[part 2 of 12: package /E40_Platform_System_SystemPackage/Components]
AUTOSAR XML (schema 4-2-1)
package /E40_Platform_System_SystemPackage/Components  (continued)
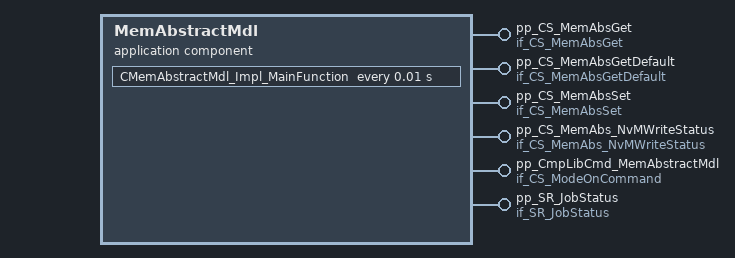
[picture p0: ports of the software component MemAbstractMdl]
  application sw component type MemAbstractMdl
    6 x provide port:
      pp_CS_MemAbsGet: provided-interface=if_CS_MemAbsGet
        provided-com-specs:
          operation=Get_BsConst_Audio_Element, queue-length=1
          operation=Get_BsConst_BsConst_Illumination_ReservedByte, queue-length=1
          operation=Get_BsConst_BsConst_Illumination_ReservedByte_SafeCopy1, queue-length=1
          operation=Get_BsConst_BsConst_Illumination_ReservedByte_SafeCopy2, queue-length=1
          operation=Get_BsConst_Communication_Element, queue-length=1
          operation=Get_BsConst_Compensation_Line_Shift_b, queue-length=1
          operation=Get_BsConst_Compensation_Line_Shift_b_SafeCopy1, queue-length=1
          operation=Get_BsConst_Compensation_Line_Shift_b_SafeCopy2, queue-length=1
          operation=Get_BsConst_Compensation_Line_Slope_m, queue-length=1
          operation=Get_BsConst_Compensation_Line_Slope_m_SafeCopy1, queue-length=1
          operation=Get_BsConst_Compensation_Line_Slope_m_SafeCopy2, queue-length=1
          operation=Get_BsConst_Derating_Backlight_Disable, queue-length=1
          operation=Get_BsConst_Derating_Backlight_Disable_SafeCopy1, queue-length=1
          operation=Get_BsConst_Derating_Backlight_Disable_SafeCopy2, queue-length=1
          operation=Get_BsConst_Display_Illum_Max_Level, queue-length=1
          operation=Get_BsConst_Display_Illum_Max_Level_SafeCopy1, queue-length=1
          operation=Get_BsConst_Display_Illum_Max_Level_SafeCopy2, queue-length=1
          operation=Get_BsConst_EngOffTimer_Element, queue-length=1
          operation=Get_BsConst_FuelGauge_Element, queue-length=1
          operation=Get_BsConst_Lookup_Curve_HotSpot_Coef_X, queue-length=1
          operation=Get_BsConst_Lookup_Curve_HotSpot_Coef_X_SafeCopy1, queue-length=1
          operation=Get_BsConst_Lookup_Curve_HotSpot_Coef_X_SafeCopy2, queue-length=1
          operation=Get_BsConst_Lookup_Curve_HotSpot_Coef_Y, queue-length=1
          operation=Get_BsConst_Lookup_Curve_HotSpot_Coef_Y_SafeCopy1, queue-length=1
          operation=Get_BsConst_Lookup_Curve_HotSpot_Coef_Y_SafeCopy2, queue-length=1
          operation=Get_BsConst_OilGauge_Element, queue-length=1
          operation=Get_BsConst_PCB_Temperature_Sensor_Conv, queue-length=1
          operation=Get_BsConst_PCB_Temperature_Sensor_Conv_SafeCopy1, queue-length=1
          operation=Get_BsConst_PCB_Temperature_Sensor_Conv_SafeCopy2, queue-length=1
          operation=Get_BsConst_PWM_boost_bypass_duty, queue-length=1
          operation=Get_BsConst_PWM_boost_bypass_duty_SafeCopy1, queue-length=1
          operation=Get_BsConst_PWM_boost_bypass_duty_SafeCopy2, queue-length=1
          operation=Get_BsConst_PowerGauge_Element, queue-length=1
          operation=Get_BsConst_Power_Element, queue-length=1
          operation=Get_BsConst_RealTimeClock_Element, queue-length=1
          operation=Get_BsConst_ServiceReminder_Element, queue-length=1
          operation=Get_BsConst_SpeedoGauge_Element, queue-length=1
          operation=Get_BsConst_TachoGauge_Element, queue-length=1
          operation=Get_BsConst_TempGauge_Element, queue-length=1
          operation=Get_BsConst_Temp_Threshold_Hysteresis_Derating, queue-length=1
          operation=Get_BsConst_Temp_Threshold_Hysteresis_Derating_SafeCopy1, queue-length=1
          operation=Get_BsConst_Temp_Threshold_Hysteresis_Derating_SafeCopy2, queue-length=1
          operation=Get_BsConst_Temperature_Sensor_Conv, queue-length=1
          operation=Get_BsConst_Temperature_Sensor_Conv_SafeCopy1, queue-length=1
          operation=Get_BsConst_Temperature_Sensor_Conv_SafeCopy2, queue-length=1
          operation=Get_BsConst_TripComputer_Element, queue-length=1
          operation=Get_BsConst_Warning_Element, queue-length=1
          operation=Get_BsCys_Certicificate_Element, queue-length=1
          operation=Get_BsDiag_Dtc_Element, queue-length=1
          operation=Get_BsDiag_ErrorRecord_Element, queue-length=1
          operation=Get_BsReten_Audio_Element, queue-length=1
          operation=Get_BsReten_Communication_Element, queue-length=1
          operation=Get_BsReten_Display_Element, queue-length=1
          operation=Get_BsReten_Gauges_Element, queue-length=1
          operation=Get_BsReten_Illumination_Element, queue-length=1
          operation=Get_BsReten_Odometer_Element, queue-length=1
          operation=Get_BsReten_Personalization_Element, queue-length=1
          operation=Get_BsReten_Power_Element, queue-length=1
          operation=Get_BsReten_RealTimeClock_Element, queue-length=1
          operation=Get_BsReten_Tripcomputer_Element, queue-length=1
          operation=Get_BsReten_Warning_Element, queue-length=1
          operation=Get_BsRt_CusDlt_Element, queue-length=1
          operation=Get_BsRt_FuelGauge_Element, queue-length=1
          operation=Get_BsRt_Illumination_Element, queue-length=1
          operation=Get_BsRt_Odometer_Element, queue-length=1
          operation=Get_BsRt_OilGauge_Element, queue-length=1
          operation=Get_BsRt_Personalization_Element, queue-length=1
          operation=Get_BsRt_PowerGauge_Element, queue-length=1
          operation=Get_BsRt_RealTimeClock_Element, queue-length=1
          operation=Get_BsRt_SpeedoGauge_Element, queue-length=1
          operation=Get_BsRt_TachoGauge_Element, queue-length=1
          operation=Get_BsRt_TempGauge_Element, queue-length=1
          operation=Get_BsRt_TripComputer_Element, queue-length=1
          operation=Get_BsRt_Warning_Element, queue-length=1
          operation=Get_BsShare_AssemblyManufacturingDate, queue-length=1
          operation=Get_BsShare_AssemblyPlantNumber, queue-length=1
          operation=Get_BsShare_EcuPartNumber_Element, queue-length=1
          operation=Get_BsShare_HWModification, queue-length=1
          operation=Get_BsShare_PCBSerialNumber, queue-length=1
          operation=Get_BsShare_ProductSerialNumber, queue-length=1
          operation=Get_BsShare_SMTManufacturingDate, queue-length=1
          operation=Get_BsShare_SMTPlantNumber, queue-length=1
          operation=Get_BsShare_SwUpdFotaFinPrint_Element, queue-length=1
          operation=Get_BsShare_SwUpdFotaMode_Element, queue-length=1
          operation=Get_BsShare_SwUpdFotaStatus_Element, queue-length=1
          operation=Get_BsShare_SwUpdFotadecrypt_Element, queue-length=1
          operation=Get_BsShare_SwUpdReflash_Element, queue-length=1
          operation=Get_BsShare_VehicleConfig_Element, queue-length=1
          operation=Get_BsShare_VisMeet_EOLEntry_Element, queue-length=1
          operation=Get_BsShare_VisMeet_Element, queue-length=1
          operation=Get_BsShare_VisteonPCBPartNumber, queue-length=1
          operation=Get_BsShare_VisteonPartNumber, queue-length=1
          operation=Get_RefCys_Certicificate1_Element, queue-length=1
          operation=Get_RefCys_Certicificate_Element, queue-length=1
      pp_CS_MemAbsGetDefault: provided-interface=if_CS_MemAbsGetDefault
        provided-com-specs:
          operation=Get_Default_BsConst_Audio_Element, queue-length=1
          operation=Get_Default_BsConst_BsConst_Illumination_ReservedByte, queue-length=1
          operation=Get_Default_BsConst_BsConst_Illumination_ReservedByte_SafeCopy1, queue-length=1
          operation=Get_Default_BsConst_BsConst_Illumination_ReservedByte_SafeCopy2, queue-length=1
          operation=Get_Default_BsConst_Communication_Element, queue-length=1
          operation=Get_Default_BsConst_Compensation_Line_Shift_b, queue-length=1
          operation=Get_Default_BsConst_Compensation_Line_Shift_b_SafeCopy1, queue-length=1
          operation=Get_Default_BsConst_Compensation_Line_Shift_b_SafeCopy2, queue-length=1
          operation=Get_Default_BsConst_Compensation_Line_Slope_m, queue-length=1
          operation=Get_Default_BsConst_Compensation_Line_Slope_m_SafeCopy1, queue-length=1
          operation=Get_Default_BsConst_Compensation_Line_Slope_m_SafeCopy2, queue-length=1
          operation=Get_Default_BsConst_Derating_Backlight_Disable, queue-length=1
          operation=Get_Default_BsConst_Derating_Backlight_Disable_SafeCopy1, queue-length=1
          operation=Get_Default_BsConst_Derating_Backlight_Disable_SafeCopy2, queue-length=1
          operation=Get_Default_BsConst_Display_Illum_Max_Level, queue-length=1
          operation=Get_Default_BsConst_Display_Illum_Max_Level_SafeCopy1, queue-length=1
          operation=Get_Default_BsConst_Display_Illum_Max_Level_SafeCopy2, queue-length=1
          operation=Get_Default_BsConst_EngOffTimer_Element, queue-length=1
          operation=Get_Default_BsConst_FuelGauge_Element, queue-length=1
          operation=Get_Default_BsConst_Lookup_Curve_HotSpot_Coef_X, queue-length=1
          operation=Get_Default_BsConst_Lookup_Curve_HotSpot_Coef_X_SafeCopy1, queue-length=1
          operation=Get_Default_BsConst_Lookup_Curve_HotSpot_Coef_X_SafeCopy2, queue-length=1
          operation=Get_Default_BsConst_Lookup_Curve_HotSpot_Coef_Y, queue-length=1
          operation=Get_Default_BsConst_Lookup_Curve_HotSpot_Coef_Y_SafeCopy1, queue-length=1
          operation=Get_Default_BsConst_Lookup_Curve_HotSpot_Coef_Y_SafeCopy2, queue-length=1
          operation=Get_Default_BsConst_OilGauge_Element, queue-length=1
          operation=Get_Default_BsConst_PCB_Temperature_Sensor_Conv, queue-length=1
          operation=Get_Default_BsConst_PCB_Temperature_Sensor_Conv_SafeCopy1, queue-length=1
          operation=Get_Default_BsConst_PCB_Temperature_Sensor_Conv_SafeCopy2, queue-length=1
          operation=Get_Default_BsConst_PWM_boost_bypass_duty, queue-length=1
          operation=Get_Default_BsConst_PWM_boost_bypass_duty_SafeCopy1, queue-length=1
          operation=Get_Default_BsConst_PWM_boost_bypass_duty_SafeCopy2, queue-length=1
          operation=Get_Default_BsConst_PowerGauge_Element, queue-length=1
          operation=Get_Default_BsConst_Power_Element, queue-length=1
          operation=Get_Default_BsConst_RealTimeClock_Element, queue-length=1
          operation=Get_Default_BsConst_ServiceReminder_Element, queue-length=1
          operation=Get_Default_BsConst_SpeedoGauge_Element, queue-length=1
          operation=Get_Default_BsConst_TachoGauge_Element, queue-length=1
          operation=Get_Default_BsConst_TempGauge_Element, queue-length=1
          operation=Get_Default_BsConst_Temp_Threshold_Hysteresis_Derating, queue-length=1
          operation=Get_Default_BsConst_Temp_Threshold_Hysteresis_Derating_SafeCopy1, queue-length=1
          operation=Get_Default_BsConst_Temp_Threshold_Hysteresis_Derating_SafeCopy2, queue-length=1
          operation=Get_Default_BsConst_Temperature_Sensor_Conv, queue-length=1
          operation=Get_Default_BsConst_Temperature_Sensor_Conv_SafeCopy1, queue-length=1
          operation=Get_Default_BsConst_Temperature_Sensor_Conv_SafeCopy2, queue-length=1
          operation=Get_Default_BsConst_TripComputer_Element, queue-length=1
          operation=Get_Default_BsConst_Warning_Element, queue-length=1
          operation=Get_Default_BsCys_Certicificate_Element, queue-length=1
          operation=Get_Default_BsDiag_Dtc_Element, queue-length=1
          operation=Get_Default_BsDiag_ErrorRecord_Element, queue-length=1
          operation=Get_Default_BsReten_Audio_Element, queue-length=1
          operation=Get_Default_BsReten_Communication_Element, queue-length=1
          operation=Get_Default_BsReten_Display_Element, queue-length=1
          operation=Get_Default_BsReten_Gauges_Element, queue-length=1
          operation=Get_Default_BsReten_Illumination_Element, queue-length=1
          operation=Get_Default_BsReten_Odometer_Element, queue-length=1
          operation=Get_Default_BsReten_Personalization_Element, queue-length=1
          operation=Get_Default_BsReten_Power_Element, queue-length=1
          operation=Get_Default_BsReten_RealTimeClock_Element, queue-length=1
          operation=Get_Default_BsReten_Tripcomputer_Element, queue-length=1
          operation=Get_Default_BsReten_Warning_Element, queue-length=1
          operation=Get_Default_BsRt_CusDlt_Element, queue-length=1
          operation=Get_Default_BsRt_FuelGauge_Element, queue-length=1
          operation=Get_Default_BsRt_Illumination_Element, queue-length=1
          operation=Get_Default_BsRt_Odometer_Element, queue-length=1
          operation=Get_Default_BsRt_OilGauge_Element, queue-length=1
          operation=Get_Default_BsRt_Personalization_Element, queue-length=1
          operation=Get_Default_BsRt_PowerGauge_Element, queue-length=1
          operation=Get_Default_BsRt_RealTimeClock_Element, queue-length=1
          operation=Get_Default_BsRt_SpeedoGauge_Element, queue-length=1
          operation=Get_Default_BsRt_TachoGauge_Element, queue-length=1
          operation=Get_Default_BsRt_TempGauge_Element, queue-length=1
          operation=Get_Default_BsRt_TripComputer_Element, queue-length=1
          operation=Get_Default_BsRt_Warning_Element, queue-length=1
          operation=Get_Default_BsShare_AssemblyManufacturingDate, queue-length=1
          operation=Get_Default_BsShare_AssemblyPlantNumber, queue-length=1
          operation=Get_Default_BsShare_EcuPartNumber_Element, queue-length=1
          operation=Get_Default_BsShare_HWModification, queue-length=1
          operation=Get_Default_BsShare_PCBSerialNumber, queue-length=1
          operation=Get_Default_BsShare_ProductSerialNumber, queue-length=1
          operation=Get_Default_BsShare_SMTManufacturingDate, queue-length=1
          operation=Get_Default_BsShare_SMTPlantNumber, queue-length=1
          operation=Get_Default_BsShare_SwUpdFotaFinPrint_Element, queue-length=1
          operation=Get_Default_BsShare_SwUpdFotaMode_Element, queue-length=1
          operation=Get_Default_BsShare_SwUpdFotaStatus_Element, queue-length=1
          operation=Get_Default_BsShare_SwUpdFotadecrypt_Element, queue-length=1
          operation=Get_Default_BsShare_SwUpdReflash_Element, queue-length=1
          operation=Get_Default_BsShare_VehicleConfig_Element, queue-length=1
          operation=Get_Default_BsShare_VisMeet_EOLEntry_Element, queue-length=1
          operation=Get_Default_BsShare_VisMeet_Element, queue-length=1
          operation=Get_Default_BsShare_VisteonPCBPartNumber, queue-length=1
          operation=Get_Default_BsShare_VisteonPartNumber, queue-length=1
          operation=Get_Default_RefCys_Certicificate1_Element, queue-length=1
          operation=Get_Default_RefCys_Certicificate_Element, queue-length=1
      pp_CS_MemAbsSet: provided-interface=if_CS_MemAbsSet
        provided-com-specs:
          operation=Set_BsConst_Audio_Element, queue-length=1
          operation=Set_BsConst_BsConst_Illumination_ReservedByte, queue-length=1
          operation=Set_BsConst_BsConst_Illumination_ReservedByte_SafeCopy1, queue-length=1
          operation=Set_BsConst_BsConst_Illumination_ReservedByte_SafeCopy2, queue-length=1
          operation=Set_BsConst_Communication_Element, queue-length=1
          operation=Set_BsConst_Compensation_Line_Shift_b, queue-length=1
          operation=Set_BsConst_Compensation_Line_Shift_b_SafeCopy1, queue-length=1
          operation=Set_BsConst_Compensation_Line_Shift_b_SafeCopy2, queue-length=1
          operation=Set_BsConst_Compensation_Line_Slope_m, queue-length=1
          operation=Set_BsConst_Compensation_Line_Slope_m_SafeCopy1, queue-length=1
          operation=Set_BsConst_Compensation_Line_Slope_m_SafeCopy2, queue-length=1
          operation=Set_BsConst_Derating_Backlight_Disable, queue-length=1
          operation=Set_BsConst_Derating_Backlight_Disable_SafeCopy1, queue-length=1
          operation=Set_BsConst_Derating_Backlight_Disable_SafeCopy2, queue-length=1
          operation=Set_BsConst_Display_Illum_Max_Level, queue-length=1
          operation=Set_BsConst_Display_Illum_Max_Level_SafeCopy1, queue-length=1
          operation=Set_BsConst_Display_Illum_Max_Level_SafeCopy2, queue-length=1
          operation=Set_BsConst_EngOffTimer_Element, queue-length=1
          operation=Set_BsConst_FuelGauge_Element, queue-length=1
          operation=Set_BsConst_Lookup_Curve_HotSpot_Coef_X, queue-length=1
          operation=Set_BsConst_Lookup_Curve_HotSpot_Coef_X_SafeCopy1, queue-length=1
          operation=Set_BsConst_Lookup_Curve_HotSpot_Coef_X_SafeCopy2, queue-length=1
          operation=Set_BsConst_Lookup_Curve_HotSpot_Coef_Y, queue-length=1
          operation=Set_BsConst_Lookup_Curve_HotSpot_Coef_Y_SafeCopy1, queue-length=1
          operation=Set_BsConst_Lookup_Curve_HotSpot_Coef_Y_SafeCopy2, queue-length=1
          operation=Set_BsConst_OilGauge_Element, queue-length=1
          operation=Set_BsConst_PCB_Temperature_Sensor_Conv, queue-length=1
          operation=Set_BsConst_PCB_Temperature_Sensor_Conv_SafeCopy1, queue-length=1
          operation=Set_BsConst_PCB_Temperature_Sensor_Conv_SafeCopy2, queue-length=1
          operation=Set_BsConst_PWM_boost_bypass_duty, queue-length=1
          operation=Set_BsConst_PWM_boost_bypass_duty_SafeCopy1, queue-length=1
          operation=Set_BsConst_PWM_boost_bypass_duty_SafeCopy2, queue-length=1
          operation=Set_BsConst_PowerGauge_Element, queue-length=1
          operation=Set_BsConst_Power_Element, queue-length=1
          operation=Set_BsConst_RealTimeClock_Element, queue-length=1
          operation=Set_BsConst_ServiceReminder_Element, queue-length=1
          operation=Set_BsConst_SpeedoGauge_Element, queue-length=1
          operation=Set_BsConst_TachoGauge_Element, queue-length=1
          operation=Set_BsConst_TempGauge_Element, queue-length=1
          operation=Set_BsConst_Temp_Threshold_Hysteresis_Derating, queue-length=1
          operation=Set_BsConst_Temp_Threshold_Hysteresis_Derating_SafeCopy1, queue-length=1
          operation=Set_BsConst_Temp_Threshold_Hysteresis_Derating_SafeCopy2, queue-length=1
          operation=Set_BsConst_Temperature_Sensor_Conv, queue-length=1
          operation=Set_BsConst_Temperature_Sensor_Conv_SafeCopy1, queue-length=1
          operation=Set_BsConst_Temperature_Sensor_Conv_SafeCopy2, queue-length=1
          operation=Set_BsConst_TripComputer_Element, queue-length=1
          operation=Set_BsConst_Warning_Element, queue-length=1
          operation=Set_BsCys_Certicificate_Element, queue-length=1
          operation=Set_BsDiag_Dtc_Element, queue-length=1
          operation=Set_BsDiag_ErrorRecord_Element, queue-length=1
          operation=Set_BsReten_Audio_Element, queue-length=1
          operation=Set_BsReten_Communication_Element, queue-length=1
          operation=Set_BsReten_Display_Element, queue-length=1
          operation=Set_BsReten_Gauges_Element, queue-length=1
          operation=Set_BsReten_Illumination_Element, queue-length=1
          operation=Set_BsReten_Odometer_Element, queue-length=1
          operation=Set_BsReten_Personalization_Element, queue-length=1
          operation=Set_BsReten_Power_Element, queue-length=1
          operation=Set_BsReten_RealTimeClock_Element, queue-length=1
          operation=Set_BsReten_Tripcomputer_Element, queue-length=1
          operation=Set_BsReten_Warning_Element, queue-length=1
          operation=Set_BsRt_CusDlt_Element, queue-length=1
          operation=Set_BsRt_FuelGauge_Element, queue-length=1
          operation=Set_BsRt_Illumination_Element, queue-length=1
          operation=Set_BsRt_Odometer_Element, queue-length=1
          operation=Set_BsRt_OilGauge_Element, queue-length=1
          operation=Set_BsRt_Personalization_Element, queue-length=1
          operation=Set_BsRt_PowerGauge_Element, queue-length=1
          operation=Set_BsRt_RealTimeClock_Element, queue-length=1
          operation=Set_BsRt_SpeedoGauge_Element, queue-length=1
          operation=Set_BsRt_TachoGauge_Element, queue-length=1
          operation=Set_BsRt_TempGauge_Element, queue-length=1
          operation=Set_BsRt_TripComputer_Element, queue-length=1
          operation=Set_BsRt_Warning_Element, queue-length=1
          operation=Set_BsShare_AssemblyManufacturingDate, queue-length=1
          operation=Set_BsShare_AssemblyPlantNumber, queue-length=1
          operation=Set_BsShare_EcuPartNumber_Element, queue-length=1
          operation=Set_BsShare_HWModification, queue-length=1
          operation=Set_BsShare_PCBSerialNumber, queue-length=1
          operation=Set_BsShare_ProductSerialNumber, queue-length=1
          operation=Set_BsShare_SMTManufacturingDate, queue-length=1
          operation=Set_BsShare_SMTPlantNumber, queue-length=1
          operation=Set_BsShare_SwUpdFotaFinPrint_Element, queue-length=1
          operation=Set_BsShare_SwUpdFotaMode_Element, queue-length=1
          operation=Set_BsShare_SwUpdFotaStatus_Element, queue-length=1
          operation=Set_BsShare_SwUpdFotadecrypt_Element, queue-length=1
          operation=Set_BsShare_SwUpdReflash_Element, queue-length=1
          operation=Set_BsShare_VehicleConfig_Element, queue-length=1
          operation=Set_BsShare_VisMeet_EOLEntry_Element, queue-length=1
          operation=Set_BsShare_VisMeet_Element, queue-length=1
          operation=Set_BsShare_VisteonPCBPartNumber, queue-length=1
          operation=Set_BsShare_VisteonPartNumber, queue-length=1
          operation=Set_RefCys_Certicificate1_Element, queue-length=1
          operation=Set_RefCys_Certicificate_Element, queue-length=1
      pp_CS_MemAbs_NvMWriteStatus: server-com-spec{operation=NvmWriteStatus, queue-length=1}, provided-interface=if_CS_MemAbs_NvMWriteStatus
      pp_CmpLibCmd_MemAbstractMdl: server-com-spec{operation=Impl_OnCommand, queue-length=1}, provided-interface=if_CS_ModeOnCommand
      pp_SR_JobStatus: provided-interface=if_SR_JobStatus
        provided-com-specs:
          data-element=JobStatus_BsConst_Audio_Element, init-value=constant-reference=MemAbstractMdlJobStatus_BsConst_Audio_ElementValue0
          data-element=JobStatus_BsConst_BsConst_Illumination_ReservedByte, init-value=constant-reference=MemAbstractMdlJobStatus_BsConst_BsConst_Illumination_ReservedByteValue0
          data-element=JobStatus_BsConst_BsConst_Illumination_ReservedByte_SafeCopy1, init-value=constant-reference=MemAbstractMdlJobStatus_BsConst_BsConst_Illumination_ReservedByte_SafeCopy1Value0
          data-element=JobStatus_BsConst_BsConst_Illumination_ReservedByte_SafeCopy2, init-value=constant-reference=MemAbstractMdlJobStatus_BsConst_BsConst_Illumination_ReservedByte_SafeCopy2Value0
          data-element=JobStatus_BsConst_Communication_Element, init-value=constant-reference=MemAbstractMdlJobStatus_BsConst_Communication_ElementValue0
          data-element=JobStatus_BsConst_Compensation_Line_Shift_b, init-value=constant-reference=MemAbstractMdlJobStatus_BsConst_Compensation_Line_Shift_bValue0
          data-element=JobStatus_BsConst_Compensation_Line_Shift_b_SafeCopy1, init-value=constant-reference=MemAbstractMdlJobStatus_BsConst_Compensation_Line_Shift_b_SafeCopy1Value0
          data-element=JobStatus_BsConst_Compensation_Line_Shift_b_SafeCopy2, init-value=constant-reference=MemAbstractMdlJobStatus_BsConst_Compensation_Line_Shift_b_SafeCopy2Value0
          data-element=JobStatus_BsConst_Compensation_Line_Slope_m, init-value=constant-reference=MemAbstractMdlJobStatus_BsConst_Compensation_Line_Slope_mValue0
          data-element=JobStatus_BsConst_Compensation_Line_Slope_m_SafeCopy1, init-value=constant-reference=MemAbstractMdlJobStatus_BsConst_Compensation_Line_Slope_m_SafeCopy1Value0
          data-element=JobStatus_BsConst_Compensation_Line_Slope_m_SafeCopy2, init-value=constant-reference=MemAbstractMdlJobStatus_BsConst_Compensation_Line_Slope_m_SafeCopy2Value0
          data-element=JobStatus_BsConst_Derating_Backlight_Disable, init-value=constant-reference=MemAbstractMdlJobStatus_BsConst_Derating_Backlight_DisableValue0
          data-element=JobStatus_BsConst_Derating_Backlight_Disable_SafeCopy1, init-value=constant-reference=MemAbstractMdlJobStatus_BsConst_Derating_Backlight_Disable_SafeCopy1Value0
          data-element=JobStatus_BsConst_Derating_Backlight_Disable_SafeCopy2, init-value=constant-reference=MemAbstractMdlJobStatus_BsConst_Derating_Backlight_Disable_SafeCopy2Value0
          data-element=JobStatus_BsConst_Display_Illum_Max_Level, init-value=constant-reference=MemAbstractMdlJobStatus_BsConst_Display_Illum_Max_LevelValue0
          data-element=JobStatus_BsConst_Display_Illum_Max_Level_SafeCopy1, init-value=constant-reference=MemAbstractMdlJobStatus_BsConst_Display_Illum_Max_Level_SafeCopy1Value0
          data-element=JobStatus_BsConst_Display_Illum_Max_Level_SafeCopy2, init-value=constant-reference=MemAbstractMdlJobStatus_BsConst_Display_Illum_Max_Level_SafeCopy2Value0
          data-element=JobStatus_BsConst_EngOffTimer_Element, init-value=constant-reference=MemAbstractMdlJobStatus_BsConst_EngOffTimer_ElementValue0
          data-element=JobStatus_BsConst_FuelGauge_Element, init-value=constant-reference=MemAbstractMdlJobStatus_BsConst_FuelGauge_ElementValue0
          data-element=JobStatus_BsConst_Lookup_Curve_HotSpot_Coef_X, init-value=constant-reference=MemAbstractMdlJobStatus_BsConst_Lookup_Curve_HotSpot_Coef_XValue0
          data-element=JobStatus_BsConst_Lookup_Curve_HotSpot_Coef_X_SafeCopy1, init-value=constant-reference=MemAbstractMdlJobStatus_BsConst_Lookup_Curve_HotSpot_Coef_X_SafeCopy1Value0
          data-element=JobStatus_BsConst_Lookup_Curve_HotSpot_Coef_X_SafeCopy2, init-value=constant-reference=MemAbstractMdlJobStatus_BsConst_Lookup_Curve_HotSpot_Coef_X_SafeCopy2Value0
          data-element=JobStatus_BsConst_Lookup_Curve_HotSpot_Coef_Y, init-value=constant-reference=MemAbstractMdlJobStatus_BsConst_Lookup_Curve_HotSpot_Coef_YValue0
          data-element=JobStatus_BsConst_Lookup_Curve_HotSpot_Coef_Y_SafeCopy1, init-value=constant-reference=MemAbstractMdlJobStatus_BsConst_Lookup_Curve_HotSpot_Coef_Y_SafeCopy1Value0
          data-element=JobStatus_BsConst_Lookup_Curve_HotSpot_Coef_Y_SafeCopy2, init-value=constant-reference=MemAbstractMdlJobStatus_BsConst_Lookup_Curve_HotSpot_Coef_Y_SafeCopy2Value0
          data-element=JobStatus_BsConst_OilGauge_Element, init-value=constant-reference=MemAbstractMdlJobStatus_BsConst_OilGauge_ElementValue0
          data-element=JobStatus_BsConst_PCB_Temperature_Sensor_Conv, init-value=constant-reference=MemAbstractMdlJobStatus_BsConst_PCB_Temperature_Sensor_ConvValue0
          data-element=JobStatus_BsConst_PCB_Temperature_Sensor_Conv_SafeCopy1, init-value=constant-reference=MemAbstractMdlJobStatus_BsConst_PCB_Temperature_Sensor_Conv_SafeCopy1Value0
          data-element=JobStatus_BsConst_PCB_Temperature_Sensor_Conv_SafeCopy2, init-value=constant-reference=MemAbstractMdlJobStatus_BsConst_PCB_Temperature_Sensor_Conv_SafeCopy2Value0
          data-element=JobStatus_BsConst_PWM_boost_bypass_duty, init-value=constant-reference=MemAbstractMdlJobStatus_BsConst_PWM_boost_bypass_dutyValue0
          data-element=JobStatus_BsConst_PWM_boost_bypass_duty_SafeCopy1, init-value=constant-reference=MemAbstractMdlJobStatus_BsConst_PWM_boost_bypass_duty_SafeCopy1Value0
          data-element=JobStatus_BsConst_PWM_boost_bypass_duty_SafeCopy2, init-value=constant-reference=MemAbstractMdlJobStatus_BsConst_PWM_boost_bypass_duty_SafeCopy2Value0
          data-element=JobStatus_BsConst_PowerGauge_Element, init-value=constant-reference=MemAbstractMdlJobStatus_BsConst_PowerGauge_ElementValue0
          data-element=JobStatus_BsConst_Power_Element, init-value=constant-reference=MemAbstractMdlJobStatus_BsConst_Power_ElementValue0
          data-element=JobStatus_BsConst_RealTimeClock_Element, init-value=constant-reference=MemAbstractMdlJobStatus_BsConst_RealTimeClock_ElementValue0
          data-element=JobStatus_BsConst_ServiceReminder_Element, init-value=constant-reference=MemAbstractMdlJobStatus_BsConst_ServiceReminder_ElementValue0
          data-element=JobStatus_BsConst_SpeedoGauge_Element, init-value=constant-reference=MemAbstractMdlJobStatus_BsConst_SpeedoGauge_ElementValue0
          data-element=JobStatus_BsConst_TachoGauge_Element, init-value=constant-reference=MemAbstractMdlJobStatus_BsConst_TachoGauge_ElementValue0
          data-element=JobStatus_BsConst_TempGauge_Element, init-value=constant-reference=MemAbstractMdlJobStatus_BsConst_TempGauge_ElementValue0
          data-element=JobStatus_BsConst_Temp_Threshold_Hysteresis_Derating, init-value=constant-reference=MemAbstractMdlJobStatus_BsConst_Temp_Threshold_Hysteresis_DeratingValue0
          data-element=JobStatus_BsConst_Temp_Threshold_Hysteresis_Derating_SafeCopy1, init-value=constant-reference=MemAbstractMdlJobStatus_BsConst_Temp_Threshold_Hysteresis_Derating_SafeCopy1Value0
          data-element=JobStatus_BsConst_Temp_Threshold_Hysteresis_Derating_SafeCopy2, init-value=constant-reference=MemAbstractMdlJobStatus_BsConst_Temp_Threshold_Hysteresis_Derating_SafeCopy2Value0
          data-element=JobStatus_BsConst_Temperature_Sensor_Conv, init-value=constant-reference=MemAbstractMdlJobStatus_BsConst_Temperature_Sensor_ConvValue0
          data-element=JobStatus_BsConst_Temperature_Sensor_Conv_SafeCopy1, init-value=constant-reference=MemAbstractMdlJobStatus_BsConst_Temperature_Sensor_Conv_SafeCopy1Value0
          data-element=JobStatus_BsConst_Temperature_Sensor_Conv_SafeCopy2, init-value=constant-reference=MemAbstractMdlJobStatus_BsConst_Temperature_Sensor_Conv_SafeCopy2Value0
          data-element=JobStatus_BsConst_TripComputer_Element, init-value=constant-reference=MemAbstractMdlJobStatus_BsConst_TripComputer_ElementValue0
          data-element=JobStatus_BsConst_Warning_Element, init-value=constant-reference=MemAbstractMdlJobStatus_BsConst_Warning_ElementValue0
          data-element=JobStatus_BsCys_Certicificate_Element, init-value=constant-reference=MemAbstractMdlJobStatus_BsCys_Certicificate_ElementValue0
          data-element=JobStatus_BsDiag_Dtc_Element, init-value=constant-reference=MemAbstractMdlJobStatus_BsDiag_Dtc_ElementValue0
          data-element=JobStatus_BsDiag_ErrorRecord_Element, init-value=constant-reference=MemAbstractMdlJobStatus_BsDiag_ErrorRecord_ElementValue0
          data-element=JobStatus_BsReten_Audio_Element, init-value=constant-reference=MemAbstractMdlJobStatus_BsReten_Audio_ElementValue0
          data-element=JobStatus_BsReten_Communication_Element, init-value=constant-reference=MemAbstractMdlJobStatus_BsReten_Communication_ElementValue0
          data-element=JobStatus_BsReten_Display_Element, init-value=constant-reference=MemAbstractMdlJobStatus_BsReten_Display_ElementValue0
          data-element=JobStatus_BsReten_Gauges_Element, init-value=constant-reference=MemAbstractMdlJobStatus_BsReten_Gauges_ElementValue0
          data-element=JobStatus_BsReten_Illumination_Element, init-value=constant-reference=MemAbstractMdlJobStatus_BsReten_Illumination_ElementValue0
          data-element=JobStatus_BsReten_Odometer_Element, init-value=constant-reference=MemAbstractMdlJobStatus_BsReten_Odometer_ElementValue0
          data-element=JobStatus_BsReten_Personalization_Element, init-value=constant-reference=MemAbstractMdlJobStatus_BsReten_Personalization_ElementValue0
          data-element=JobStatus_BsReten_Power_Element, init-value=constant-reference=MemAbstractMdlJobStatus_BsReten_Power_ElementValue0
          data-element=JobStatus_BsReten_RealTimeClock_Element, init-value=constant-reference=MemAbstractMdlJobStatus_BsReten_RealTimeClock_ElementValue0
          data-element=JobStatus_BsReten_Tripcomputer_Element, init-value=constant-reference=MemAbstractMdlJobStatus_BsReten_Tripcomputer_ElementValue0
          data-element=JobStatus_BsReten_Warning_Element, init-value=constant-reference=MemAbstractMdlJobStatus_BsReten_Warning_ElementValue0
          data-element=JobStatus_BsRt_CusDlt_Element, init-value=constant-reference=MemAbstractMdlJobStatus_BsRt_CusDlt_ElementValue0
          data-element=JobStatus_BsRt_FuelGauge_Element, init-value=constant-reference=MemAbstractMdlJobStatus_BsRt_FuelGauge_ElementValue0
          data-element=JobStatus_BsRt_Illumination_Element, init-value=constant-reference=MemAbstractMdlJobStatus_BsRt_Illumination_ElementValue0
          data-element=JobStatus_BsRt_Odometer_Element, init-value=constant-reference=MemAbstractMdlJobStatus_BsRt_Odometer_ElementValue0
          data-element=JobStatus_BsRt_OilGauge_Element, init-value=constant-reference=MemAbstractMdlJobStatus_BsRt_OilGauge_ElementValue0
          data-element=JobStatus_BsRt_Personalization_Element, init-value=constant-reference=MemAbstractMdlJobStatus_BsRt_Personalization_ElementValue0
          data-element=JobStatus_BsRt_PowerGauge_Element, init-value=constant-reference=MemAbstractMdlJobStatus_BsRt_PowerGauge_ElementValue0
          data-element=JobStatus_BsRt_RealTimeClock_Element, init-value=constant-reference=MemAbstractMdlJobStatus_BsRt_RealTimeClock_ElementValue0
          data-element=JobStatus_BsRt_SpeedoGauge_Element, init-value=constant-reference=MemAbstractMdlJobStatus_BsRt_SpeedoGauge_ElementValue0
          data-element=JobStatus_BsRt_TachoGauge_Element, init-value=constant-reference=MemAbstractMdlJobStatus_BsRt_TachoGauge_ElementValue0
          data-element=JobStatus_BsRt_TempGauge_Element, init-value=constant-reference=MemAbstractMdlJobStatus_BsRt_TempGauge_ElementValue0
          data-element=JobStatus_BsRt_TripComputer_Element, init-value=constant-reference=MemAbstractMdlJobStatus_BsRt_TripComputer_ElementValue0
          data-element=JobStatus_BsRt_Warning_Element, init-value=constant-reference=MemAbstractMdlJobStatus_BsRt_Warning_ElementValue0
          data-element=JobStatus_BsShare_AssemblyManufacturingDate, init-value=constant-reference=MemAbstractMdlJobStatus_BsShare_AssemblyManufacturingDateValue0
          data-element=JobStatus_BsShare_AssemblyPlantNumber, init-value=constant-reference=MemAbstractMdlJobStatus_BsShare_AssemblyPlantNumberValue0
          data-element=JobStatus_BsShare_EcuPartNumber_Element, init-value=constant-reference=MemAbstractMdlJobStatus_BsShare_EcuPartNumber_ElementValue0
          data-element=JobStatus_BsShare_HWModification, init-value=constant-reference=MemAbstractMdlJobStatus_BsShare_HWModificationValue0
          data-element=JobStatus_BsShare_PCBSerialNumber, init-value=constant-reference=MemAbstractMdlJobStatus_BsShare_PCBSerialNumberValue0
          data-element=JobStatus_BsShare_ProductSerialNumber, init-value=constant-reference=MemAbstractMdlJobStatus_BsShare_ProductSerialNumberValue0
          data-element=JobStatus_BsShare_SMTManufacturingDate, init-value=constant-reference=MemAbstractMdlJobStatus_BsShare_SMTManufacturingDateValue0
          data-element=JobStatus_BsShare_SMTPlantNumber, init-value=constant-reference=MemAbstractMdlJobStatus_BsShare_SMTPlantNumberValue0
          data-element=JobStatus_BsShare_SwUpdFotaFinPrint_Element, init-value=constant-reference=MemAbstractMdlJobStatus_BsShare_SwUpdFotaFinPrint_ElementValue0
          data-element=JobStatus_BsShare_SwUpdFotaMode_Element, init-value=constant-reference=MemAbstractMdlJobStatus_BsShare_SwUpdFotaMode_ElementValue0
          data-element=JobStatus_BsShare_SwUpdFotaStatus_Element, init-value=constant-reference=MemAbstractMdlJobStatus_BsShare_SwUpdFotaStatus_ElementValue0
          data-element=JobStatus_BsShare_SwUpdFotadecrypt_Element, init-value=constant-reference=MemAbstractMdlJobStatus_BsShare_SwUpdFotadecrypt_ElementValue0
          data-element=JobStatus_BsShare_SwUpdReflash_Element, init-value=constant-reference=MemAbstractMdlJobStatus_BsShare_SwUpdReflash_ElementValue0
          data-element=JobStatus_BsShare_VehicleConfig_Element, init-value=constant-reference=MemAbstractMdlJobStatus_BsShare_VehicleConfig_ElementValue0
          data-element=JobStatus_BsShare_VisMeet_EOLEntry_Element, init-value=constant-reference=MemAbstractMdlJobStatus_BsShare_VisMeet_EOLEntry_ElementValue0
          data-element=JobStatus_BsShare_VisMeet_Element, init-value=constant-reference=MemAbstractMdlJobStatus_BsShare_VisMeet_ElementValue0
          data-element=JobStatus_BsShare_VisteonPCBPartNumber, init-value=constant-reference=MemAbstractMdlJobStatus_BsShare_VisteonPCBPartNumberValue0
          data-element=JobStatus_BsShare_VisteonPartNumber, init-value=constant-reference=MemAbstractMdlJobStatus_BsShare_VisteonPartNumberValue0
          data-element=JobStatus_RefCys_Certicificate1_Element, init-value=constant-reference=MemAbstractMdlJobStatus_RefCys_Certicificate1_ElementValue0
          data-element=JobStatus_RefCys_Certicificate_Element, init-value=constant-reference=MemAbstractMdlJobStatus_RefCys_Certicificate_ElementValue0
    behavior IB_MemAbstractMdl
      timing event TECMemAbstractMdl_Impl_MainFunction: start-on-event=CMemAbstractMdl_Impl_MainFunction, period=0.01
      284 x operation invoked event:
        OIE_pp_CmpLibCmd_MemAbstractMdl_CMemAbstractMdl_Impl_OnCommandTrigByImpl_OnCommand: start-on-event=CMemAbstractMdl_Impl_OnCommand, operation=pp_CmpLibCmd_MemAbstractMdl.Impl_OnCommand
        OIE_pp_CS_MemAbsGet_MemAbstractMdl_Get_BsConst_Audio_ElementTrigByGet_BsConst_Audio_Element: start-on-event=MemAbstractMdl_Get_BsConst_Audio_Element, operation=pp_CS_MemAbsGet.Get_BsConst_Audio_Element
        OperationInvokeEvent_1: start-on-event=MemAbstractMdl_Get_BsConst_BsConst_Illumination_ReservedByte, operation=pp_CS_MemAbsGet.Get_BsConst_BsConst_Illumination_ReservedByte
        OperationInvokeEvent_2: start-on-event=MemAbstractMdl_Get_BsConst_BsConst_Illumination_ReservedByte_SafeCopy1, operation=pp_CS_MemAbsGet.Get_BsConst_BsConst_Illumination_ReservedByte_SafeCopy1
        OperationInvokeEvent_3: start-on-event=MemAbstractMdl_Get_BsConst_BsConst_Illumination_ReservedByte_SafeCopy2, operation=pp_CS_MemAbsGet.Get_BsConst_BsConst_Illumination_ReservedByte_SafeCopy2
        OIE_pp_CS_MemAbsGet_MemAbstractMdl_Get_BsConst_Communication_ElementTrigByGet_BsConst_Communication_Element: start-on-event=MemAbstractMdl_Get_BsConst_Communication_Element, operation=pp_CS_MemAbsGet.Get_BsConst_Communication_Element
        OIE_pp_CS_MemAbsGet_MemAbstractMdl_Get_BsConst_Compensation_Line_Shift_bTrigByGet_BsConst_Compensation_Line_Shift_b: start-on-event=MemAbstractMdl_Get_BsConst_Compensation_Line_Shift_b, operation=pp_CS_MemAbsGet.Get_BsConst_Compensation_Line_Shift_b
        OperationInvokeEvent_4: start-on-event=MemAbstractMdl_Get_BsConst_Compensation_Line_Shift_b_SafeCopy1, operation=pp_CS_MemAbsGet.Get_BsConst_Compensation_Line_Shift_b_SafeCopy1
        OperationInvokeEvent_5: start-on-event=MemAbstractMdl_Get_BsConst_Compensation_Line_Shift_b_SafeCopy2, operation=pp_CS_MemAbsGet.Get_BsConst_Compensation_Line_Shift_b_SafeCopy2
        OIE_pp_CS_MemAbsGet_MemAbstractMdl_Get_BsConst_Compensation_Line_Slope_mTrigByGet_BsConst_Compensation_Line_Slope_m: start-on-event=MemAbstractMdl_Get_BsConst_Compensation_Line_Slope_m, operation=pp_CS_MemAbsGet.Get_BsConst_Compensation_Line_Slope_m
        OperationInvokeEvent_6: start-on-event=MemAbstractMdl_Get_BsConst_Compensation_Line_Slope_m_SafeCopy1, operation=pp_CS_MemAbsGet.Get_BsConst_Compensation_Line_Slope_m_SafeCopy1
        OperationInvokeEvent_7: start-on-event=MemAbstractMdl_Get_BsConst_Compensation_Line_Slope_m_SafeCopy2, operation=pp_CS_MemAbsGet.Get_BsConst_Compensation_Line_Slope_m_SafeCopy2
        OIE_pp_CS_MemAbsGet_MemAbstractMdl_Get_BsConst_Derating_Backlight_DisableTrigByGet_BsConst_Derating_Backlight_Disable: start-on-event=MemAbstractMdl_Get_BsConst_Derating_Backlight_Disable, operation=pp_CS_MemAbsGet.Get_BsConst_Derating_Backlight_Disable
        OperationInvokeEvent_8: start-on-event=MemAbstractMdl_Get_BsConst_Derating_Backlight_Disable_SafeCopy1, operation=pp_CS_MemAbsGet.Get_BsConst_Derating_Backlight_Disable_SafeCopy1
        OperationInvokeEvent_9: start-on-event=MemAbstractMdl_Get_BsConst_Derating_Backlight_Disable_SafeCopy2, operation=pp_CS_MemAbsGet.Get_BsConst_Derating_Backlight_Disable_SafeCopy2
        OIE_pp_CS_MemAbsGet_MemAbstractMdl_Get_BsConst_Display_Illum_Max_LevelTrigByGet_BsConst_Display_Illum_Max_Level: start-on-event=MemAbstractMdl_Get_BsConst_Display_Illum_Max_Level, operation=pp_CS_MemAbsGet.Get_BsConst_Display_Illum_Max_Level
        OperationInvokeEvent_10: start-on-event=MemAbstractMdl_Get_BsConst_Display_Illum_Max_Level_SafeCopy1, operation=pp_CS_MemAbsGet.Get_BsConst_Display_Illum_Max_Level_SafeCopy1
        OperationInvokeEvent_11: start-on-event=MemAbstractMdl_Get_BsConst_Display_Illum_Max_Level_SafeCopy2, operation=pp_CS_MemAbsGet.Get_BsConst_Display_Illum_Max_Level_SafeCopy2
        OIE_pp_CS_MemAbsGet_MemAbstractMdl_Get_BsConst_EngOffTimer_ElementTrigByGet_BsConst_EngOffTimer_Element: start-on-event=MemAbstractMdl_Get_BsConst_EngOffTimer_Element, operation=pp_CS_MemAbsGet.Get_BsConst_EngOffTimer_Element
        OIE_pp_CS_MemAbsGet_MemAbstractMdl_Get_BsConst_FuelGauge_ElementTrigByGet_BsConst_FuelGauge_Element: start-on-event=MemAbstractMdl_Get_BsConst_FuelGauge_Element, operation=pp_CS_MemAbsGet.Get_BsConst_FuelGauge_Element
        OIE_pp_CS_MemAbsGet_MemAbstractMdl_Get_BsConst_Lookup_Curve_HotSpot_Coef_XTrigByGet_BsConst_Lookup_Curve_HotSpot_Coef_X: start-on-event=MemAbstractMdl_Get_BsConst_Lookup_Curve_HotSpot_Coef_X, operation=pp_CS_MemAbsGet.Get_BsConst_Lookup_Curve_HotSpot_Coef_X
        OperationInvokeEvent_12: start-on-event=MemAbstractMdl_Get_BsConst_Lookup_Curve_HotSpot_Coef_X_SafeCopy1, operation=pp_CS_MemAbsGet.Get_BsConst_Lookup_Curve_HotSpot_Coef_X_SafeCopy1
        OperationInvokeEvent_13: start-on-event=MemAbstractMdl_Get_BsConst_Lookup_Curve_HotSpot_Coef_X_SafeCopy2, operation=pp_CS_MemAbsGet.Get_BsConst_Lookup_Curve_HotSpot_Coef_X_SafeCopy2
        OIE_pp_CS_MemAbsGet_MemAbstractMdl_Get_BsConst_Lookup_Curve_HotSpot_Coef_YTrigByGet_BsConst_Lookup_Curve_HotSpot_Coef_Y: start-on-event=MemAbstractMdl_Get_BsConst_Lookup_Curve_HotSpot_Coef_Y, operation=pp_CS_MemAbsGet.Get_BsConst_Lookup_Curve_HotSpot_Coef_Y
        OperationInvokeEvent_14: start-on-event=MemAbstractMdl_Get_BsConst_Lookup_Curve_HotSpot_Coef_Y_SafeCopy1, operation=pp_CS_MemAbsGet.Get_BsConst_Lookup_Curve_HotSpot_Coef_Y_SafeCopy1
        OperationInvokeEvent_15: start-on-event=MemAbstractMdl_Get_BsConst_Lookup_Curve_HotSpot_Coef_Y_SafeCopy2, operation=pp_CS_MemAbsGet.Get_BsConst_Lookup_Curve_HotSpot_Coef_Y_SafeCopy2
        OIE_pp_CS_MemAbsGet_MemAbstractMdl_Get_BsConst_OilGauge_ElementTrigByGet_BsConst_OilGauge_Element: start-on-event=MemAbstractMdl_Get_BsConst_OilGauge_Element, operation=pp_CS_MemAbsGet.Get_BsConst_OilGauge_Element
        OIE_pp_CS_MemAbsGet_MemAbstractMdl_Get_BsConst_PCB_Temperature_Sensor_ConvTrigByGet_BsConst_PCB_Temperature_Sensor_Conv: start-on-event=MemAbstractMdl_Get_BsConst_PCB_Temperature_Sensor_Conv, operation=pp_CS_MemAbsGet.Get_BsConst_PCB_Temperature_Sensor_Conv
        OperationInvokeEvent_16: start-on-event=MemAbstractMdl_Get_BsConst_PCB_Temperature_Sensor_Conv_SafeCopy1, operation=pp_CS_MemAbsGet.Get_BsConst_PCB_Temperature_Sensor_Conv_SafeCopy1
        OperationInvokeEvent_17: start-on-event=MemAbstractMdl_Get_BsConst_PCB_Temperature_Sensor_Conv_SafeCopy2, operation=pp_CS_MemAbsGet.Get_BsConst_PCB_Temperature_Sensor_Conv_SafeCopy2
        OIE_pp_CS_MemAbsGet_MemAbstractMdl_Get_BsConst_PWM_boost_bypass_dutyTrigByGet_BsConst_PWM_boost_bypass_duty: start-on-event=MemAbstractMdl_Get_BsConst_PWM_boost_bypass_duty, operation=pp_CS_MemAbsGet.Get_BsConst_PWM_boost_bypass_duty
        OperationInvokeEvent_18: start-on-event=MemAbstractMdl_Get_BsConst_PWM_boost_bypass_duty_SafeCopy1, operation=pp_CS_MemAbsGet.Get_BsConst_PWM_boost_bypass_duty_SafeCopy1
        OperationInvokeEvent_19: start-on-event=MemAbstractMdl_Get_BsConst_PWM_boost_bypass_duty_SafeCopy2, operation=pp_CS_MemAbsGet.Get_BsConst_PWM_boost_bypass_duty_SafeCopy2
        OIE_pp_CS_MemAbsGet_MemAbstractMdl_Get_BsConst_PowerGauge_ElementTrigByGet_BsConst_PowerGauge_Element: start-on-event=MemAbstractMdl_Get_BsConst_PowerGauge_Element, operation=pp_CS_MemAbsGet.Get_BsConst_PowerGauge_Element
        OIE_pp_CS_MemAbsGet_MemAbstractMdl_Get_BsConst_Power_ElementTrigByGet_BsConst_Power_Element: start-on-event=MemAbstractMdl_Get_BsConst_Power_Element, operation=pp_CS_MemAbsGet.Get_BsConst_Power_Element
        OIE_pp_CS_MemAbsGet_MemAbstractMdl_Get_BsConst_RealTimeClock_ElementTrigByGet_BsConst_RealTimeClock_Element: start-on-event=MemAbstractMdl_Get_BsConst_RealTimeClock_Element, operation=pp_CS_MemAbsGet.Get_BsConst_RealTimeClock_Element
        OIE_pp_CS_MemAbsGet_MemAbstractMdl_Get_BsConst_ServiceReminder_ElementTrigByGet_BsConst_ServiceReminder_Element: start-on-event=MemAbstractMdl_Get_BsConst_ServiceReminder_Element, operation=pp_CS_MemAbsGet.Get_BsConst_ServiceReminder_Element
        OIE_pp_CS_MemAbsGet_MemAbstractMdl_Get_BsConst_SpeedoGauge_ElementTrigByGet_BsConst_SpeedoGauge_Element: start-on-event=MemAbstractMdl_Get_BsConst_SpeedoGauge_Element, operation=pp_CS_MemAbsGet.Get_BsConst_SpeedoGauge_Element
        OIE_pp_CS_MemAbsGet_MemAbstractMdl_Get_BsConst_TachoGauge_ElementTrigByGet_BsConst_TachoGauge_Element: start-on-event=MemAbstractMdl_Get_BsConst_TachoGauge_Element, operation=pp_CS_MemAbsGet.Get_BsConst_TachoGauge_Element
        OIE_pp_CS_MemAbsGet_MemAbstractMdl_Get_BsConst_TempGauge_ElementTrigByGet_BsConst_TempGauge_Element: start-on-event=MemAbstractMdl_Get_BsConst_TempGauge_Element, operation=pp_CS_MemAbsGet.Get_BsConst_TempGauge_Element
        OperationInvokeEvent_20: start-on-event=MemAbstractMdl_Get_BsConst_Temp_Threshold_Hysteresis_Derating, operation=pp_CS_MemAbsGet.Get_BsConst_Temp_Threshold_Hysteresis_Derating
        OperationInvokeEvent_21: start-on-event=MemAbstractMdl_Get_BsConst_Temp_Threshold_Hysteresis_Derating_SafeCopy1, operation=pp_CS_MemAbsGet.Get_BsConst_Temp_Threshold_Hysteresis_Derating_SafeCopy1
        OperationInvokeEvent_22: start-on-event=MemAbstractMdl_Get_BsConst_Temp_Threshold_Hysteresis_Derating_SafeCopy2, operation=pp_CS_MemAbsGet.Get_BsConst_Temp_Threshold_Hysteresis_Derating_SafeCopy2
        OIE_pp_CS_MemAbsGet_MemAbstractMdl_Get_BsConst_Temperature_Sensor_ConvTrigByGet_BsConst_Temperature_Sensor_Conv: start-on-event=MemAbstractMdl_Get_BsConst_Temperature_Sensor_Conv, operation=pp_CS_MemAbsGet.Get_BsConst_Temperature_Sensor_Conv
        OperationInvokeEvent_23: start-on-event=MemAbstractMdl_Get_BsConst_Temperature_Sensor_Conv_SafeCopy1, operation=pp_CS_MemAbsGet.Get_BsConst_Temperature_Sensor_Conv_SafeCopy1
        OperationInvokeEvent_24: start-on-event=MemAbstractMdl_Get_BsConst_Temperature_Sensor_Conv_SafeCopy2, operation=pp_CS_MemAbsGet.Get_BsConst_Temperature_Sensor_Conv_SafeCopy2
        OIE_pp_CS_MemAbsGet_MemAbstractMdl_Get_BsConst_TripComputer_ElementTrigByGet_BsConst_TripComputer_Element: start-on-event=MemAbstractMdl_Get_BsConst_TripComputer_Element, operation=pp_CS_MemAbsGet.Get_BsConst_TripComputer_Element
        OIE_pp_CS_MemAbsGet_MemAbstractMdl_Get_BsConst_Warning_ElementTrigByGet_BsConst_Warning_Element: start-on-event=MemAbstractMdl_Get_BsConst_Warning_Element, operation=pp_CS_MemAbsGet.Get_BsConst_Warning_Element
        OIE_pp_CS_MemAbsGet_MemAbstractMdl_Get_BsCys_Certicificate_ElementTrigByGet_BsCys_Certicificate_Element: start-on-event=MemAbstractMdl_Get_BsCys_Certicificate_Element, operation=pp_CS_MemAbsGet.Get_BsCys_Certicificate_Element
        OIE_pp_CS_MemAbsGet_MemAbstractMdl_Get_BsDiag_Dtc_ElementTrigByGet_BsDiag_Dtc_Element: start-on-event=MemAbstractMdl_Get_BsDiag_Dtc_Element, operation=pp_CS_MemAbsGet.Get_BsDiag_Dtc_Element
        OIE_pp_CS_MemAbsGet_MemAbstractMdl_Get_BsDiag_ErrorRecord_ElementTrigByGet_BsDiag_ErrorRecord_Element: start-on-event=MemAbstractMdl_Get_BsDiag_ErrorRecord_Element, operation=pp_CS_MemAbsGet.Get_BsDiag_ErrorRecord_Element
        OIE_pp_CS_MemAbsGet_MemAbstractMdl_Get_BsReten_Audio_ElementTrigByGet_BsReten_Audio_Element: start-on-event=MemAbstractMdl_Get_BsReten_Audio_Element, operation=pp_CS_MemAbsGet.Get_BsReten_Audio_Element
        OIE_pp_CS_MemAbsGet_MemAbstractMdl_Get_BsReten_Communication_ElementTrigByGet_BsReten_Communication_Element: start-on-event=MemAbstractMdl_Get_BsReten_Communication_Element, operation=pp_CS_MemAbsGet.Get_BsReten_Communication_Element
        OIE_pp_CS_MemAbsGet_MemAbstractMdl_Get_BsReten_Display_ElementTrigByGet_BsReten_Display_Element: start-on-event=MemAbstractMdl_Get_BsReten_Display_Element, operation=pp_CS_MemAbsGet.Get_BsReten_Display_Element
        OIE_pp_CS_MemAbsGet_MemAbstractMdl_Get_BsReten_Gauges_ElementTrigByGet_BsReten_Gauges_Element: start-on-event=MemAbstractMdl_Get_BsReten_Gauges_Element, operation=pp_CS_MemAbsGet.Get_BsReten_Gauges_Element
        OIE_pp_CS_MemAbsGet_MemAbstractMdl_Get_BsReten_Illumination_ElementTrigByGet_BsReten_Illumination_Element: start-on-event=MemAbstractMdl_Get_BsReten_Illumination_Element, operation=pp_CS_MemAbsGet.Get_BsReten_Illumination_Element
        OIE_pp_CS_MemAbsGet_MemAbstractMdl_Get_BsReten_Odometer_ElementTrigByGet_BsReten_Odometer_Element: start-on-event=MemAbstractMdl_Get_BsReten_Odometer_Element, operation=pp_CS_MemAbsGet.Get_BsReten_Odometer_Element
        OIE_pp_CS_MemAbsGet_MemAbstractMdl_Get_BsReten_Personalization_ElementTrigByGet_BsReten_Personalization_Element: start-on-event=MemAbstractMdl_Get_BsReten_Personalization_Element, operation=pp_CS_MemAbsGet.Get_BsReten_Personalization_Element
        OIE_pp_CS_MemAbsGet_MemAbstractMdl_Get_BsReten_Power_ElementTrigByGet_BsReten_Power_Element: start-on-event=MemAbstractMdl_Get_BsReten_Power_Element, operation=pp_CS_MemAbsGet.Get_BsReten_Power_Element
        OIE_pp_CS_MemAbsGet_MemAbstractMdl_Get_BsReten_RealTimeClock_ElementTrigByGet_BsReten_RealTimeClock_Element: start-on-event=MemAbstractMdl_Get_BsReten_RealTimeClock_Element, operation=pp_CS_MemAbsGet.Get_BsReten_RealTimeClock_Element
        OIE_pp_CS_MemAbsGet_MemAbstractMdl_Get_BsReten_Tripcomputer_ElementTrigByGet_BsReten_Tripcomputer_Element: start-on-event=MemAbstractMdl_Get_BsReten_Tripcomputer_Element, operation=pp_CS_MemAbsGet.Get_BsReten_Tripcomputer_Element
        OIE_pp_CS_MemAbsGet_MemAbstractMdl_Get_BsReten_Warning_ElementTrigByGet_BsReten_Warning_Element: start-on-event=MemAbstractMdl_Get_BsReten_Warning_Element, operation=pp_CS_MemAbsGet.Get_BsReten_Warning_Element
        OIE_pp_CS_MemAbsGet_MemAbstractMdl_Get_BsRt_CusDlt_ElementTrigByGet_BsRt_CusDlt_Element: start-on-event=MemAbstractMdl_Get_BsRt_CusDlt_Element, operation=pp_CS_MemAbsGet.Get_BsRt_CusDlt_Element
        OIE_pp_CS_MemAbsGet_MemAbstractMdl_Get_BsRt_FuelGauge_ElementTrigByGet_BsRt_FuelGauge_Element: start-on-event=MemAbstractMdl_Get_BsRt_FuelGauge_Element, operation=pp_CS_MemAbsGet.Get_BsRt_FuelGauge_Element
        OIE_pp_CS_MemAbsGet_MemAbstractMdl_Get_BsRt_Illumination_ElementTrigByGet_BsRt_Illumination_Element: start-on-event=MemAbstractMdl_Get_BsRt_Illumination_Element, operation=pp_CS_MemAbsGet.Get_BsRt_Illumination_Element
        OIE_pp_CS_MemAbsGet_MemAbstractMdl_Get_BsRt_Odometer_ElementTrigByGet_BsRt_Odometer_Element: start-on-event=MemAbstractMdl_Get_BsRt_Odometer_Element, operation=pp_CS_MemAbsGet.Get_BsRt_Odometer_Element
        OIE_pp_CS_MemAbsGet_MemAbstractMdl_Get_BsRt_OilGauge_ElementTrigByGet_BsRt_OilGauge_Element: start-on-event=MemAbstractMdl_Get_BsRt_OilGauge_Element, operation=pp_CS_MemAbsGet.Get_BsRt_OilGauge_Element
        OIE_pp_CS_MemAbsGet_MemAbstractMdl_Get_BsRt_Personalization_ElementTrigByGet_BsRt_Personalization_Element: start-on-event=MemAbstractMdl_Get_BsRt_Personalization_Element, operation=pp_CS_MemAbsGet.Get_BsRt_Personalization_Element
        OIE_pp_CS_MemAbsGet_MemAbstractMdl_Get_BsRt_PowerGauge_ElementTrigByGet_BsRt_PowerGauge_Element: start-on-event=MemAbstractMdl_Get_BsRt_PowerGauge_Element, operation=pp_CS_MemAbsGet.Get_BsRt_PowerGauge_Element
        OIE_pp_CS_MemAbsGet_MemAbstractMdl_Get_BsRt_RealTimeClock_ElementTrigByGet_BsRt_RealTimeClock_Element: start-on-event=MemAbstractMdl_Get_BsRt_RealTimeClock_Element, operation=pp_CS_MemAbsGet.Get_BsRt_RealTimeClock_Element
        OIE_pp_CS_MemAbsGet_MemAbstractMdl_Get_BsRt_SpeedoGauge_ElementTrigByGet_BsRt_SpeedoGauge_Element: start-on-event=MemAbstractMdl_Get_BsRt_SpeedoGauge_Element, operation=pp_CS_MemAbsGet.Get_BsRt_SpeedoGauge_Element
        OIE_pp_CS_MemAbsGet_MemAbstractMdl_Get_BsRt_TachoGauge_ElementTrigByGet_BsRt_TachoGauge_Element: start-on-event=MemAbstractMdl_Get_BsRt_TachoGauge_Element, operation=pp_CS_MemAbsGet.Get_BsRt_TachoGauge_Element
        OIE_pp_CS_MemAbsGet_MemAbstractMdl_Get_BsRt_TempGauge_ElementTrigByGet_BsRt_TempGauge_Element: start-on-event=MemAbstractMdl_Get_BsRt_TempGauge_Element, operation=pp_CS_MemAbsGet.Get_BsRt_TempGauge_Element
        OIE_pp_CS_MemAbsGet_MemAbstractMdl_Get_BsRt_TripComputer_ElementTrigByGet_BsRt_TripComputer_Element: start-on-event=MemAbstractMdl_Get_BsRt_TripComputer_Element, operation=pp_CS_MemAbsGet.Get_BsRt_TripComputer_Element
        OIE_pp_CS_MemAbsGet_MemAbstractMdl_Get_BsRt_Warning_ElementTrigByGet_BsRt_Warning_Element: start-on-event=MemAbstractMdl_Get_BsRt_Warning_Element, operation=pp_CS_MemAbsGet.Get_BsRt_Warning_Element
        OIE_pp_CS_MemAbsGet_MemAbstractMdl_Get_BsShare_AssemblyManufacturingDateTrigByGet_BsShare_AssemblyManufacturingDate: start-on-event=MemAbstractMdl_Get_BsShare_AssemblyManufacturingDate, operation=pp_CS_MemAbsGet.Get_BsShare_AssemblyManufacturingDate
        OIE_pp_CS_MemAbsGet_MemAbstractMdl_Get_BsShare_AssemblyPlantNumberTrigByGet_BsShare_AssemblyPlantNumber: start-on-event=MemAbstractMdl_Get_BsShare_AssemblyPlantNumber, operation=pp_CS_MemAbsGet.Get_BsShare_AssemblyPlantNumber
        OIE_pp_CS_MemAbsGet_MemAbstractMdl_Get_BsShare_EcuPartNumber_ElementTrigByGet_BsShare_EcuPartNumber_Element: start-on-event=MemAbstractMdl_Get_BsShare_EcuPartNumber_Element, operation=pp_CS_MemAbsGet.Get_BsShare_EcuPartNumber_Element
        OIE_pp_CS_MemAbsGet_MemAbstractMdl_Get_BsShare_HWModificationTrigByGet_BsShare_HWModification: start-on-event=MemAbstractMdl_Get_BsShare_HWModification, operation=pp_CS_MemAbsGet.Get_BsShare_HWModification
        OIE_pp_CS_MemAbsGet_MemAbstractMdl_Get_BsShare_PCBSerialNumberTrigByGet_BsShare_PCBSerialNumber: start-on-event=MemAbstractMdl_Get_BsShare_PCBSerialNumber, operation=pp_CS_MemAbsGet.Get_BsShare_PCBSerialNumber
        OIE_pp_CS_MemAbsGet_MemAbstractMdl_Get_BsShare_ProductSerialNumberTrigByGet_BsShare_ProductSerialNumber: start-on-event=MemAbstractMdl_Get_BsShare_ProductSerialNumber, operation=pp_CS_MemAbsGet.Get_BsShare_ProductSerialNumber
        OIE_pp_CS_MemAbsGet_MemAbstractMdl_Get_BsShare_SMTManufacturingDateTrigByGet_BsShare_SMTManufacturingDate: start-on-event=MemAbstractMdl_Get_BsShare_SMTManufacturingDate, operation=pp_CS_MemAbsGet.Get_BsShare_SMTManufacturingDate
        OIE_pp_CS_MemAbsGet_MemAbstractMdl_Get_BsShare_SMTPlantNumberTrigByGet_BsShare_SMTPlantNumber: start-on-event=MemAbstractMdl_Get_BsShare_SMTPlantNumber, operation=pp_CS_MemAbsGet.Get_BsShare_SMTPlantNumber
        OIE_pp_CS_MemAbsGet_MemAbstractMdl_Get_BsShare_SwUpdFotaFinPrint_ElementTrigByGet_BsShare_SwUpdFotaFinPrint_Element: start-on-event=MemAbstractMdl_Get_BsShare_SwUpdFotaFinPrint_Element, operation=pp_CS_MemAbsGet.Get_BsShare_SwUpdFotaFinPrint_Element
        OIE_pp_CS_MemAbsGet_MemAbstractMdl_Get_BsShare_SwUpdFotaMode_ElementTrigByGet_BsShare_SwUpdFotaMode_Element: start-on-event=MemAbstractMdl_Get_BsShare_SwUpdFotaMode_Element, operation=pp_CS_MemAbsGet.Get_BsShare_SwUpdFotaMode_Element
        OIE_pp_CS_MemAbsGet_MemAbstractMdl_Get_BsShare_SwUpdFotaStatus_ElementTrigByGet_BsShare_SwUpdFotaStatus_Element: start-on-event=MemAbstractMdl_Get_BsShare_SwUpdFotaStatus_Element, operation=pp_CS_MemAbsGet.Get_BsShare_SwUpdFotaStatus_Element
        OIE_pp_CS_MemAbsGet_MemAbstractMdl_Get_BsShare_SwUpdFotadecrypt_ElementTrigByGet_BsShare_SwUpdFotadecrypt_Element: start-on-event=MemAbstractMdl_Get_BsShare_SwUpdFotadecrypt_Element, operation=pp_CS_MemAbsGet.Get_BsShare_SwUpdFotadecrypt_Element
        OIE_pp_CS_MemAbsGet_MemAbstractMdl_Get_BsShare_SwUpdReflash_ElementTrigByGet_BsShare_SwUpdReflash_Element: start-on-event=MemAbstractMdl_Get_BsShare_SwUpdReflash_Element, operation=pp_CS_MemAbsGet.Get_BsShare_SwUpdReflash_Element
        OIE_pp_CS_MemAbsGet_MemAbstractMdl_Get_BsShare_VehicleConfig_ElementTrigByGet_BsShare_VehicleConfig_Element: start-on-event=MemAbstractMdl_Get_BsShare_VehicleConfig_Element, operation=pp_CS_MemAbsGet.Get_BsShare_VehicleConfig_Element
        OIE_pp_CS_MemAbsGet_MemAbstractMdl_Get_BsShare_VisMeet_EOLEntry_ElementTrigByGet_BsShare_VisMeet_EOLEntry_Element: start-on-event=MemAbstractMdl_Get_BsShare_VisMeet_EOLEntry_Element, operation=pp_CS_MemAbsGet.Get_BsShare_VisMeet_EOLEntry_Element
        OIE_pp_CS_MemAbsGet_MemAbstractMdl_Get_BsShare_VisMeet_ElementTrigByGet_BsShare_VisMeet_Element: start-on-event=MemAbstractMdl_Get_BsShare_VisMeet_Element, operation=pp_CS_MemAbsGet.Get_BsShare_VisMeet_Element
        OIE_pp_CS_MemAbsGet_MemAbstractMdl_Get_BsShare_VisteonPCBPartNumberTrigByGet_BsShare_VisteonPCBPartNumber: start-on-event=MemAbstractMdl_Get_BsShare_VisteonPCBPartNumber, operation=pp_CS_MemAbsGet.Get_BsShare_VisteonPCBPartNumber
        OIE_pp_CS_MemAbsGet_MemAbstractMdl_Get_BsShare_VisteonPartNumberTrigByGet_BsShare_VisteonPartNumber: start-on-event=MemAbstractMdl_Get_BsShare_VisteonPartNumber, operation=pp_CS_MemAbsGet.Get_BsShare_VisteonPartNumber
        OIE_pp_CS_MemAbsGetDefault_MemAbstractMdl_Get_Default_BsConst_Audio_ElementTrigByGet_Default_BsConst_Audio_Element: start-on-event=MemAbstractMdl_Get_Default_BsConst_Audio_Element, operation=pp_CS_MemAbsGetDefault.Get_Default_BsConst_Audio_Element
        OperationInvokeEvent_25: start-on-event=MemAbstractMdl_Get_Default_BsConst_BsConst_Illumination_ReservedByte, operation=pp_CS_MemAbsGetDefault.Get_Default_BsConst_BsConst_Illumination_ReservedByte
        OperationInvokeEvent_26: start-on-event=MemAbstractMdl_Get_Default_BsConst_BsConst_Illumination_ReservedByte_SafeCopy1, operation=pp_CS_MemAbsGetDefault.Get_Default_BsConst_BsConst_Illumination_ReservedByte_SafeCopy1
        OperationInvokeEvent_27: start-on-event=MemAbstractMdl_Get_Default_BsConst_BsConst_Illumination_ReservedByte_SafeCopy2, operation=pp_CS_MemAbsGetDefault.Get_Default_BsConst_BsConst_Illumination_ReservedByte_SafeCopy2
        OperationInvokeEvent_28: start-on-event=MemAbstractMdl_Get_Default_BsConst_Communication_Element, operation=pp_CS_MemAbsGetDefault.Get_Default_BsConst_Communication_Element
        OperationInvokeEvent_29: start-on-event=MemAbstractMdl_Get_Default_BsConst_Compensation_Line_Shift_b, operation=pp_CS_MemAbsGetDefault.Get_Default_BsConst_Compensation_Line_Shift_b
        OperationInvokeEvent_30: start-on-event=MemAbstractMdl_Get_Default_BsConst_Compensation_Line_Shift_b_SafeCopy1, operation=pp_CS_MemAbsGetDefault.Get_Default_BsConst_Compensation_Line_Shift_b_SafeCopy1
        OperationInvokeEvent_31: start-on-event=MemAbstractMdl_Get_Default_BsConst_Compensation_Line_Shift_b_SafeCopy2, operation=pp_CS_MemAbsGetDefault.Get_Default_BsConst_Compensation_Line_Shift_b_SafeCopy2
        OperationInvokeEvent_32: start-on-event=MemAbstractMdl_Get_Default_BsConst_Compensation_Line_Slope_m, operation=pp_CS_MemAbsGetDefault.Get_Default_BsConst_Compensation_Line_Slope_m
        OperationInvokeEvent_33: start-on-event=MemAbstractMdl_Get_Default_BsConst_Compensation_Line_Slope_m_SafeCopy1, operation=pp_CS_MemAbsGetDefault.Get_Default_BsConst_Compensation_Line_Slope_m_SafeCopy1
        OperationInvokeEvent_34: start-on-event=MemAbstractMdl_Get_Default_BsConst_Compensation_Line_Slope_m_SafeCopy2, operation=pp_CS_MemAbsGetDefault.Get_Default_BsConst_Compensation_Line_Slope_m_SafeCopy2
        OperationInvokeEvent_35: start-on-event=MemAbstractMdl_Get_Default_BsConst_Derating_Backlight_Disable, operation=pp_CS_MemAbsGetDefault.Get_Default_BsConst_Derating_Backlight_Disable
        OperationInvokeEvent_36: start-on-event=MemAbstractMdl_Get_Default_BsConst_Derating_Backlight_Disable_SafeCopy1, operation=pp_CS_MemAbsGetDefault.Get_Default_BsConst_Derating_Backlight_Disable_SafeCopy1
        OperationInvokeEvent_37: start-on-event=MemAbstractMdl_Get_Default_BsConst_Derating_Backlight_Disable_SafeCopy2, operation=pp_CS_MemAbsGetDefault.Get_Default_BsConst_Derating_Backlight_Disable_SafeCopy2
        OperationInvokeEvent_38: start-on-event=MemAbstractMdl_Get_Default_BsConst_Display_Illum_Max_Level, operation=pp_CS_MemAbsGetDefault.Get_Default_BsConst_Display_Illum_Max_Level
        OperationInvokeEvent_39: start-on-event=MemAbstractMdl_Get_Default_BsConst_Display_Illum_Max_Level_SafeCopy1, operation=pp_CS_MemAbsGetDefault.Get_Default_BsConst_Display_Illum_Max_Level_SafeCopy1
        OperationInvokeEvent_40: start-on-event=MemAbstractMdl_Get_Default_BsConst_Display_Illum_Max_Level_SafeCopy2, operation=pp_CS_MemAbsGetDefault.Get_Default_BsConst_Display_Illum_Max_Level_SafeCopy2
        OIE_pp_CS_MemAbsGetDefault_MemAbstractMdl_Get_Default_BsConst_EngOffTimer_ElementTrigByGet_Default_BsConst_EngOffTimer_Element: start-on-event=MemAbstractMdl_Get_Default_BsConst_EngOffTimer_Element, operation=pp_CS_MemAbsGetDefault.Get_Default_BsConst_EngOffTimer_Element
        OIE_pp_CS_MemAbsGetDefault_MemAbstractMdl_Get_Default_BsConst_FuelGauge_ElementTrigByGet_Default_BsConst_FuelGauge_Element: start-on-event=MemAbstractMdl_Get_Default_BsConst_FuelGauge_Element, operation=pp_CS_MemAbsGetDefault.Get_Default_BsConst_FuelGauge_Element
        OperationInvokeEvent_41: start-on-event=MemAbstractMdl_Get_Default_BsConst_Lookup_Curve_HotSpot_Coef_X, operation=pp_CS_MemAbsGetDefault.Get_Default_BsConst_Lookup_Curve_HotSpot_Coef_X
        OperationInvokeEvent_42: start-on-event=MemAbstractMdl_Get_Default_BsConst_Lookup_Curve_HotSpot_Coef_X_SafeCopy1, operation=pp_CS_MemAbsGetDefault.Get_Default_BsConst_Lookup_Curve_HotSpot_Coef_X_SafeCopy1
        OperationInvokeEvent_43: start-on-event=MemAbstractMdl_Get_Default_BsConst_Lookup_Curve_HotSpot_Coef_X_SafeCopy2, operation=pp_CS_MemAbsGetDefault.Get_Default_BsConst_Lookup_Curve_HotSpot_Coef_X_SafeCopy2
        OperationInvokeEvent_44: start-on-event=MemAbstractMdl_Get_Default_BsConst_Lookup_Curve_HotSpot_Coef_Y, operation=pp_CS_MemAbsGetDefault.Get_Default_BsConst_Lookup_Curve_HotSpot_Coef_Y
        OperationInvokeEvent_45: start-on-event=MemAbstractMdl_Get_Default_BsConst_Lookup_Curve_HotSpot_Coef_Y_SafeCopy1, operation=pp_CS_MemAbsGetDefault.Get_Default_BsConst_Lookup_Curve_HotSpot_Coef_Y_SafeCopy1
        OperationInvokeEvent_46: start-on-event=MemAbstractMdl_Get_Default_BsConst_Lookup_Curve_HotSpot_Coef_Y_SafeCopy2, operation=pp_CS_MemAbsGetDefault.Get_Default_BsConst_Lookup_Curve_HotSpot_Coef_Y_SafeCopy2
        OIE_pp_CS_MemAbsGetDefault_MemAbstractMdl_Get_Default_BsConst_OilGauge_ElementTrigByGet_Default_BsConst_OilGauge_Element: start-on-event=MemAbstractMdl_Get_Default_BsConst_OilGauge_Element, operation=pp_CS_MemAbsGetDefault.Get_Default_BsConst_OilGauge_Element
        OperationInvokeEvent_47: start-on-event=MemAbstractMdl_Get_Default_BsConst_PCB_Temperature_Sensor_Conv, operation=pp_CS_MemAbsGetDefault.Get_Default_BsConst_PCB_Temperature_Sensor_Conv
        OperationInvokeEvent_48: start-on-event=MemAbstractMdl_Get_Default_BsConst_PCB_Temperature_Sensor_Conv_SafeCopy1, operation=pp_CS_MemAbsGetDefault.Get_Default_BsConst_PCB_Temperature_Sensor_Conv_SafeCopy1
        OperationInvokeEvent_49: start-on-event=MemAbstractMdl_Get_Default_BsConst_PCB_Temperature_Sensor_Conv_SafeCopy2, operation=pp_CS_MemAbsGetDefault.Get_Default_BsConst_PCB_Temperature_Sensor_Conv_SafeCopy2
        OperationInvokeEvent_50: start-on-event=MemAbstractMdl_Get_Default_BsConst_PWM_boost_bypass_duty, operation=pp_CS_MemAbsGetDefault.Get_Default_BsConst_PWM_boost_bypass_duty
        OperationInvokeEvent_51: start-on-event=MemAbstractMdl_Get_Default_BsConst_PWM_boost_bypass_duty_SafeCopy1, operation=pp_CS_MemAbsGetDefault.Get_Default_BsConst_PWM_boost_bypass_duty_SafeCopy1
        OperationInvokeEvent_52: start-on-event=MemAbstractMdl_Get_Default_BsConst_PWM_boost_bypass_duty_SafeCopy2, operation=pp_CS_MemAbsGetDefault.Get_Default_BsConst_PWM_boost_bypass_duty_SafeCopy2
        OIE_pp_CS_MemAbsGetDefault_MemAbstractMdl_Get_Default_BsConst_PowerGauge_ElementTrigByGet_Default_BsConst_PowerGauge_Element: start-on-event=MemAbstractMdl_Get_Default_BsConst_PowerGauge_Element, operation=pp_CS_MemAbsGetDefault.Get_Default_BsConst_PowerGauge_Element
        OIE_pp_CS_MemAbsGetDefault_MemAbstractMdl_Get_Default_BsConst_Power_ElementTrigByGet_Default_BsConst_Power_Element: start-on-event=MemAbstractMdl_Get_Default_BsConst_Power_Element, operation=pp_CS_MemAbsGetDefault.Get_Default_BsConst_Power_Element
        OperationInvokeEvent_53: start-on-event=MemAbstractMdl_Get_Default_BsConst_RealTimeClock_Element, operation=pp_CS_MemAbsGetDefault.Get_Default_BsConst_RealTimeClock_Element
        OperationInvokeEvent_54: start-on-event=MemAbstractMdl_Get_Default_BsConst_ServiceReminder_Element, operation=pp_CS_MemAbsGetDefault.Get_Default_BsConst_ServiceReminder_Element
        OIE_pp_CS_MemAbsGetDefault_MemAbstractMdl_Get_Default_BsConst_SpeedoGauge_ElementTrigByGet_Default_BsConst_SpeedoGauge_Element: start-on-event=MemAbstractMdl_Get_Default_BsConst_SpeedoGauge_Element, operation=pp_CS_MemAbsGetDefault.Get_Default_BsConst_SpeedoGauge_Element
        OIE_pp_CS_MemAbsGetDefault_MemAbstractMdl_Get_Default_BsConst_TachoGauge_ElementTrigByGet_Default_BsConst_TachoGauge_Element: start-on-event=MemAbstractMdl_Get_Default_BsConst_TachoGauge_Element, operation=pp_CS_MemAbsGetDefault.Get_Default_BsConst_TachoGauge_Element
        OIE_pp_CS_MemAbsGetDefault_MemAbstractMdl_Get_Default_BsConst_TempGauge_ElementTrigByGet_Default_BsConst_TempGauge_Element: start-on-event=MemAbstractMdl_Get_Default_BsConst_TempGauge_Element, operation=pp_CS_MemAbsGetDefault.Get_Default_BsConst_TempGauge_Element
        OperationInvokeEvent_55: start-on-event=MemAbstractMdl_Get_Default_BsConst_Temp_Threshold_Hysteresis_Derating, operation=pp_CS_MemAbsGetDefault.Get_Default_BsConst_Temp_Threshold_Hysteresis_Derating
        OperationInvokeEvent_56: start-on-event=MemAbstractMdl_Get_Default_BsConst_Temp_Threshold_Hysteresis_Derating_SafeCopy1, operation=pp_CS_MemAbsGetDefault.Get_Default_BsConst_Temp_Threshold_Hysteresis_Derating_SafeCopy1
        OperationInvokeEvent_57: start-on-event=MemAbstractMdl_Get_Default_BsConst_Temp_Threshold_Hysteresis_Derating_SafeCopy2, operation=pp_CS_MemAbsGetDefault.Get_Default_BsConst_Temp_Threshold_Hysteresis_Derating_SafeCopy2
        OperationInvokeEvent_58: start-on-event=MemAbstractMdl_Get_Default_BsConst_Temperature_Sensor_Conv, operation=pp_CS_MemAbsGetDefault.Get_Default_BsConst_Temperature_Sensor_Conv
        OperationInvokeEvent_59: start-on-event=MemAbstractMdl_Get_Default_BsConst_Temperature_Sensor_Conv_SafeCopy1, operation=pp_CS_MemAbsGetDefault.Get_Default_BsConst_Temperature_Sensor_Conv_SafeCopy1
        OperationInvokeEvent_60: start-on-event=MemAbstractMdl_Get_Default_BsConst_Temperature_Sensor_Conv_SafeCopy2, operation=pp_CS_MemAbsGetDefault.Get_Default_BsConst_Temperature_Sensor_Conv_SafeCopy2
        OperationInvokeEvent_61: start-on-event=MemAbstractMdl_Get_Default_BsConst_TripComputer_Element, operation=pp_CS_MemAbsGetDefault.Get_Default_BsConst_TripComputer_Element
        OIE_pp_CS_MemAbsGetDefault_MemAbstractMdl_Get_Default_BsConst_Warning_ElementTrigByGet_Default_BsConst_Warning_Element: start-on-event=MemAbstractMdl_Get_Default_BsConst_Warning_Element, operation=pp_CS_MemAbsGetDefault.Get_Default_BsConst_Warning_Element
        OIE_pp_CS_MemAbsGetDefault_MemAbstractMdl_Get_Default_BsCys_Certicificate_ElementTrigByGet_Default_BsCys_Certicificate_Element: start-on-event=MemAbstractMdl_Get_Default_BsCys_Certicificate_Element, operation=pp_CS_MemAbsGetDefault.Get_Default_BsCys_Certicificate_Element
        OIE_pp_CS_MemAbsGetDefault_MemAbstractMdl_Get_Default_BsDiag_Dtc_ElementTrigByGet_Default_BsDiag_Dtc_Element: start-on-event=MemAbstractMdl_Get_Default_BsDiag_Dtc_Element, operation=pp_CS_MemAbsGetDefault.Get_Default_BsDiag_Dtc_Element
        OIE_pp_CS_MemAbsGetDefault_MemAbstractMdl_Get_Default_BsDiag_ErrorRecord_ElementTrigByGet_Default_BsDiag_ErrorRecord_Element: start-on-event=MemAbstractMdl_Get_Default_BsDiag_ErrorRecord_Element, operation=pp_CS_MemAbsGetDefault.Get_Default_BsDiag_ErrorRecord_Element
        OIE_pp_CS_MemAbsGetDefault_MemAbstractMdl_Get_Default_BsReten_Audio_ElementTrigByGet_Default_BsReten_Audio_Element: start-on-event=MemAbstractMdl_Get_Default_BsReten_Audio_Element, operation=pp_CS_MemAbsGetDefault.Get_Default_BsReten_Audio_Element
        OperationInvokeEvent_62: start-on-event=MemAbstractMdl_Get_Default_BsReten_Communication_Element, operation=pp_CS_MemAbsGetDefault.Get_Default_BsReten_Communication_Element
        OIE_pp_CS_MemAbsGetDefault_MemAbstractMdl_Get_Default_BsReten_Display_ElementTrigByGet_Default_BsReten_Display_Element: start-on-event=MemAbstractMdl_Get_Default_BsReten_Display_Element, operation=pp_CS_MemAbsGetDefault.Get_Default_BsReten_Display_Element
        OIE_pp_CS_MemAbsGetDefault_MemAbstractMdl_Get_Default_BsReten_Gauges_ElementTrigByGet_Default_BsReten_Gauges_Element: start-on-event=MemAbstractMdl_Get_Default_BsReten_Gauges_Element, operation=pp_CS_MemAbsGetDefault.Get_Default_BsReten_Gauges_Element
        OperationInvokeEvent_63: start-on-event=MemAbstractMdl_Get_Default_BsReten_Illumination_Element, operation=pp_CS_MemAbsGetDefault.Get_Default_BsReten_Illumination_Element
        OIE_pp_CS_MemAbsGetDefault_MemAbstractMdl_Get_Default_BsReten_Odometer_ElementTrigByGet_Default_BsReten_Odometer_Element: start-on-event=MemAbstractMdl_Get_Default_BsReten_Odometer_Element, operation=pp_CS_MemAbsGetDefault.Get_Default_BsReten_Odometer_Element
        OperationInvokeEvent_64: start-on-event=MemAbstractMdl_Get_Default_BsReten_Personalization_Element, operation=pp_CS_MemAbsGetDefault.Get_Default_BsReten_Personalization_Element
        OIE_pp_CS_MemAbsGetDefault_MemAbstractMdl_Get_Default_BsReten_Power_ElementTrigByGet_Default_BsReten_Power_Element: start-on-event=MemAbstractMdl_Get_Default_BsReten_Power_Element, operation=pp_CS_MemAbsGetDefault.Get_Default_BsReten_Power_Element
        OperationInvokeEvent_65: start-on-event=MemAbstractMdl_Get_Default_BsReten_RealTimeClock_Element, operation=pp_CS_MemAbsGetDefault.Get_Default_BsReten_RealTimeClock_Element
        OperationInvokeEvent_66: start-on-event=MemAbstractMdl_Get_Default_BsReten_Tripcomputer_Element, operation=pp_CS_MemAbsGetDefault.Get_Default_BsReten_Tripcomputer_Element
        OIE_pp_CS_MemAbsGetDefault_MemAbstractMdl_Get_Default_BsReten_Warning_ElementTrigByGet_Default_BsReten_Warning_Element: start-on-event=MemAbstractMdl_Get_Default_BsReten_Warning_Element, operation=pp_CS_MemAbsGetDefault.Get_Default_BsReten_Warning_Element
        OIE_pp_CS_MemAbsGetDefault_MemAbstractMdl_Get_Default_BsRt_CusDlt_ElementTrigByGet_Default_BsRt_CusDlt_Element: start-on-event=MemAbstractMdl_Get_Default_BsRt_CusDlt_Element, operation=pp_CS_MemAbsGetDefault.Get_Default_BsRt_CusDlt_Element
        OIE_pp_CS_MemAbsGetDefault_MemAbstractMdl_Get_Default_BsRt_FuelGauge_ElementTrigByGet_Default_BsRt_FuelGauge_Element: start-on-event=MemAbstractMdl_Get_Default_BsRt_FuelGauge_Element, operation=pp_CS_MemAbsGetDefault.Get_Default_BsRt_FuelGauge_Element
        OIE_pp_CS_MemAbsGetDefault_MemAbstractMdl_Get_Default_BsRt_Illumination_ElementTrigByGet_Default_BsRt_Illumination_Element: start-on-event=MemAbstractMdl_Get_Default_BsRt_Illumination_Element, operation=pp_CS_MemAbsGetDefault.Get_Default_BsRt_Illumination_Element
        OIE_pp_CS_MemAbsGetDefault_MemAbstractMdl_Get_Default_BsRt_Odometer_ElementTrigByGet_Default_BsRt_Odometer_Element: start-on-event=MemAbstractMdl_Get_Default_BsRt_Odometer_Element, operation=pp_CS_MemAbsGetDefault.Get_Default_BsRt_Odometer_Element
        OIE_pp_CS_MemAbsGetDefault_MemAbstractMdl_Get_Default_BsRt_OilGauge_ElementTrigByGet_Default_BsRt_OilGauge_Element: start-on-event=MemAbstractMdl_Get_Default_BsRt_OilGauge_Element, operation=pp_CS_MemAbsGetDefault.Get_Default_BsRt_OilGauge_Element
        OperationInvokeEvent_67: start-on-event=MemAbstractMdl_Get_Default_BsRt_Personalization_Element, operation=pp_CS_MemAbsGetDefault.Get_Default_BsRt_Personalization_Element
        OIE_pp_CS_MemAbsGetDefault_MemAbstractMdl_Get_Default_BsRt_PowerGauge_ElementTrigByGet_Default_BsRt_PowerGauge_Element: start-on-event=MemAbstractMdl_Get_Default_BsRt_PowerGauge_Element, operation=pp_CS_MemAbsGetDefault.Get_Default_BsRt_PowerGauge_Element
        OIE_pp_CS_MemAbsGetDefault_MemAbstractMdl_Get_Default_BsRt_RealTimeClock_ElementTrigByGet_Default_BsRt_RealTimeClock_Element: start-on-event=MemAbstractMdl_Get_Default_BsRt_RealTimeClock_Element, operation=pp_CS_MemAbsGetDefault.Get_Default_BsRt_RealTimeClock_Element
        OIE_pp_CS_MemAbsGetDefault_MemAbstractMdl_Get_Default_BsRt_SpeedoGauge_ElementTrigByGet_Default_BsRt_SpeedoGauge_Element: start-on-event=MemAbstractMdl_Get_Default_BsRt_SpeedoGauge_Element, operation=pp_CS_MemAbsGetDefault.Get_Default_BsRt_SpeedoGauge_Element
        OIE_pp_CS_MemAbsGetDefault_MemAbstractMdl_Get_Default_BsRt_TachoGauge_ElementTrigByGet_Default_BsRt_TachoGauge_Element: start-on-event=MemAbstractMdl_Get_Default_BsRt_TachoGauge_Element, operation=pp_CS_MemAbsGetDefault.Get_Default_BsRt_TachoGauge_Element
        OIE_pp_CS_MemAbsGetDefault_MemAbstractMdl_Get_Default_BsRt_TempGauge_ElementTrigByGet_Default_BsRt_TempGauge_Element: start-on-event=MemAbstractMdl_Get_Default_BsRt_TempGauge_Element, operation=pp_CS_MemAbsGetDefault.Get_Default_BsRt_TempGauge_Element
        OIE_pp_CS_MemAbsGetDefault_MemAbstractMdl_Get_Default_BsRt_TripComputer_ElementTrigByGet_Default_BsRt_TripComputer_Element: start-on-event=MemAbstractMdl_Get_Default_BsRt_TripComputer_Element, operation=pp_CS_MemAbsGetDefault.Get_Default_BsRt_TripComputer_Element
        OIE_pp_CS_MemAbsGetDefault_MemAbstractMdl_Get_Default_BsRt_Warning_ElementTrigByGet_Default_BsRt_Warning_Element: start-on-event=MemAbstractMdl_Get_Default_BsRt_Warning_Element, operation=pp_CS_MemAbsGetDefault.Get_Default_BsRt_Warning_Element
        OperationInvokeEvent_68: start-on-event=MemAbstractMdl_Get_Default_BsShare_AssemblyManufacturingDate, operation=pp_CS_MemAbsGetDefault.Get_Default_BsShare_AssemblyManufacturingDate
        OIE_pp_CS_MemAbsGetDefault_MemAbstractMdl_Get_Default_BsShare_AssemblyPlantNumberTrigByGet_Default_BsShare_AssemblyPlantNumber: start-on-event=MemAbstractMdl_Get_Default_BsShare_AssemblyPlantNumber, operation=pp_CS_MemAbsGetDefault.Get_Default_BsShare_AssemblyPlantNumber
        OperationInvokeEvent_69: start-on-event=MemAbstractMdl_Get_Default_BsShare_EcuPartNumber_Element, operation=pp_CS_MemAbsGetDefault.Get_Default_BsShare_EcuPartNumber_Element
        OIE_pp_CS_MemAbsGetDefault_MemAbstractMdl_Get_Default_BsShare_HWModificationTrigByGet_Default_BsShare_HWModification: start-on-event=MemAbstractMdl_Get_Default_BsShare_HWModification, operation=pp_CS_MemAbsGetDefault.Get_Default_BsShare_HWModification
        OIE_pp_CS_MemAbsGetDefault_MemAbstractMdl_Get_Default_BsShare_PCBSerialNumberTrigByGet_Default_BsShare_PCBSerialNumber: start-on-event=MemAbstractMdl_Get_Default_BsShare_PCBSerialNumber, operation=pp_CS_MemAbsGetDefault.Get_Default_BsShare_PCBSerialNumber
        OIE_pp_CS_MemAbsGetDefault_MemAbstractMdl_Get_Default_BsShare_ProductSerialNumberTrigByGet_Default_BsShare_ProductSerialNumber: start-on-event=MemAbstractMdl_Get_Default_BsShare_ProductSerialNumber, operation=pp_CS_MemAbsGetDefault.Get_Default_BsShare_ProductSerialNumber
        OperationInvokeEvent_70: start-on-event=MemAbstractMdl_Get_Default_BsShare_SMTManufacturingDate, operation=pp_CS_MemAbsGetDefault.Get_Default_BsShare_SMTManufacturingDate
        OIE_pp_CS_MemAbsGetDefault_MemAbstractMdl_Get_Default_BsShare_SMTPlantNumberTrigByGet_Default_BsShare_SMTPlantNumber: start-on-event=MemAbstractMdl_Get_Default_BsShare_SMTPlantNumber, operation=pp_CS_MemAbsGetDefault.Get_Default_BsShare_SMTPlantNumber
        OperationInvokeEvent_71: start-on-event=MemAbstractMdl_Get_Default_BsShare_SwUpdFotaFinPrint_Element, operation=pp_CS_MemAbsGetDefault.Get_Default_BsShare_SwUpdFotaFinPrint_Element
        OperationInvokeEvent_72: start-on-event=MemAbstractMdl_Get_Default_BsShare_SwUpdFotaMode_Element, operation=pp_CS_MemAbsGetDefault.Get_Default_BsShare_SwUpdFotaMode_Element
        OperationInvokeEvent_73: start-on-event=MemAbstractMdl_Get_Default_BsShare_SwUpdFotaStatus_Element, operation=pp_CS_MemAbsGetDefault.Get_Default_BsShare_SwUpdFotaStatus_Element
        OperationInvokeEvent_74: start-on-event=MemAbstractMdl_Get_Default_BsShare_SwUpdFotadecrypt_Element, operation=pp_CS_MemAbsGetDefault.Get_Default_BsShare_SwUpdFotadecrypt_Element
        OperationInvokeEvent_75: start-on-event=MemAbstractMdl_Get_Default_BsShare_SwUpdReflash_Element, operation=pp_CS_MemAbsGetDefault.Get_Default_BsShare_SwUpdReflash_Element
        OperationInvokeEvent_76: start-on-event=MemAbstractMdl_Get_Default_BsShare_VehicleConfig_Element, operation=pp_CS_MemAbsGetDefault.Get_Default_BsShare_VehicleConfig_Element
        OperationInvokeEvent_77: start-on-event=MemAbstractMdl_Get_Default_BsShare_VisMeet_EOLEntry_Element, operation=pp_CS_MemAbsGetDefault.Get_Default_BsShare_VisMeet_EOLEntry_Element
        OIE_pp_CS_MemAbsGetDefault_MemAbstractMdl_Get_Default_BsShare_VisMeet_ElementTrigByGet_Default_BsShare_VisMeet_Element: start-on-event=MemAbstractMdl_Get_Default_BsShare_VisMeet_Element, operation=pp_CS_MemAbsGetDefault.Get_Default_BsShare_VisMeet_Element
        OperationInvokeEvent_78: start-on-event=MemAbstractMdl_Get_Default_BsShare_VisteonPCBPartNumber, operation=pp_CS_MemAbsGetDefault.Get_Default_BsShare_VisteonPCBPartNumber
        OIE_pp_CS_MemAbsGetDefault_MemAbstractMdl_Get_Default_BsShare_VisteonPartNumberTrigByGet_Default_BsShare_VisteonPartNumber: start-on-event=MemAbstractMdl_Get_Default_BsShare_VisteonPartNumber, operation=pp_CS_MemAbsGetDefault.Get_Default_BsShare_VisteonPartNumber
        OperationInvokeEvent_79: start-on-event=MemAbstractMdl_Get_Default_RefCys_Certicificate1_Element, operation=pp_CS_MemAbsGetDefault.Get_Default_RefCys_Certicificate1_Element
        OperationInvokeEvent_80: start-on-event=MemAbstractMdl_Get_Default_RefCys_Certicificate_Element, operation=pp_CS_MemAbsGetDefault.Get_Default_RefCys_Certicificate_Element
        OIE_pp_CS_MemAbsGet_MemAbstractMdl_Get_RefCys_Certicificate1_ElementTrigByGet_RefCys_Certicificate1_Element: start-on-event=MemAbstractMdl_Get_RefCys_Certicificate1_Element, operation=pp_CS_MemAbsGet.Get_RefCys_Certicificate1_Element
        OIE_pp_CS_MemAbsGet_MemAbstractMdl_Get_RefCys_Certicificate_ElementTrigByGet_RefCys_Certicificate_Element: start-on-event=MemAbstractMdl_Get_RefCys_Certicificate_Element, operation=pp_CS_MemAbsGet.Get_RefCys_Certicificate_Element
        OIE_pp_CS_MemAbs_NvMWriteStatus_MemAbstractMdl_NvmWriteStatusTrigByNvmWriteStatus: start-on-event=MemAbstractMdl_NvmWriteStatus, operation=pp_CS_MemAbs_NvMWriteStatus.NvmWriteStatus
        OIE_pp_CS_MemAbsSet_MemAbstractMdl_Set_BsConst_Audio_ElementTrigBySet_BsConst_Audio_Element: start-on-event=MemAbstractMdl_Set_BsConst_Audio_Element, operation=pp_CS_MemAbsSet.Set_BsConst_Audio_Element
        OperationInvokeEvent_81: start-on-event=MemAbstractMdl_Set_BsConst_BsConst_Illumination_ReservedByte, operation=pp_CS_MemAbsSet.Set_BsConst_BsConst_Illumination_ReservedByte
        OperationInvokeEvent_82: start-on-event=MemAbstractMdl_Set_BsConst_BsConst_Illumination_ReservedByte_SafeCopy1, operation=pp_CS_MemAbsSet.Set_BsConst_BsConst_Illumination_ReservedByte_SafeCopy1
        OperationInvokeEvent_83: start-on-event=MemAbstractMdl_Set_BsConst_BsConst_Illumination_ReservedByte_SafeCopy2, operation=pp_CS_MemAbsSet.Set_BsConst_BsConst_Illumination_ReservedByte_SafeCopy2
        OIE_pp_CS_MemAbsSet_MemAbstractMdl_Set_BsConst_Communication_ElementTrigBySet_BsConst_Communication_Element: start-on-event=MemAbstractMdl_Set_BsConst_Communication_Element, operation=pp_CS_MemAbsSet.Set_BsConst_Communication_Element
        OIE_pp_CS_MemAbsSet_MemAbstractMdl_Set_BsConst_Compensation_Line_Shift_bTrigBySet_BsConst_Compensation_Line_Shift_b: start-on-event=MemAbstractMdl_Set_BsConst_Compensation_Line_Shift_b, operation=pp_CS_MemAbsSet.Set_BsConst_Compensation_Line_Shift_b
        OperationInvokeEvent_84: start-on-event=MemAbstractMdl_Set_BsConst_Compensation_Line_Shift_b_SafeCopy1, operation=pp_CS_MemAbsSet.Set_BsConst_Compensation_Line_Shift_b_SafeCopy1
        OperationInvokeEvent_85: start-on-event=MemAbstractMdl_Set_BsConst_Compensation_Line_Shift_b_SafeCopy2, operation=pp_CS_MemAbsSet.Set_BsConst_Compensation_Line_Shift_b_SafeCopy2
        OIE_pp_CS_MemAbsSet_MemAbstractMdl_Set_BsConst_Compensation_Line_Slope_mTrigBySet_BsConst_Compensation_Line_Slope_m: start-on-event=MemAbstractMdl_Set_BsConst_Compensation_Line_Slope_m, operation=pp_CS_MemAbsSet.Set_BsConst_Compensation_Line_Slope_m
        OperationInvokeEvent_86: start-on-event=MemAbstractMdl_Set_BsConst_Compensation_Line_Slope_m_SafeCopy1, operation=pp_CS_MemAbsSet.Set_BsConst_Compensation_Line_Slope_m_SafeCopy1
        OperationInvokeEvent_87: start-on-event=MemAbstractMdl_Set_BsConst_Compensation_Line_Slope_m_SafeCopy2, operation=pp_CS_MemAbsSet.Set_BsConst_Compensation_Line_Slope_m_SafeCopy2
        OIE_pp_CS_MemAbsSet_MemAbstractMdl_Set_BsConst_Derating_Backlight_DisableTrigBySet_BsConst_Derating_Backlight_Disable: start-on-event=MemAbstractMdl_Set_BsConst_Derating_Backlight_Disable, operation=pp_CS_MemAbsSet.Set_BsConst_Derating_Backlight_Disable
        OperationInvokeEvent_88: start-on-event=MemAbstractMdl_Set_BsConst_Derating_Backlight_Disable_SafeCopy1, operation=pp_CS_MemAbsSet.Set_BsConst_Derating_Backlight_Disable_SafeCopy1
        OperationInvokeEvent_89: start-on-event=MemAbstractMdl_Set_BsConst_Derating_Backlight_Disable_SafeCopy2, operation=pp_CS_MemAbsSet.Set_BsConst_Derating_Backlight_Disable_SafeCopy2
        OIE_pp_CS_MemAbsSet_MemAbstractMdl_Set_BsConst_Display_Illum_Max_LevelTrigBySet_BsConst_Display_Illum_Max_Level: start-on-event=MemAbstractMdl_Set_BsConst_Display_Illum_Max_Level, operation=pp_CS_MemAbsSet.Set_BsConst_Display_Illum_Max_Level
        OperationInvokeEvent_90: start-on-event=MemAbstractMdl_Set_BsConst_Display_Illum_Max_Level_SafeCopy1, operation=pp_CS_MemAbsSet.Set_BsConst_Display_Illum_Max_Level_SafeCopy1
        OperationInvokeEvent_91: start-on-event=MemAbstractMdl_Set_BsConst_Display_Illum_Max_Level_SafeCopy2, operation=pp_CS_MemAbsSet.Set_BsConst_Display_Illum_Max_Level_SafeCopy2
        OIE_pp_CS_MemAbsSet_MemAbstractMdl_Set_BsConst_EngOffTimer_ElementTrigBySet_BsConst_EngOffTimer_Element: start-on-event=MemAbstractMdl_Set_BsConst_EngOffTimer_Element, operation=pp_CS_MemAbsSet.Set_BsConst_EngOffTimer_Element
        OIE_pp_CS_MemAbsSet_MemAbstractMdl_Set_BsConst_FuelGauge_ElementTrigBySet_BsConst_FuelGauge_Element: start-on-event=MemAbstractMdl_Set_BsConst_FuelGauge_Element, operation=pp_CS_MemAbsSet.Set_BsConst_FuelGauge_Element
        OIE_pp_CS_MemAbsSet_MemAbstractMdl_Set_BsConst_Lookup_Curve_HotSpot_Coef_XTrigBySet_BsConst_Lookup_Curve_HotSpot_Coef_X: start-on-event=MemAbstractMdl_Set_BsConst_Lookup_Curve_HotSpot_Coef_X, operation=pp_CS_MemAbsSet.Set_BsConst_Lookup_Curve_HotSpot_Coef_X
        OperationInvokeEvent_92: start-on-event=MemAbstractMdl_Set_BsConst_Lookup_Curve_HotSpot_Coef_X_SafeCopy1, operation=pp_CS_MemAbsSet.Set_BsConst_Lookup_Curve_HotSpot_Coef_X_SafeCopy1
        OperationInvokeEvent_93: start-on-event=MemAbstractMdl_Set_BsConst_Lookup_Curve_HotSpot_Coef_X_SafeCopy2, operation=pp_CS_MemAbsSet.Set_BsConst_Lookup_Curve_HotSpot_Coef_X_SafeCopy2
        OIE_pp_CS_MemAbsSet_MemAbstractMdl_Set_BsConst_Lookup_Curve_HotSpot_Coef_YTrigBySet_BsConst_Lookup_Curve_HotSpot_Coef_Y: start-on-event=MemAbstractMdl_Set_BsConst_Lookup_Curve_HotSpot_Coef_Y, operation=pp_CS_MemAbsSet.Set_BsConst_Lookup_Curve_HotSpot_Coef_Y
        OperationInvokeEvent_94: start-on-event=MemAbstractMdl_Set_BsConst_Lookup_Curve_HotSpot_Coef_Y_SafeCopy1, operation=pp_CS_MemAbsSet.Set_BsConst_Lookup_Curve_HotSpot_Coef_Y_SafeCopy1
        OperationInvokeEvent_95: start-on-event=MemAbstractMdl_Set_BsConst_Lookup_Curve_HotSpot_Coef_Y_SafeCopy2, operation=pp_CS_MemAbsSet.Set_BsConst_Lookup_Curve_HotSpot_Coef_Y_SafeCopy2
        OIE_pp_CS_MemAbsSet_MemAbstractMdl_Set_BsConst_OilGauge_ElementTrigBySet_BsConst_OilGauge_Element: start-on-event=MemAbstractMdl_Set_BsConst_OilGauge_Element, operation=pp_CS_MemAbsSet.Set_BsConst_OilGauge_Element
        OIE_pp_CS_MemAbsSet_MemAbstractMdl_Set_BsConst_PCB_Temperature_Sensor_ConvTrigBySet_BsConst_PCB_Temperature_Sensor_Conv: start-on-event=MemAbstractMdl_Set_BsConst_PCB_Temperature_Sensor_Conv, operation=pp_CS_MemAbsSet.Set_BsConst_PCB_Temperature_Sensor_Conv
        OperationInvokeEvent_96: start-on-event=MemAbstractMdl_Set_BsConst_PCB_Temperature_Sensor_Conv_SafeCopy1, operation=pp_CS_MemAbsSet.Set_BsConst_PCB_Temperature_Sensor_Conv_SafeCopy1
        OperationInvokeEvent_97: start-on-event=MemAbstractMdl_Set_BsConst_PCB_Temperature_Sensor_Conv_SafeCopy2, operation=pp_CS_MemAbsSet.Set_BsConst_PCB_Temperature_Sensor_Conv_SafeCopy2
        OIE_pp_CS_MemAbsSet_MemAbstractMdl_Set_BsConst_PWM_boost_bypass_dutyTrigBySet_BsConst_PWM_boost_bypass_duty: start-on-event=MemAbstractMdl_Set_BsConst_PWM_boost_bypass_duty, operation=pp_CS_MemAbsSet.Set_BsConst_PWM_boost_bypass_duty
        OperationInvokeEvent_98: start-on-event=MemAbstractMdl_Set_BsConst_PWM_boost_bypass_duty_SafeCopy1, operation=pp_CS_MemAbsSet.Set_BsConst_PWM_boost_bypass_duty_SafeCopy1
        OperationInvokeEvent_99: start-on-event=MemAbstractMdl_Set_BsConst_PWM_boost_bypass_duty_SafeCopy2, operation=pp_CS_MemAbsSet.Set_BsConst_PWM_boost_bypass_duty_SafeCopy2
        OIE_pp_CS_MemAbsSet_MemAbstractMdl_Set_BsConst_PowerGauge_ElementTrigBySet_BsConst_PowerGauge_Element: start-on-event=MemAbstractMdl_Set_BsConst_PowerGauge_Element, operation=pp_CS_MemAbsSet.Set_BsConst_PowerGauge_Element
        OIE_pp_CS_MemAbsSet_MemAbstractMdl_Set_BsConst_Power_ElementTrigBySet_BsConst_Power_Element: start-on-event=MemAbstractMdl_Set_BsConst_Power_Element, operation=pp_CS_MemAbsSet.Set_BsConst_Power_Element
        OIE_pp_CS_MemAbsSet_MemAbstractMdl_Set_BsConst_RealTimeClock_ElementTrigBySet_BsConst_RealTimeClock_Element: start-on-event=MemAbstractMdl_Set_BsConst_RealTimeClock_Element, operation=pp_CS_MemAbsSet.Set_BsConst_RealTimeClock_Element
        OIE_pp_CS_MemAbsSet_MemAbstractMdl_Set_BsConst_ServiceReminder_ElementTrigBySet_BsConst_ServiceReminder_Element: start-on-event=MemAbstractMdl_Set_BsConst_ServiceReminder_Element, operation=pp_CS_MemAbsSet.Set_BsConst_ServiceReminder_Element
        OIE_pp_CS_MemAbsSet_MemAbstractMdl_Set_BsConst_SpeedoGauge_ElementTrigBySet_BsConst_SpeedoGauge_Element: start-on-event=MemAbstractMdl_Set_BsConst_SpeedoGauge_Element, operation=pp_CS_MemAbsSet.Set_BsConst_SpeedoGauge_Element
        OIE_pp_CS_MemAbsSet_MemAbstractMdl_Set_BsConst_TachoGauge_ElementTrigBySet_BsConst_TachoGauge_Element: start-on-event=MemAbstractMdl_Set_BsConst_TachoGauge_Element, operation=pp_CS_MemAbsSet.Set_BsConst_TachoGauge_Element
        OIE_pp_CS_MemAbsSet_MemAbstractMdl_Set_BsConst_TempGauge_ElementTrigBySet_BsConst_TempGauge_Element: start-on-event=MemAbstractMdl_Set_BsConst_TempGauge_Element, operation=pp_CS_MemAbsSet.Set_BsConst_TempGauge_Element
        OperationInvokeEvent_100: start-on-event=MemAbstractMdl_Set_BsConst_Temp_Threshold_Hysteresis_Derating, operation=pp_CS_MemAbsSet.Set_BsConst_Temp_Threshold_Hysteresis_Derating
        OperationInvokeEvent_101: start-on-event=MemAbstractMdl_Set_BsConst_Temp_Threshold_Hysteresis_Derating_SafeCopy1, operation=pp_CS_MemAbsSet.Set_BsConst_Temp_Threshold_Hysteresis_Derating_SafeCopy1
        OperationInvokeEvent_102: start-on-event=MemAbstractMdl_Set_BsConst_Temp_Threshold_Hysteresis_Derating_SafeCopy2, operation=pp_CS_MemAbsSet.Set_BsConst_Temp_Threshold_Hysteresis_Derating_SafeCopy2
        OIE_pp_CS_MemAbsSet_MemAbstractMdl_Set_BsConst_Temperature_Sensor_ConvTrigBySet_BsConst_Temperature_Sensor_Conv: start-on-event=MemAbstractMdl_Set_BsConst_Temperature_Sensor_Conv, operation=pp_CS_MemAbsSet.Set_BsConst_Temperature_Sensor_Conv
        OperationInvokeEvent_103: start-on-event=MemAbstractMdl_Set_BsConst_Temperature_Sensor_Conv_SafeCopy1, operation=pp_CS_MemAbsSet.Set_BsConst_Temperature_Sensor_Conv_SafeCopy1
        OperationInvokeEvent_104: start-on-event=MemAbstractMdl_Set_BsConst_Temperature_Sensor_Conv_SafeCopy2, operation=pp_CS_MemAbsSet.Set_BsConst_Temperature_Sensor_Conv_SafeCopy2
        OIE_pp_CS_MemAbsSet_MemAbstractMdl_Set_BsConst_TripComputer_ElementTrigBySet_BsConst_TripComputer_Element: start-on-event=MemAbstractMdl_Set_BsConst_TripComputer_Element, operation=pp_CS_MemAbsSet.Set_BsConst_TripComputer_Element
        OIE_pp_CS_MemAbsSet_MemAbstractMdl_Set_BsConst_Warning_ElementTrigBySet_BsConst_Warning_Element: start-on-event=MemAbstractMdl_Set_BsConst_Warning_Element, operation=pp_CS_MemAbsSet.Set_BsConst_Warning_Element
        OIE_pp_CS_MemAbsSet_MemAbstractMdl_Set_BsCys_Certicificate_ElementTrigBySet_BsCys_Certicificate_Element: start-on-event=MemAbstractMdl_Set_BsCys_Certicificate_Element, operation=pp_CS_MemAbsSet.Set_BsCys_Certicificate_Element
        OIE_pp_CS_MemAbsSet_MemAbstractMdl_Set_BsDiag_Dtc_ElementTrigBySet_BsDiag_Dtc_Element: start-on-event=MemAbstractMdl_Set_BsDiag_Dtc_Element, operation=pp_CS_MemAbsSet.Set_BsDiag_Dtc_Element
        OIE_pp_CS_MemAbsSet_MemAbstractMdl_Set_BsDiag_ErrorRecord_ElementTrigBySet_BsDiag_ErrorRecord_Element: start-on-event=MemAbstractMdl_Set_BsDiag_ErrorRecord_Element, operation=pp_CS_MemAbsSet.Set_BsDiag_ErrorRecord_Element
        OIE_pp_CS_MemAbsSet_MemAbstractMdl_Set_BsReten_Audio_ElementTrigBySet_BsReten_Audio_Element: start-on-event=MemAbstractMdl_Set_BsReten_Audio_Element, operation=pp_CS_MemAbsSet.Set_BsReten_Audio_Element
        OIE_pp_CS_MemAbsSet_MemAbstractMdl_Set_BsReten_Communication_ElementTrigBySet_BsReten_Communication_Element: start-on-event=MemAbstractMdl_Set_BsReten_Communication_Element, operation=pp_CS_MemAbsSet.Set_BsReten_Communication_Element
        OIE_pp_CS_MemAbsSet_MemAbstractMdl_Set_BsReten_Display_ElementTrigBySet_BsReten_Display_Element: start-on-event=MemAbstractMdl_Set_BsReten_Display_Element, operation=pp_CS_MemAbsSet.Set_BsReten_Display_Element
        OIE_pp_CS_MemAbsSet_MemAbstractMdl_Set_BsReten_Gauges_ElementTrigBySet_BsReten_Gauges_Element: start-on-event=MemAbstractMdl_Set_BsReten_Gauges_Element, operation=pp_CS_MemAbsSet.Set_BsReten_Gauges_Element
        OIE_pp_CS_MemAbsSet_MemAbstractMdl_Set_BsReten_Illumination_ElementTrigBySet_BsReten_Illumination_Element: start-on-event=MemAbstractMdl_Set_BsReten_Illumination_Element, operation=pp_CS_MemAbsSet.Set_BsReten_Illumination_Element
        OIE_pp_CS_MemAbsSet_MemAbstractMdl_Set_BsReten_Odometer_ElementTrigBySet_BsReten_Odometer_Element: start-on-event=MemAbstractMdl_Set_BsReten_Odometer_Element, operation=pp_CS_MemAbsSet.Set_BsReten_Odometer_Element
        OIE_pp_CS_MemAbsSet_MemAbstractMdl_Set_BsReten_Personalization_ElementTrigBySet_BsReten_Personalization_Element: start-on-event=MemAbstractMdl_Set_BsReten_Personalization_Element, operation=pp_CS_MemAbsSet.Set_BsReten_Personalization_Element
        OIE_pp_CS_MemAbsSet_MemAbstractMdl_Set_BsReten_Power_ElementTrigBySet_BsReten_Power_Element: start-on-event=MemAbstractMdl_Set_BsReten_Power_Element, operation=pp_CS_MemAbsSet.Set_BsReten_Power_Element
        OIE_pp_CS_MemAbsSet_MemAbstractMdl_Set_BsReten_RealTimeClock_ElementTrigBySet_BsReten_RealTimeClock_Element: start-on-event=MemAbstractMdl_Set_BsReten_RealTimeClock_Element, operation=pp_CS_MemAbsSet.Set_BsReten_RealTimeClock_Element
        OIE_pp_CS_MemAbsSet_MemAbstractMdl_Set_BsReten_Tripcomputer_ElementTrigBySet_BsReten_Tripcomputer_Element: start-on-event=MemAbstractMdl_Set_BsReten_Tripcomputer_Element, operation=pp_CS_MemAbsSet.Set_BsReten_Tripcomputer_Element
        OIE_pp_CS_MemAbsSet_MemAbstractMdl_Set_BsReten_Warning_ElementTrigBySet_BsReten_Warning_Element: start-on-event=MemAbstractMdl_Set_BsReten_Warning_Element, operation=pp_CS_MemAbsSet.Set_BsReten_Warning_Element
        OIE_pp_CS_MemAbsSet_MemAbstractMdl_Set_BsRt_CusDlt_ElementTrigBySet_BsRt_CusDlt_Element: start-on-event=MemAbstractMdl_Set_BsRt_CusDlt_Element, operation=pp_CS_MemAbsSet.Set_BsRt_CusDlt_Element
        OIE_pp_CS_MemAbsSet_MemAbstractMdl_Set_BsRt_FuelGauge_ElementTrigBySet_BsRt_FuelGauge_Element: start-on-event=MemAbstractMdl_Set_BsRt_FuelGauge_Element, operation=pp_CS_MemAbsSet.Set_BsRt_FuelGauge_Element
        OIE_pp_CS_MemAbsSet_MemAbstractMdl_Set_BsRt_Illumination_ElementTrigBySet_BsRt_Illumination_Element: start-on-event=MemAbstractMdl_Set_BsRt_Illumination_Element, operation=pp_CS_MemAbsSet.Set_BsRt_Illumination_Element
        OIE_pp_CS_MemAbsSet_MemAbstractMdl_Set_BsRt_Odometer_ElementTrigBySet_BsRt_Odometer_Element: start-on-event=MemAbstractMdl_Set_BsRt_Odometer_Element, operation=pp_CS_MemAbsSet.Set_BsRt_Odometer_Element
        OIE_pp_CS_MemAbsSet_MemAbstractMdl_Set_BsRt_OilGauge_ElementTrigBySet_BsRt_OilGauge_Element: start-on-event=MemAbstractMdl_Set_BsRt_OilGauge_Element, operation=pp_CS_MemAbsSet.Set_BsRt_OilGauge_Element
        OIE_pp_CS_MemAbsSet_MemAbstractMdl_Set_BsRt_Personalization_ElementTrigBySet_BsRt_Personalization_Element: start-on-event=MemAbstractMdl_Set_BsRt_Personalization_Element, operation=pp_CS_MemAbsSet.Set_BsRt_Personalization_Element
        OIE_pp_CS_MemAbsSet_MemAbstractMdl_Set_BsRt_PowerGauge_ElementTrigBySet_BsRt_PowerGauge_Element: start-on-event=MemAbstractMdl_Set_BsRt_PowerGauge_Element, operation=pp_CS_MemAbsSet.Set_BsRt_PowerGauge_Element
        OIE_pp_CS_MemAbsSet_MemAbstractMdl_Set_BsRt_RealTimeClock_ElementTrigBySet_BsRt_RealTimeClock_Element: start-on-event=MemAbstractMdl_Set_BsRt_RealTimeClock_Element, operation=pp_CS_MemAbsSet.Set_BsRt_RealTimeClock_Element
        OIE_pp_CS_MemAbsSet_MemAbstractMdl_Set_BsRt_SpeedoGauge_ElementTrigBySet_BsRt_SpeedoGauge_Element: start-on-event=MemAbstractMdl_Set_BsRt_SpeedoGauge_Element, operation=pp_CS_MemAbsSet.Set_BsRt_SpeedoGauge_Element
        OIE_pp_CS_MemAbsSet_MemAbstractMdl_Set_BsRt_TachoGauge_ElementTrigBySet_BsRt_TachoGauge_Element: start-on-event=MemAbstractMdl_Set_BsRt_TachoGauge_Element, operation=pp_CS_MemAbsSet.Set_BsRt_TachoGauge_Element
        OIE_pp_CS_MemAbsSet_MemAbstractMdl_Set_BsRt_TempGauge_ElementTrigBySet_BsRt_TempGauge_Element: start-on-event=MemAbstractMdl_Set_BsRt_TempGauge_Element, operation=pp_CS_MemAbsSet.Set_BsRt_TempGauge_Element
        OIE_pp_CS_MemAbsSet_MemAbstractMdl_Set_BsRt_TripComputer_ElementTrigBySet_BsRt_TripComputer_Element: start-on-event=MemAbstractMdl_Set_BsRt_TripComputer_Element, operation=pp_CS_MemAbsSet.Set_BsRt_TripComputer_Element
        OIE_pp_CS_MemAbsSet_MemAbstractMdl_Set_BsRt_Warning_ElementTrigBySet_BsRt_Warning_Element: start-on-event=MemAbstractMdl_Set_BsRt_Warning_Element, operation=pp_CS_MemAbsSet.Set_BsRt_Warning_Element
        OIE_pp_CS_MemAbsSet_MemAbstractMdl_Set_BsShare_AssemblyManufacturingDateTrigBySet_BsShare_AssemblyManufacturingDate: start-on-event=MemAbstractMdl_Set_BsShare_AssemblyManufacturingDate, operation=pp_CS_MemAbsSet.Set_BsShare_AssemblyManufacturingDate
        OIE_pp_CS_MemAbsSet_MemAbstractMdl_Set_BsShare_AssemblyPlantNumberTrigBySet_BsShare_AssemblyPlantNumber: start-on-event=MemAbstractMdl_Set_BsShare_AssemblyPlantNumber, operation=pp_CS_MemAbsSet.Set_BsShare_AssemblyPlantNumber
        OIE_pp_CS_MemAbsSet_MemAbstractMdl_Set_BsShare_EcuPartNumber_ElementTrigBySet_BsShare_EcuPartNumber_Element: start-on-event=MemAbstractMdl_Set_BsShare_EcuPartNumber_Element, operation=pp_CS_MemAbsSet.Set_BsShare_EcuPartNumber_Element
        OIE_pp_CS_MemAbsSet_MemAbstractMdl_Set_BsShare_HWModificationTrigBySet_BsShare_HWModification: start-on-event=MemAbstractMdl_Set_BsShare_HWModification, operation=pp_CS_MemAbsSet.Set_BsShare_HWModification
        OIE_pp_CS_MemAbsSet_MemAbstractMdl_Set_BsShare_PCBSerialNumberTrigBySet_BsShare_PCBSerialNumber: start-on-event=MemAbstractMdl_Set_BsShare_PCBSerialNumber, operation=pp_CS_MemAbsSet.Set_BsShare_PCBSerialNumber
        OIE_pp_CS_MemAbsSet_MemAbstractMdl_Set_BsShare_ProductSerialNumberTrigBySet_BsShare_ProductSerialNumber: start-on-event=MemAbstractMdl_Set_BsShare_ProductSerialNumber, operation=pp_CS_MemAbsSet.Set_BsShare_ProductSerialNumber
        OIE_pp_CS_MemAbsSet_MemAbstractMdl_Set_BsShare_SMTManufacturingDateTrigBySet_BsShare_SMTManufacturingDate: start-on-event=MemAbstractMdl_Set_BsShare_SMTManufacturingDate, operation=pp_CS_MemAbsSet.Set_BsShare_SMTManufacturingDate
        OIE_pp_CS_MemAbsSet_MemAbstractMdl_Set_BsShare_SMTPlantNumberTrigBySet_BsShare_SMTPlantNumber: start-on-event=MemAbstractMdl_Set_BsShare_SMTPlantNumber, operation=pp_CS_MemAbsSet.Set_BsShare_SMTPlantNumber
        OIE_pp_CS_MemAbsSet_MemAbstractMdl_Set_BsShare_SwUpdFotaFinPrint_ElementTrigBySet_BsShare_SwUpdFotaFinPrint_Element: start-on-event=MemAbstractMdl_Set_BsShare_SwUpdFotaFinPrint_Element, operation=pp_CS_MemAbsSet.Set_BsShare_SwUpdFotaFinPrint_Element
        OIE_pp_CS_MemAbsSet_MemAbstractMdl_Set_BsShare_SwUpdFotaMode_ElementTrigBySet_BsShare_SwUpdFotaMode_Element: start-on-event=MemAbstractMdl_Set_BsShare_SwUpdFotaMode_Element, operation=pp_CS_MemAbsSet.Set_BsShare_SwUpdFotaMode_Element
        OIE_pp_CS_MemAbsSet_MemAbstractMdl_Set_BsShare_SwUpdFotaStatus_ElementTrigBySet_BsShare_SwUpdFotaStatus_Element: start-on-event=MemAbstractMdl_Set_BsShare_SwUpdFotaStatus_Element, operation=pp_CS_MemAbsSet.Set_BsShare_SwUpdFotaStatus_Element
        OIE_pp_CS_MemAbsSet_MemAbstractMdl_Set_BsShare_SwUpdFotadecrypt_ElementTrigBySet_BsShare_SwUpdFotadecrypt_Element: start-on-event=MemAbstractMdl_Set_BsShare_SwUpdFotadecrypt_Element, operation=pp_CS_MemAbsSet.Set_BsShare_SwUpdFotadecrypt_Element
        OIE_pp_CS_MemAbsSet_MemAbstractMdl_Set_BsShare_SwUpdReflash_ElementTrigBySet_BsShare_SwUpdReflash_Element: start-on-event=MemAbstractMdl_Set_BsShare_SwUpdReflash_Element, operation=pp_CS_MemAbsSet.Set_BsShare_SwUpdReflash_Element
        OIE_pp_CS_MemAbsSet_MemAbstractMdl_Set_BsShare_VehicleConfig_ElementTrigBySet_BsShare_VehicleConfig_Element: start-on-event=MemAbstractMdl_Set_BsShare_VehicleConfig_Element, operation=pp_CS_MemAbsSet.Set_BsShare_VehicleConfig_Element
        OIE_pp_CS_MemAbsSet_MemAbstractMdl_Set_BsShare_VisMeet_EOLEntry_ElementTrigBySet_BsShare_VisMeet_EOLEntry_Element: start-on-event=MemAbstractMdl_Set_BsShare_VisMeet_EOLEntry_Element, operation=pp_CS_MemAbsSet.Set_BsShare_VisMeet_EOLEntry_Element
        OIE_pp_CS_MemAbsSet_MemAbstractMdl_Set_BsShare_VisMeet_ElementTrigBySet_BsShare_VisMeet_Element: start-on-event=MemAbstractMdl_Set_BsShare_VisMeet_Element, operation=pp_CS_MemAbsSet.Set_BsShare_VisMeet_Element
        OIE_pp_CS_MemAbsSet_MemAbstractMdl_Set_BsShare_VisteonPCBPartNumberTrigBySet_BsShare_VisteonPCBPartNumber: start-on-event=MemAbstractMdl_Set_BsShare_VisteonPCBPartNumber, operation=pp_CS_MemAbsSet.Set_BsShare_VisteonPCBPartNumber
        OIE_pp_CS_MemAbsSet_MemAbstractMdl_Set_BsShare_VisteonPartNumberTrigBySet_BsShare_VisteonPartNumber: start-on-event=MemAbstractMdl_Set_BsShare_VisteonPartNumber, operation=pp_CS_MemAbsSet.Set_BsShare_VisteonPartNumber
        OIE_pp_CS_MemAbsSet_MemAbstractMdl_Set_RefCys_Certicificate1_ElementTrigBySet_RefCys_Certicificate1_Element: start-on-event=MemAbstractMdl_Set_RefCys_Certicificate1_Element, operation=pp_CS_MemAbsSet.Set_RefCys_Certicificate1_Element
        OIE_pp_CS_MemAbsSet_MemAbstractMdl_Set_RefCys_Certicificate_ElementTrigBySet_RefCys_Certicificate_Element: start-on-event=MemAbstractMdl_Set_RefCys_Certicificate_Element, operation=pp_CS_MemAbsSet.Set_RefCys_Certicificate_Element
      port-api-options:
        enable-take-address=false, indirect-api=false, port=pp_CS_MemAbsGet
        enable-take-address=false, indirect-api=false, port=pp_CS_MemAbsGetDefault
        enable-take-address=false, indirect-api=false, port=pp_CS_MemAbsSet
        enable-take-address=false, indirect-api=false, port=pp_CS_MemAbs_NvMWriteStatus
        enable-take-address=false, indirect-api=false, port=pp_CmpLibCmd_MemAbstractMdl
        enable-take-address=false, indirect-api=false, port=pp_SR_JobStatus
      285 x runnable, all with can-be-invoked-concurrently=true:
        CMemAbstractMdl_Impl_MainFunction
          data-send-points:
            94 x access:
              DWA_pp_SR_JobStatus_JobStatus_BsConst_Audio_Element: accessed-variable=pp_SR_JobStatus.JobStatus_BsConst_Audio_Element
              DWA_pp_SR_JobStatus_JobStatus_BsConst_BsConst_Illumination_ReservedByte: accessed-variable=pp_SR_JobStatus.JobStatus_BsConst_BsConst_Illumination_ReservedByte
              DWA_pp_SR_JobStatus_JobStatus_BsConst_BsConst_Illumination_ReservedByte_SafeCopy1: accessed-variable=pp_SR_JobStatus.JobStatus_BsConst_BsConst_Illumination_ReservedByte_SafeCopy1
              DWA_pp_SR_JobStatus_JobStatus_BsConst_BsConst_Illumination_ReservedByte_SafeCopy2: accessed-variable=pp_SR_JobStatus.JobStatus_BsConst_BsConst_Illumination_ReservedByte_SafeCopy2
              DWA_pp_SR_JobStatus_JobStatus_BsConst_Communication_Element: accessed-variable=pp_SR_JobStatus.JobStatus_BsConst_Communication_Element
              DWA_pp_SR_JobStatus_JobStatus_BsConst_Compensation_Line_Shift_b: accessed-variable=pp_SR_JobStatus.JobStatus_BsConst_Compensation_Line_Shift_b
              DWA_pp_SR_JobStatus_JobStatus_BsConst_Compensation_Line_Shift_b_SafeCopy1: accessed-variable=pp_SR_JobStatus.JobStatus_BsConst_Compensation_Line_Shift_b_SafeCopy1
              DWA_pp_SR_JobStatus_JobStatus_BsConst_Compensation_Line_Shift_b_SafeCopy2: accessed-variable=pp_SR_JobStatus.JobStatus_BsConst_Compensation_Line_Shift_b_SafeCopy2
              DWA_pp_SR_JobStatus_JobStatus_BsConst_Compensation_Line_Slope_m: accessed-variable=pp_SR_JobStatus.JobStatus_BsConst_Compensation_Line_Slope_m
              DWA_pp_SR_JobStatus_JobStatus_BsConst_Compensation_Line_Slope_m_SafeCopy1: accessed-variable=pp_SR_JobStatus.JobStatus_BsConst_Compensation_Line_Slope_m_SafeCopy1
              DWA_pp_SR_JobStatus_JobStatus_BsConst_Compensation_Line_Slope_m_SafeCopy2: accessed-variable=pp_SR_JobStatus.JobStatus_BsConst_Compensation_Line_Slope_m_SafeCopy2
              DWA_pp_SR_JobStatus_JobStatus_BsConst_Derating_Backlight_Disable: accessed-variable=pp_SR_JobStatus.JobStatus_BsConst_Derating_Backlight_Disable
              DWA_pp_SR_JobStatus_JobStatus_BsConst_Derating_Backlight_Disable_SafeCopy1: accessed-variable=pp_SR_JobStatus.JobStatus_BsConst_Derating_Backlight_Disable_SafeCopy1
              DWA_pp_SR_JobStatus_JobStatus_BsConst_Derating_Backlight_Disable_SafeCopy2: accessed-variable=pp_SR_JobStatus.JobStatus_BsConst_Derating_Backlight_Disable_SafeCopy2
              DWA_pp_SR_JobStatus_JobStatus_BsConst_Display_Illum_Max_Level: accessed-variable=pp_SR_JobStatus.JobStatus_BsConst_Display_Illum_Max_Level
              DWA_pp_SR_JobStatus_JobStatus_BsConst_Display_Illum_Max_Level_SafeCopy1: accessed-variable=pp_SR_JobStatus.JobStatus_BsConst_Display_Illum_Max_Level_SafeCopy1
              DWA_pp_SR_JobStatus_JobStatus_BsConst_Display_Illum_Max_Level_SafeCopy2: accessed-variable=pp_SR_JobStatus.JobStatus_BsConst_Display_Illum_Max_Level_SafeCopy2
              DWA_pp_SR_JobStatus_JobStatus_BsConst_EngOffTimer_Element: accessed-variable=pp_SR_JobStatus.JobStatus_BsConst_EngOffTimer_Element
              DWA_pp_SR_JobStatus_JobStatus_BsConst_FuelGauge_Element: accessed-variable=pp_SR_JobStatus.JobStatus_BsConst_FuelGauge_Element
              DWA_pp_SR_JobStatus_JobStatus_BsConst_Lookup_Curve_HotSpot_Coef_X: accessed-variable=pp_SR_JobStatus.JobStatus_BsConst_Lookup_Curve_HotSpot_Coef_X
              DWA_pp_SR_JobStatus_JobStatus_BsConst_Lookup_Curve_HotSpot_Coef_X_SafeCopy1: accessed-variable=pp_SR_JobStatus.JobStatus_BsConst_Lookup_Curve_HotSpot_Coef_X_SafeCopy1
              DWA_pp_SR_JobStatus_JobStatus_BsConst_Lookup_Curve_HotSpot_Coef_X_SafeCopy2: accessed-variable=pp_SR_JobStatus.JobStatus_BsConst_Lookup_Curve_HotSpot_Coef_X_SafeCopy2
              DWA_pp_SR_JobStatus_JobStatus_BsConst_Lookup_Curve_HotSpot_Coef_Y: accessed-variable=pp_SR_JobStatus.JobStatus_BsConst_Lookup_Curve_HotSpot_Coef_Y
              DWA_pp_SR_JobStatus_JobStatus_BsConst_Lookup_Curve_HotSpot_Coef_Y_SafeCopy1: accessed-variable=pp_SR_JobStatus.JobStatus_BsConst_Lookup_Curve_HotSpot_Coef_Y_SafeCopy1
              DWA_pp_SR_JobStatus_JobStatus_BsConst_Lookup_Curve_HotSpot_Coef_Y_SafeCopy2: accessed-variable=pp_SR_JobStatus.JobStatus_BsConst_Lookup_Curve_HotSpot_Coef_Y_SafeCopy2
              DWA_pp_SR_JobStatus_JobStatus_BsConst_OilGauge_Element: accessed-variable=pp_SR_JobStatus.JobStatus_BsConst_OilGauge_Element
              DWA_pp_SR_JobStatus_JobStatus_BsConst_PCB_Temperature_Sensor_Conv: accessed-variable=pp_SR_JobStatus.JobStatus_BsConst_PCB_Temperature_Sensor_Conv
              DWA_pp_SR_JobStatus_JobStatus_BsConst_PCB_Temperature_Sensor_Conv_SafeCopy1: accessed-variable=pp_SR_JobStatus.JobStatus_BsConst_PCB_Temperature_Sensor_Conv_SafeCopy1
              DWA_pp_SR_JobStatus_JobStatus_BsConst_PCB_Temperature_Sensor_Conv_SafeCopy2: accessed-variable=pp_SR_JobStatus.JobStatus_BsConst_PCB_Temperature_Sensor_Conv_SafeCopy2
              DWA_pp_SR_JobStatus_JobStatus_BsConst_PWM_boost_bypass_duty: accessed-variable=pp_SR_JobStatus.JobStatus_BsConst_PWM_boost_bypass_duty
              DWA_pp_SR_JobStatus_JobStatus_BsConst_PWM_boost_bypass_duty_SafeCopy1: accessed-variable=pp_SR_JobStatus.JobStatus_BsConst_PWM_boost_bypass_duty_SafeCopy1
              DWA_pp_SR_JobStatus_JobStatus_BsConst_PWM_boost_bypass_duty_SafeCopy2: accessed-variable=pp_SR_JobStatus.JobStatus_BsConst_PWM_boost_bypass_duty_SafeCopy2
              DWA_pp_SR_JobStatus_JobStatus_BsConst_PowerGauge_Element: accessed-variable=pp_SR_JobStatus.JobStatus_BsConst_PowerGauge_Element
              DWA_pp_SR_JobStatus_JobStatus_BsConst_Power_Element: accessed-variable=pp_SR_JobStatus.JobStatus_BsConst_Power_Element
              DWA_pp_SR_JobStatus_JobStatus_BsConst_RealTimeClock_Element: accessed-variable=pp_SR_JobStatus.JobStatus_BsConst_RealTimeClock_Element
              DWA_pp_SR_JobStatus_JobStatus_BsConst_ServiceReminder_Element: accessed-variable=pp_SR_JobStatus.JobStatus_BsConst_ServiceReminder_Element
              DWA_pp_SR_JobStatus_JobStatus_BsConst_SpeedoGauge_Element: accessed-variable=pp_SR_JobStatus.JobStatus_BsConst_SpeedoGauge_Element
              DWA_pp_SR_JobStatus_JobStatus_BsConst_TachoGauge_Element: accessed-variable=pp_SR_JobStatus.JobStatus_BsConst_TachoGauge_Element
              DWA_pp_SR_JobStatus_JobStatus_BsConst_TempGauge_Element: accessed-variable=pp_SR_JobStatus.JobStatus_BsConst_TempGauge_Element
              DWA_pp_SR_JobStatus_JobStatus_BsConst_Temp_Threshold_Hysteresis_Derating: accessed-variable=pp_SR_JobStatus.JobStatus_BsConst_Temp_Threshold_Hysteresis_Derating
              DWA_pp_SR_JobStatus_JobStatus_BsConst_Temp_Threshold_Hysteresis_Derating_SafeCopy1: accessed-variable=pp_SR_JobStatus.JobStatus_BsConst_Temp_Threshold_Hysteresis_Derating_SafeCopy1
              DWA_pp_SR_JobStatus_JobStatus_BsConst_Temp_Threshold_Hysteresis_Derating_SafeCopy2: accessed-variable=pp_SR_JobStatus.JobStatus_BsConst_Temp_Threshold_Hysteresis_Derating_SafeCopy2
              DWA_pp_SR_JobStatus_JobStatus_BsConst_Temperature_Sensor_Conv: accessed-variable=pp_SR_JobStatus.JobStatus_BsConst_Temperature_Sensor_Conv
              DWA_pp_SR_JobStatus_JobStatus_BsConst_Temperature_Sensor_Conv_SafeCopy1: accessed-variable=pp_SR_JobStatus.JobStatus_BsConst_Temperature_Sensor_Conv_SafeCopy1
              DWA_pp_SR_JobStatus_JobStatus_BsConst_Temperature_Sensor_Conv_SafeCopy2: accessed-variable=pp_SR_JobStatus.JobStatus_BsConst_Temperature_Sensor_Conv_SafeCopy2
              DWA_pp_SR_JobStatus_JobStatus_BsConst_TripComputer_Element: accessed-variable=pp_SR_JobStatus.JobStatus_BsConst_TripComputer_Element
              DWA_pp_SR_JobStatus_JobStatus_BsConst_Warning_Element: accessed-variable=pp_SR_JobStatus.JobStatus_BsConst_Warning_Element
              DWA_pp_SR_JobStatus_JobStatus_BsCys_Certicificate_Element: accessed-variable=pp_SR_JobStatus.JobStatus_BsCys_Certicificate_Element
              DWA_pp_SR_JobStatus_JobStatus_BsDiag_Dtc_Element: accessed-variable=pp_SR_JobStatus.JobStatus_BsDiag_Dtc_Element
              DWA_pp_SR_JobStatus_JobStatus_BsDiag_ErrorRecord_Element: accessed-variable=pp_SR_JobStatus.JobStatus_BsDiag_ErrorRecord_Element
              DWA_pp_SR_JobStatus_JobStatus_BsReten_Audio_Element: accessed-variable=pp_SR_JobStatus.JobStatus_BsReten_Audio_Element
              DWA_pp_SR_JobStatus_JobStatus_BsReten_Communication_Element: accessed-variable=pp_SR_JobStatus.JobStatus_BsReten_Communication_Element
              DWA_pp_SR_JobStatus_JobStatus_BsReten_Display_Element: accessed-variable=pp_SR_JobStatus.JobStatus_BsReten_Display_Element
              DWA_pp_SR_JobStatus_JobStatus_BsReten_Gauges_Element: accessed-variable=pp_SR_JobStatus.JobStatus_BsReten_Gauges_Element
              DWA_pp_SR_JobStatus_JobStatus_BsReten_Illumination_Element: accessed-variable=pp_SR_JobStatus.JobStatus_BsReten_Illumination_Element
              DWA_pp_SR_JobStatus_JobStatus_BsReten_Odometer_Element: accessed-variable=pp_SR_JobStatus.JobStatus_BsReten_Odometer_Element
              DWA_pp_SR_JobStatus_JobStatus_BsReten_Personalization_Element: accessed-variable=pp_SR_JobStatus.JobStatus_BsReten_Personalization_Element
              DWA_pp_SR_JobStatus_JobStatus_BsReten_Power_Element: accessed-variable=pp_SR_JobStatus.JobStatus_BsReten_Power_Element
              DWA_pp_SR_JobStatus_JobStatus_BsReten_RealTimeClock_Element: accessed-variable=pp_SR_JobStatus.JobStatus_BsReten_RealTimeClock_Element
              DWA_pp_SR_JobStatus_JobStatus_BsReten_Tripcomputer_Element: accessed-variable=pp_SR_JobStatus.JobStatus_BsReten_Tripcomputer_Element
              DWA_pp_SR_JobStatus_JobStatus_BsReten_Warning_Element: accessed-variable=pp_SR_JobStatus.JobStatus_BsReten_Warning_Element
              DWA_pp_SR_JobStatus_JobStatus_BsRt_CusDlt_Element: accessed-variable=pp_SR_JobStatus.JobStatus_BsRt_CusDlt_Element
              DWA_pp_SR_JobStatus_JobStatus_BsRt_FuelGauge_Element: accessed-variable=pp_SR_JobStatus.JobStatus_BsRt_FuelGauge_Element
              DWA_pp_SR_JobStatus_JobStatus_BsRt_Illumination_Element: accessed-variable=pp_SR_JobStatus.JobStatus_BsRt_Illumination_Element
              DWA_pp_SR_JobStatus_JobStatus_BsRt_Odometer_Element: accessed-variable=pp_SR_JobStatus.JobStatus_BsRt_Odometer_Element
              DWA_pp_SR_JobStatus_JobStatus_BsRt_OilGauge_Element: accessed-variable=pp_SR_JobStatus.JobStatus_BsRt_OilGauge_Element
              DWA_pp_SR_JobStatus_JobStatus_BsRt_Personalization_Element: accessed-variable=pp_SR_JobStatus.JobStatus_BsRt_Personalization_Element
              DWA_pp_SR_JobStatus_JobStatus_BsRt_PowerGauge_Element: accessed-variable=pp_SR_JobStatus.JobStatus_BsRt_PowerGauge_Element
              DWA_pp_SR_JobStatus_JobStatus_BsRt_RealTimeClock_Element: accessed-variable=pp_SR_JobStatus.JobStatus_BsRt_RealTimeClock_Element
              DWA_pp_SR_JobStatus_JobStatus_BsRt_SpeedoGauge_Element: accessed-variable=pp_SR_JobStatus.JobStatus_BsRt_SpeedoGauge_Element
              DWA_pp_SR_JobStatus_JobStatus_BsRt_TachoGauge_Element: accessed-variable=pp_SR_JobStatus.JobStatus_BsRt_TachoGauge_Element
              DWA_pp_SR_JobStatus_JobStatus_BsRt_TempGauge_Element: accessed-variable=pp_SR_JobStatus.JobStatus_BsRt_TempGauge_Element
              DWA_pp_SR_JobStatus_JobStatus_BsRt_TripComputer_Element: accessed-variable=pp_SR_JobStatus.JobStatus_BsRt_TripComputer_Element
              DWA_pp_SR_JobStatus_JobStatus_BsRt_Warning_Element: accessed-variable=pp_SR_JobStatus.JobStatus_BsRt_Warning_Element
              DWA_pp_SR_JobStatus_JobStatus_BsShare_AssemblyManufacturingDate: accessed-variable=pp_SR_JobStatus.JobStatus_BsShare_AssemblyManufacturingDate
              DWA_pp_SR_JobStatus_JobStatus_BsShare_AssemblyPlantNumber: accessed-variable=pp_SR_JobStatus.JobStatus_BsShare_AssemblyPlantNumber
              DWA_pp_SR_JobStatus_JobStatus_BsShare_EcuPartNumber_Element: accessed-variable=pp_SR_JobStatus.JobStatus_BsShare_EcuPartNumber_Element
              DWA_pp_SR_JobStatus_JobStatus_BsShare_HWModification: accessed-variable=pp_SR_JobStatus.JobStatus_BsShare_HWModification
              DWA_pp_SR_JobStatus_JobStatus_BsShare_PCBSerialNumber: accessed-variable=pp_SR_JobStatus.JobStatus_BsShare_PCBSerialNumber
              DWA_pp_SR_JobStatus_JobStatus_BsShare_ProductSerialNumber: accessed-variable=pp_SR_JobStatus.JobStatus_BsShare_ProductSerialNumber
              DWA_pp_SR_JobStatus_JobStatus_BsShare_SMTManufacturingDate: accessed-variable=pp_SR_JobStatus.JobStatus_BsShare_SMTManufacturingDate
              DWA_pp_SR_JobStatus_JobStatus_BsShare_SMTPlantNumber: accessed-variable=pp_SR_JobStatus.JobStatus_BsShare_SMTPlantNumber
              DWA_pp_SR_JobStatus_JobStatus_BsShare_SwUpdFotaFinPrint_Element: accessed-variable=pp_SR_JobStatus.JobStatus_BsShare_SwUpdFotaFinPrint_Element
              DWA_pp_SR_JobStatus_JobStatus_BsShare_SwUpdFotaMode_Element: accessed-variable=pp_SR_JobStatus.JobStatus_BsShare_SwUpdFotaMode_Element
              DWA_pp_SR_JobStatus_JobStatus_BsShare_SwUpdFotaStatus_Element: accessed-variable=pp_SR_JobStatus.JobStatus_BsShare_SwUpdFotaStatus_Element
              DWA_pp_SR_JobStatus_JobStatus_BsShare_SwUpdFotadecrypt_Element: accessed-variable=pp_SR_JobStatus.JobStatus_BsShare_SwUpdFotadecrypt_Element
              DWA_pp_SR_JobStatus_JobStatus_BsShare_SwUpdReflash_Element: accessed-variable=pp_SR_JobStatus.JobStatus_BsShare_SwUpdReflash_Element
              DWA_pp_SR_JobStatus_JobStatus_BsShare_VehicleConfig_Element: accessed-variable=pp_SR_JobStatus.JobStatus_BsShare_VehicleConfig_Element
              DWA_pp_SR_JobStatus_JobStatus_BsShare_VisMeet_EOLEntry_Element: accessed-variable=pp_SR_JobStatus.JobStatus_BsShare_VisMeet_EOLEntry_Element
              DWA_pp_SR_JobStatus_JobStatus_BsShare_VisMeet_Element: accessed-variable=pp_SR_JobStatus.JobStatus_BsShare_VisMeet_Element
              DWA_pp_SR_JobStatus_JobStatus_BsShare_VisteonPCBPartNumber: accessed-variable=pp_SR_JobStatus.JobStatus_BsShare_VisteonPCBPartNumber
              DWA_pp_SR_JobStatus_JobStatus_BsShare_VisteonPartNumber: accessed-variable=pp_SR_JobStatus.JobStatus_BsShare_VisteonPartNumber
              DWA_pp_SR_JobStatus_JobStatus_RefCys_Certicificate1_Element: accessed-variable=pp_SR_JobStatus.JobStatus_RefCys_Certicificate1_Element
              DWA_pp_SR_JobStatus_JobStatus_RefCys_Certicificate_Element: accessed-variable=pp_SR_JobStatus.JobStatus_RefCys_Certicificate_Element
        CMemAbstractMdl_Impl_OnCommand
        MemAbstractMdl_Get_BsConst_Audio_Element
        MemAbstractMdl_Get_BsConst_BsConst_Illumination_ReservedByte
        MemAbstractMdl_Get_BsConst_BsConst_Illumination_ReservedByte_SafeCopy1
        MemAbstractMdl_Get_BsConst_BsConst_Illumination_ReservedByte_SafeCopy2
        MemAbstractMdl_Get_BsConst_Communication_Element
        MemAbstractMdl_Get_BsConst_Compensation_Line_Shift_b
        MemAbstractMdl_Get_BsConst_Compensation_Line_Shift_b_SafeCopy1
        MemAbstractMdl_Get_BsConst_Compensation_Line_Shift_b_SafeCopy2
        MemAbstractMdl_Get_BsConst_Compensation_Line_Slope_m
        MemAbstractMdl_Get_BsConst_Compensation_Line_Slope_m_SafeCopy1
        MemAbstractMdl_Get_BsConst_Compensation_Line_Slope_m_SafeCopy2
        MemAbstractMdl_Get_BsConst_Derating_Backlight_Disable
        MemAbstractMdl_Get_BsConst_Derating_Backlight_Disable_SafeCopy1
        MemAbstractMdl_Get_BsConst_Derating_Backlight_Disable_SafeCopy2
        MemAbstractMdl_Get_BsConst_Display_Illum_Max_Level
        MemAbstractMdl_Get_BsConst_Display_Illum_Max_Level_SafeCopy1
        MemAbstractMdl_Get_BsConst_Display_Illum_Max_Level_SafeCopy2
        MemAbstractMdl_Get_BsConst_EngOffTimer_Element
        MemAbstractMdl_Get_BsConst_FuelGauge_Element
        MemAbstractMdl_Get_BsConst_Lookup_Curve_HotSpot_Coef_X
        MemAbstractMdl_Get_BsConst_Lookup_Curve_HotSpot_Coef_X_SafeCopy1
        MemAbstractMdl_Get_BsConst_Lookup_Curve_HotSpot_Coef_X_SafeCopy2
        MemAbstractMdl_Get_BsConst_Lookup_Curve_HotSpot_Coef_Y
        MemAbstractMdl_Get_BsConst_Lookup_Curve_HotSpot_Coef_Y_SafeCopy1
        MemAbstractMdl_Get_BsConst_Lookup_Curve_HotSpot_Coef_Y_SafeCopy2
        MemAbstractMdl_Get_BsConst_OilGauge_Element
        MemAbstractMdl_Get_BsConst_PCB_Temperature_Sensor_Conv
        MemAbstractMdl_Get_BsConst_PCB_Temperature_Sensor_Conv_SafeCopy1
        MemAbstractMdl_Get_BsConst_PCB_Temperature_Sensor_Conv_SafeCopy2
        MemAbstractMdl_Get_BsConst_PWM_boost_bypass_duty
        MemAbstractMdl_Get_BsConst_PWM_boost_bypass_duty_SafeCopy1
        MemAbstractMdl_Get_BsConst_PWM_boost_bypass_duty_SafeCopy2
        MemAbstractMdl_Get_BsConst_PowerGauge_Element
        MemAbstractMdl_Get_BsConst_Power_Element
        MemAbstractMdl_Get_BsConst_RealTimeClock_Element
        MemAbstractMdl_Get_BsConst_ServiceReminder_Element
        MemAbstractMdl_Get_BsConst_SpeedoGauge_Element
        MemAbstractMdl_Get_BsConst_TachoGauge_Element
        MemAbstractMdl_Get_BsConst_TempGauge_Element
        MemAbstractMdl_Get_BsConst_Temp_Threshold_Hysteresis_Derating
        MemAbstractMdl_Get_BsConst_Temp_Threshold_Hysteresis_Derating_SafeCopy1
        MemAbstractMdl_Get_BsConst_Temp_Threshold_Hysteresis_Derating_SafeCopy2
        MemAbstractMdl_Get_BsConst_Temperature_Sensor_Conv
        MemAbstractMdl_Get_BsConst_Temperature_Sensor_Conv_SafeCopy1
        MemAbstractMdl_Get_BsConst_Temperature_Sensor_Conv_SafeCopy2
        MemAbstractMdl_Get_BsConst_TripComputer_Element
        MemAbstractMdl_Get_BsConst_Warning_Element
        MemAbstractMdl_Get_BsCys_Certicificate_Element
        MemAbstractMdl_Get_BsDiag_Dtc_Element
        MemAbstractMdl_Get_BsDiag_ErrorRecord_Element
        MemAbstractMdl_Get_BsReten_Audio_Element
        MemAbstractMdl_Get_BsReten_Communication_Element
        MemAbstractMdl_Get_BsReten_Display_Element
        MemAbstractMdl_Get_BsReten_Gauges_Element
        MemAbstractMdl_Get_BsReten_Illumination_Element
        MemAbstractMdl_Get_BsReten_Odometer_Element
        MemAbstractMdl_Get_BsReten_Personalization_Element
        MemAbstractMdl_Get_BsReten_Power_Element
        MemAbstractMdl_Get_BsReten_RealTimeClock_Element
        MemAbstractMdl_Get_BsReten_Tripcomputer_Element
        MemAbstractMdl_Get_BsReten_Warning_Element
        MemAbstractMdl_Get_BsRt_CusDlt_Element
        MemAbstractMdl_Get_BsRt_FuelGauge_Element
        MemAbstractMdl_Get_BsRt_Illumination_Element
        MemAbstractMdl_Get_BsRt_Odometer_Element
        MemAbstractMdl_Get_BsRt_OilGauge_Element
        MemAbstractMdl_Get_BsRt_Personalization_Element
        MemAbstractMdl_Get_BsRt_PowerGauge_Element
        MemAbstractMdl_Get_BsRt_RealTimeClock_Element
        MemAbstractMdl_Get_BsRt_SpeedoGauge_Element
        MemAbstractMdl_Get_BsRt_TachoGauge_Element
        MemAbstractMdl_Get_BsRt_TempGauge_Element
        MemAbstractMdl_Get_BsRt_TripComputer_Element
        MemAbstractMdl_Get_BsRt_Warning_Element
        MemAbstractMdl_Get_BsShare_AssemblyManufacturingDate
        MemAbstractMdl_Get_BsShare_AssemblyPlantNumber
        MemAbstractMdl_Get_BsShare_EcuPartNumber_Element
        MemAbstractMdl_Get_BsShare_HWModification
        MemAbstractMdl_Get_BsShare_PCBSerialNumber
        MemAbstractMdl_Get_BsShare_ProductSerialNumber
        MemAbstractMdl_Get_BsShare_SMTManufacturingDate
        MemAbstractMdl_Get_BsShare_SMTPlantNumber
        MemAbstractMdl_Get_BsShare_SwUpdFotaFinPrint_Element
        MemAbstractMdl_Get_BsShare_SwUpdFotaMode_Element
        MemAbstractMdl_Get_BsShare_SwUpdFotaStatus_Element
        MemAbstractMdl_Get_BsShare_SwUpdFotadecrypt_Element
        MemAbstractMdl_Get_BsShare_SwUpdReflash_Element
        MemAbstractMdl_Get_BsShare_VehicleConfig_Element
        MemAbstractMdl_Get_BsShare_VisMeet_EOLEntry_Element
        MemAbstractMdl_Get_BsShare_VisMeet_Element
        MemAbstractMdl_Get_BsShare_VisteonPCBPartNumber
        MemAbstractMdl_Get_BsShare_VisteonPartNumber
        MemAbstractMdl_Get_Default_BsConst_Audio_Element
        MemAbstractMdl_Get_Default_BsConst_BsConst_Illumination_ReservedByte
        MemAbstractMdl_Get_Default_BsConst_BsConst_Illumination_ReservedByte_SafeCopy1
        MemAbstractMdl_Get_Default_BsConst_BsConst_Illumination_ReservedByte_SafeCopy2
        MemAbstractMdl_Get_Default_BsConst_Communication_Element
        MemAbstractMdl_Get_Default_BsConst_Compensation_Line_Shift_b
        MemAbstractMdl_Get_Default_BsConst_Compensation_Line_Shift_b_SafeCopy1
        MemAbstractMdl_Get_Default_BsConst_Compensation_Line_Shift_b_SafeCopy2
        MemAbstractMdl_Get_Default_BsConst_Compensation_Line_Slope_m
        MemAbstractMdl_Get_Default_BsConst_Compensation_Line_Slope_m_SafeCopy1
        MemAbstractMdl_Get_Default_BsConst_Compensation_Line_Slope_m_SafeCopy2
        MemAbstractMdl_Get_Default_BsConst_Derating_Backlight_Disable
        MemAbstractMdl_Get_Default_BsConst_Derating_Backlight_Disable_SafeCopy1
        MemAbstractMdl_Get_Default_BsConst_Derating_Backlight_Disable_SafeCopy2
        MemAbstractMdl_Get_Default_BsConst_Display_Illum_Max_Level
        MemAbstractMdl_Get_Default_BsConst_Display_Illum_Max_Level_SafeCopy1
        MemAbstractMdl_Get_Default_BsConst_Display_Illum_Max_Level_SafeCopy2
        MemAbstractMdl_Get_Default_BsConst_EngOffTimer_Element
        MemAbstractMdl_Get_Default_BsConst_FuelGauge_Element
        MemAbstractMdl_Get_Default_BsConst_Lookup_Curve_HotSpot_Coef_X
        MemAbstractMdl_Get_Default_BsConst_Lookup_Curve_HotSpot_Coef_X_SafeCopy1
        MemAbstractMdl_Get_Default_BsConst_Lookup_Curve_HotSpot_Coef_X_SafeCopy2
        MemAbstractMdl_Get_Default_BsConst_Lookup_Curve_HotSpot_Coef_Y
        MemAbstractMdl_Get_Default_BsConst_Lookup_Curve_HotSpot_Coef_Y_SafeCopy1
        MemAbstractMdl_Get_Default_BsConst_Lookup_Curve_HotSpot_Coef_Y_SafeCopy2
        MemAbstractMdl_Get_Default_BsConst_OilGauge_Element
        MemAbstractMdl_Get_Default_BsConst_PCB_Temperature_Sensor_Conv
        MemAbstractMdl_Get_Default_BsConst_PCB_Temperature_Sensor_Conv_SafeCopy1
        MemAbstractMdl_Get_Default_BsConst_PCB_Temperature_Sensor_Conv_SafeCopy2
        MemAbstractMdl_Get_Default_BsConst_PWM_boost_bypass_duty
        MemAbstractMdl_Get_Default_BsConst_PWM_boost_bypass_duty_SafeCopy1
        MemAbstractMdl_Get_Default_BsConst_PWM_boost_bypass_duty_SafeCopy2
        MemAbstractMdl_Get_Default_BsConst_PowerGauge_Element
        MemAbstractMdl_Get_Default_BsConst_Power_Element
        MemAbstractMdl_Get_Default_BsConst_RealTimeClock_Element
        MemAbstractMdl_Get_Default_BsConst_ServiceReminder_Element
        MemAbstractMdl_Get_Default_BsConst_SpeedoGauge_Element
        MemAbstractMdl_Get_Default_BsConst_TachoGauge_Element
        MemAbstractMdl_Get_Default_BsConst_TempGauge_Element
        MemAbstractMdl_Get_Default_BsConst_Temp_Threshold_Hysteresis_Derating
        MemAbstractMdl_Get_Default_BsConst_Temp_Threshold_Hysteresis_Derating_SafeCopy1
        MemAbstractMdl_Get_Default_BsConst_Temp_Threshold_Hysteresis_Derating_SafeCopy2
        MemAbstractMdl_Get_Default_BsConst_Temperature_Sensor_Conv
        MemAbstractMdl_Get_Default_BsConst_Temperature_Sensor_Conv_SafeCopy1
        MemAbstractMdl_Get_Default_BsConst_Temperature_Sensor_Conv_SafeCopy2
        MemAbstractMdl_Get_Default_BsConst_TripComputer_Element
        MemAbstractMdl_Get_Default_BsConst_Warning_Element
        MemAbstractMdl_Get_Default_BsCys_Certicificate_Element
        MemAbstractMdl_Get_Default_BsDiag_Dtc_Element
        MemAbstractMdl_Get_Default_BsDiag_ErrorRecord_Element
        MemAbstractMdl_Get_Default_BsReten_Audio_Element
        MemAbstractMdl_Get_Default_BsReten_Communication_Element
        MemAbstractMdl_Get_Default_BsReten_Display_Element
        MemAbstractMdl_Get_Default_BsReten_Gauges_Element
        MemAbstractMdl_Get_Default_BsReten_Illumination_Element
        MemAbstractMdl_Get_Default_BsReten_Odometer_Element
        MemAbstractMdl_Get_Default_BsReten_Personalization_Element
        MemAbstractMdl_Get_Default_BsReten_Power_Element
        MemAbstractMdl_Get_Default_BsReten_RealTimeClock_Element
        MemAbstractMdl_Get_Default_BsReten_Tripcomputer_Element
        MemAbstractMdl_Get_Default_BsReten_Warning_Element
        MemAbstractMdl_Get_Default_BsRt_CusDlt_Element
        MemAbstractMdl_Get_Default_BsRt_FuelGauge_Element
        MemAbstractMdl_Get_Default_BsRt_Illumination_Element
        MemAbstractMdl_Get_Default_BsRt_Odometer_Element
        MemAbstractMdl_Get_Default_BsRt_OilGauge_Element
        MemAbstractMdl_Get_Default_BsRt_Personalization_Element
        MemAbstractMdl_Get_Default_BsRt_PowerGauge_Element
        MemAbstractMdl_Get_Default_BsRt_RealTimeClock_Element
        MemAbstractMdl_Get_Default_BsRt_SpeedoGauge_Element
        MemAbstractMdl_Get_Default_BsRt_TachoGauge_Element
        MemAbstractMdl_Get_Default_BsRt_TempGauge_Element
        MemAbstractMdl_Get_Default_BsRt_TripComputer_Element
        MemAbstractMdl_Get_Default_BsRt_Warning_Element
        MemAbstractMdl_Get_Default_BsShare_AssemblyManufacturingDate
        MemAbstractMdl_Get_Default_BsShare_AssemblyPlantNumber
        MemAbstractMdl_Get_Default_BsShare_EcuPartNumber_Element
        MemAbstractMdl_Get_Default_BsShare_HWModification
        MemAbstractMdl_Get_Default_BsShare_PCBSerialNumber
        MemAbstractMdl_Get_Default_BsShare_ProductSerialNumber
        MemAbstractMdl_Get_Default_BsShare_SMTManufacturingDate
        MemAbstractMdl_Get_Default_BsShare_SMTPlantNumber
        MemAbstractMdl_Get_Default_BsShare_SwUpdFotaFinPrint_Element
        MemAbstractMdl_Get_Default_BsShare_SwUpdFotaMode_Element
        MemAbstractMdl_Get_Default_BsShare_SwUpdFotaStatus_Element
        MemAbstractMdl_Get_Default_BsShare_SwUpdFotadecrypt_Element
        MemAbstractMdl_Get_Default_BsShare_SwUpdReflash_Element
        MemAbstractMdl_Get_Default_BsShare_VehicleConfig_Element
        MemAbstractMdl_Get_Default_BsShare_VisMeet_EOLEntry_Element
        MemAbstractMdl_Get_Default_BsShare_VisMeet_Element
        MemAbstractMdl_Get_Default_BsShare_VisteonPCBPartNumber
        MemAbstractMdl_Get_Default_BsShare_VisteonPartNumber
        MemAbstractMdl_Get_Default_RefCys_Certicificate1_Element
        MemAbstractMdl_Get_Default_RefCys_Certicificate_Element
        MemAbstractMdl_Get_RefCys_Certicificate1_Element
        MemAbstractMdl_Get_RefCys_Certicificate_Element
        MemAbstractMdl_NvmWriteStatus
        MemAbstractMdl_Set_BsConst_Audio_Element
        MemAbstractMdl_Set_BsConst_BsConst_Illumination_ReservedByte
        MemAbstractMdl_Set_BsConst_BsConst_Illumination_ReservedByte_SafeCopy1
        MemAbstractMdl_Set_BsConst_BsConst_Illumination_ReservedByte_SafeCopy2
        MemAbstractMdl_Set_BsConst_Communication_Element
        MemAbstractMdl_Set_BsConst_Compensation_Line_Shift_b
        MemAbstractMdl_Set_BsConst_Compensation_Line_Shift_b_SafeCopy1
        MemAbstractMdl_Set_BsConst_Compensation_Line_Shift_b_SafeCopy2
        MemAbstractMdl_Set_BsConst_Compensation_Line_Slope_m
        MemAbstractMdl_Set_BsConst_Compensation_Line_Slope_m_SafeCopy1
        MemAbstractMdl_Set_BsConst_Compensation_Line_Slope_m_SafeCopy2
        MemAbstractMdl_Set_BsConst_Derating_Backlight_Disable
        MemAbstractMdl_Set_BsConst_Derating_Backlight_Disable_SafeCopy1
        MemAbstractMdl_Set_BsConst_Derating_Backlight_Disable_SafeCopy2
        MemAbstractMdl_Set_BsConst_Display_Illum_Max_Level
        MemAbstractMdl_Set_BsConst_Display_Illum_Max_Level_SafeCopy1
        MemAbstractMdl_Set_BsConst_Display_Illum_Max_Level_SafeCopy2
        MemAbstractMdl_Set_BsConst_EngOffTimer_Element
        MemAbstractMdl_Set_BsConst_FuelGauge_Element
        MemAbstractMdl_Set_BsConst_Lookup_Curve_HotSpot_Coef_X
        MemAbstractMdl_Set_BsConst_Lookup_Curve_HotSpot_Coef_X_SafeCopy1
        MemAbstractMdl_Set_BsConst_Lookup_Curve_HotSpot_Coef_X_SafeCopy2
        MemAbstractMdl_Set_BsConst_Lookup_Curve_HotSpot_Coef_Y
        MemAbstractMdl_Set_BsConst_Lookup_Curve_HotSpot_Coef_Y_SafeCopy1
        MemAbstractMdl_Set_BsConst_Lookup_Curve_HotSpot_Coef_Y_SafeCopy2
        MemAbstractMdl_Set_BsConst_OilGauge_Element
        MemAbstractMdl_Set_BsConst_PCB_Temperature_Sensor_Conv
        MemAbstractMdl_Set_BsConst_PCB_Temperature_Sensor_Conv_SafeCopy1
        MemAbstractMdl_Set_BsConst_PCB_Temperature_Sensor_Conv_SafeCopy2
        MemAbstractMdl_Set_BsConst_PWM_boost_bypass_duty
        MemAbstractMdl_Set_BsConst_PWM_boost_bypass_duty_SafeCopy1
        MemAbstractMdl_Set_BsConst_PWM_boost_bypass_duty_SafeCopy2
        MemAbstractMdl_Set_BsConst_PowerGauge_Element
        MemAbstractMdl_Set_BsConst_Power_Element
        MemAbstractMdl_Set_BsConst_RealTimeClock_Element
        MemAbstractMdl_Set_BsConst_ServiceReminder_Element
        MemAbstractMdl_Set_BsConst_SpeedoGauge_Element
        MemAbstractMdl_Set_BsConst_TachoGauge_Element
        MemAbstractMdl_Set_BsConst_TempGauge_Element
        MemAbstractMdl_Set_BsConst_Temp_Threshold_Hysteresis_Derating
        MemAbstractMdl_Set_BsConst_Temp_Threshold_Hysteresis_Derating_SafeCopy1
        MemAbstractMdl_Set_BsConst_Temp_Threshold_Hysteresis_Derating_SafeCopy2
        MemAbstractMdl_Set_BsConst_Temperature_Sensor_Conv
        MemAbstractMdl_Set_BsConst_Temperature_Sensor_Conv_SafeCopy1
        MemAbstractMdl_Set_BsConst_Temperature_Sensor_Conv_SafeCopy2
        MemAbstractMdl_Set_BsConst_TripComputer_Element
        MemAbstractMdl_Set_BsConst_Warning_Element
        MemAbstractMdl_Set_BsCys_Certicificate_Element
        MemAbstractMdl_Set_BsDiag_Dtc_Element
        MemAbstractMdl_Set_BsDiag_ErrorRecord_Element
        MemAbstractMdl_Set_BsReten_Audio_Element
        MemAbstractMdl_Set_BsReten_Communication_Element
        MemAbstractMdl_Set_BsReten_Display_Element
        MemAbstractMdl_Set_BsReten_Gauges_Element
        MemAbstractMdl_Set_BsReten_Illumination_Element
        MemAbstractMdl_Set_BsReten_Odometer_Element
        MemAbstractMdl_Set_BsReten_Personalization_Element
        MemAbstractMdl_Set_BsReten_Power_Element
        MemAbstractMdl_Set_BsReten_RealTimeClock_Element
        MemAbstractMdl_Set_BsReten_Tripcomputer_Element
        MemAbstractMdl_Set_BsReten_Warning_Element
        MemAbstractMdl_Set_BsRt_CusDlt_Element
        MemAbstractMdl_Set_BsRt_FuelGauge_Element
        MemAbstractMdl_Set_BsRt_Illumination_Element
        MemAbstractMdl_Set_BsRt_Odometer_Element
        MemAbstractMdl_Set_BsRt_OilGauge_Element
        MemAbstractMdl_Set_BsRt_Personalization_Element
        MemAbstractMdl_Set_BsRt_PowerGauge_Element
        MemAbstractMdl_Set_BsRt_RealTimeClock_Element
        MemAbstractMdl_Set_BsRt_SpeedoGauge_Element
        MemAbstractMdl_Set_BsRt_TachoGauge_Element
        MemAbstractMdl_Set_BsRt_TempGauge_Element
        MemAbstractMdl_Set_BsRt_TripComputer_Element
        MemAbstractMdl_Set_BsRt_Warning_Element
        MemAbstractMdl_Set_BsShare_AssemblyManufacturingDate
        MemAbstractMdl_Set_BsShare_AssemblyPlantNumber
        MemAbstractMdl_Set_BsShare_EcuPartNumber_Element
        MemAbstractMdl_Set_BsShare_HWModification
        MemAbstractMdl_Set_BsShare_PCBSerialNumber
        MemAbstractMdl_Set_BsShare_ProductSerialNumber
        MemAbstractMdl_Set_BsShare_SMTManufacturingDate
        MemAbstractMdl_Set_BsShare_SMTPlantNumber
        MemAbstractMdl_Set_BsShare_SwUpdFotaFinPrint_Element
        MemAbstractMdl_Set_BsShare_SwUpdFotaMode_Element
        MemAbstractMdl_Set_BsShare_SwUpdFotaStatus_Element
        MemAbstractMdl_Set_BsShare_SwUpdFotadecrypt_Element
        MemAbstractMdl_Set_BsShare_SwUpdReflash_Element
        MemAbstractMdl_Set_BsShare_VehicleConfig_Element
        MemAbstractMdl_Set_BsShare_VisMeet_EOLEntry_Element
        MemAbstractMdl_Set_BsShare_VisMeet_Element
        MemAbstractMdl_Set_BsShare_VisteonPCBPartNumber
        MemAbstractMdl_Set_BsShare_VisteonPartNumber
        MemAbstractMdl_Set_RefCys_Certicificate1_Element
        MemAbstractMdl_Set_RefCys_Certicificate_Element
  94 x constant specification:
    MemAbstractMdlJobStatus_BsConst_Audio_ElementValue0: value-spec=MemAbstractMdlJobStatus_BsConst_Audio_ElementValue0:0
    MemAbstractMdlJobStatus_BsConst_BsConst_Illumination_ReservedByteValue0: value-spec=MemAbstractMdlJobStatus_BsConst_BsConst_Illumination_ReservedByteValue0:0
    MemAbstractMdlJobStatus_BsConst_BsConst_Illumination_ReservedByte_SafeCopy1Value0: value-spec=MemAbstractMdlJobStatus_BsConst_BsConst_Illumination_ReservedByte_SafeCopy1Value0:0
    MemAbstractMdlJobStatus_BsConst_BsConst_Illumination_ReservedByte_SafeCopy2Value0: value-spec=MemAbstractMdlJobStatus_BsConst_BsConst_Illumination_ReservedByte_SafeCopy2Value0:0
    MemAbstractMdlJobStatus_BsConst_Communication_ElementValue0: value-spec=MemAbstractMdlJobStatus_BsConst_Communication_ElementValue0:0
    MemAbstractMdlJobStatus_BsConst_Compensation_Line_Shift_bValue0: value-spec=MemAbstractMdlJobStatus_BsConst_Compensation_Line_Shift_bValue0:0
    MemAbstractMdlJobStatus_BsConst_Compensation_Line_Shift_b_SafeCopy1Value0: value-spec=MemAbstractMdlJobStatus_BsConst_Compensation_Line_Shift_b_SafeCopy1Value0:0
    MemAbstractMdlJobStatus_BsConst_Compensation_Line_Shift_b_SafeCopy2Value0: value-spec=MemAbstractMdlJobStatus_BsConst_Compensation_Line_Shift_b_SafeCopy2Value0:0
    MemAbstractMdlJobStatus_BsConst_Compensation_Line_Slope_mValue0: value-spec=MemAbstractMdlJobStatus_BsConst_Compensation_Line_Slope_mValue0:0
    MemAbstractMdlJobStatus_BsConst_Compensation_Line_Slope_m_SafeCopy1Value0: value-spec=MemAbstractMdlJobStatus_BsConst_Compensation_Line_Slope_m_SafeCopy1Value0:0
    MemAbstractMdlJobStatus_BsConst_Compensation_Line_Slope_m_SafeCopy2Value0: value-spec=MemAbstractMdlJobStatus_BsConst_Compensation_Line_Slope_m_SafeCopy2Value0:0
    MemAbstractMdlJobStatus_BsConst_Derating_Backlight_DisableValue0: value-spec=MemAbstractMdlJobStatus_BsConst_Derating_Backlight_DisableValue0:0
    MemAbstractMdlJobStatus_BsConst_Derating_Backlight_Disable_SafeCopy1Value0: value-spec=MemAbstractMdlJobStatus_BsConst_Derating_Backlight_Disable_SafeCopy1Value0:0
    MemAbstractMdlJobStatus_BsConst_Derating_Backlight_Disable_SafeCopy2Value0: value-spec=MemAbstractMdlJobStatus_BsConst_Derating_Backlight_Disable_SafeCopy2Value0:0
    MemAbstractMdlJobStatus_BsConst_Display_Illum_Max_LevelValue0: value-spec=MemAbstractMdlJobStatus_BsConst_Display_Illum_Max_LevelValue0:0
    MemAbstractMdlJobStatus_BsConst_Display_Illum_Max_Level_SafeCopy1Value0: value-spec=MemAbstractMdlJobStatus_BsConst_Display_Illum_Max_Level_SafeCopy1Value0:0
    MemAbstractMdlJobStatus_BsConst_Display_Illum_Max_Level_SafeCopy2Value0: value-spec=MemAbstractMdlJobStatus_BsConst_Display_Illum_Max_Level_SafeCopy2Value0:0
    MemAbstractMdlJobStatus_BsConst_EngOffTimer_ElementValue0: value-spec=MemAbstractMdlJobStatus_BsConst_EngOffTimer_ElementValue0:0
    MemAbstractMdlJobStatus_BsConst_FuelGauge_ElementValue0: value-spec=MemAbstractMdlJobStatus_BsConst_FuelGauge_ElementValue0:0
    MemAbstractMdlJobStatus_BsConst_Lookup_Curve_HotSpot_Coef_XValue0: value-spec=MemAbstractMdlJobStatus_BsConst_Lookup_Curve_HotSpot_Coef_XValue0:0
    MemAbstractMdlJobStatus_BsConst_Lookup_Curve_HotSpot_Coef_X_SafeCopy1Value0: value-spec=MemAbstractMdlJobStatus_BsConst_Lookup_Curve_HotSpot_Coef_X_SafeCopy1Value0:0
    MemAbstractMdlJobStatus_BsConst_Lookup_Curve_HotSpot_Coef_X_SafeCopy2Value0: value-spec=MemAbstractMdlJobStatus_BsConst_Lookup_Curve_HotSpot_Coef_X_SafeCopy2Value0:0
    MemAbstractMdlJobStatus_BsConst_Lookup_Curve_HotSpot_Coef_YValue0: value-spec=MemAbstractMdlJobStatus_BsConst_Lookup_Curve_HotSpot_Coef_YValue0:0
    MemAbstractMdlJobStatus_BsConst_Lookup_Curve_HotSpot_Coef_Y_SafeCopy1Value0: value-spec=MemAbstractMdlJobStatus_BsConst_Lookup_Curve_HotSpot_Coef_Y_SafeCopy1Value0:0
    MemAbstractMdlJobStatus_BsConst_Lookup_Curve_HotSpot_Coef_Y_SafeCopy2Value0: value-spec=MemAbstractMdlJobStatus_BsConst_Lookup_Curve_HotSpot_Coef_Y_SafeCopy2Value0:0
    MemAbstractMdlJobStatus_BsConst_OilGauge_ElementValue0: value-spec=MemAbstractMdlJobStatus_BsConst_OilGauge_ElementValue0:0
    MemAbstractMdlJobStatus_BsConst_PCB_Temperature_Sensor_ConvValue0: value-spec=MemAbstractMdlJobStatus_BsConst_PCB_Temperature_Sensor_ConvValue0:0
    MemAbstractMdlJobStatus_BsConst_PCB_Temperature_Sensor_Conv_SafeCopy1Value0: value-spec=MemAbstractMdlJobStatus_BsConst_PCB_Temperature_Sensor_Conv_SafeCopy1Value0:0
    MemAbstractMdlJobStatus_BsConst_PCB_Temperature_Sensor_Conv_SafeCopy2Value0: value-spec=MemAbstractMdlJobStatus_BsConst_PCB_Temperature_Sensor_Conv_SafeCopy2Value0:0
    MemAbstractMdlJobStatus_BsConst_PWM_boost_bypass_dutyValue0: value-spec=MemAbstractMdlJobStatus_BsConst_PWM_boost_bypass_dutyValue0:0
    MemAbstractMdlJobStatus_BsConst_PWM_boost_bypass_duty_SafeCopy1Value0: value-spec=MemAbstractMdlJobStatus_BsConst_PWM_boost_bypass_duty_SafeCopy1Value0:0
    MemAbstractMdlJobStatus_BsConst_PWM_boost_bypass_duty_SafeCopy2Value0: value-spec=MemAbstractMdlJobStatus_BsConst_PWM_boost_bypass_duty_SafeCopy2Value0:0
    MemAbstractMdlJobStatus_BsConst_PowerGauge_ElementValue0: value-spec=MemAbstractMdlJobStatus_BsConst_PowerGauge_ElementValue0:0
    MemAbstractMdlJobStatus_BsConst_Power_ElementValue0: value-spec=MemAbstractMdlJobStatus_BsConst_Power_ElementValue0:0
    MemAbstractMdlJobStatus_BsConst_RealTimeClock_ElementValue0: value-spec=MemAbstractMdlJobStatus_BsConst_RealTimeClock_ElementValue0:0
    MemAbstractMdlJobStatus_BsConst_ServiceReminder_ElementValue0: value-spec=MemAbstractMdlJobStatus_BsConst_ServiceReminder_ElementValue0:0
    MemAbstractMdlJobStatus_BsConst_SpeedoGauge_ElementValue0: value-spec=MemAbstractMdlJobStatus_BsConst_SpeedoGauge_ElementValue0:0
    MemAbstractMdlJobStatus_BsConst_TachoGauge_ElementValue0: value-spec=MemAbstractMdlJobStatus_BsConst_TachoGauge_ElementValue0:0
    MemAbstractMdlJobStatus_BsConst_TempGauge_ElementValue0: value-spec=MemAbstractMdlJobStatus_BsConst_TempGauge_ElementValue0:0
    MemAbstractMdlJobStatus_BsConst_Temp_Threshold_Hysteresis_DeratingValue0: value-spec=MemAbstractMdlJobStatus_BsConst_Temp_Threshold_Hysteresis_DeratingValue0:0
    MemAbstractMdlJobStatus_BsConst_Temp_Threshold_Hysteresis_Derating_SafeCopy1Value0: value-spec=MemAbstractMdlJobStatus_BsConst_Temp_Threshold_Hysteresis_Derating_SafeCopy1Value0:0
    MemAbstractMdlJobStatus_BsConst_Temp_Threshold_Hysteresis_Derating_SafeCopy2Value0: value-spec=MemAbstractMdlJobStatus_BsConst_Temp_Threshold_Hysteresis_Derating_SafeCopy2Value0:0
    MemAbstractMdlJobStatus_BsConst_Temperature_Sensor_ConvValue0: value-spec=MemAbstractMdlJobStatus_BsConst_Temperature_Sensor_ConvValue0:0
    MemAbstractMdlJobStatus_BsConst_Temperature_Sensor_Conv_SafeCopy1Value0: value-spec=MemAbstractMdlJobStatus_BsConst_Temperature_Sensor_Conv_SafeCopy1Value0:0
    MemAbstractMdlJobStatus_BsConst_Temperature_Sensor_Conv_SafeCopy2Value0: value-spec=MemAbstractMdlJobStatus_BsConst_Temperature_Sensor_Conv_SafeCopy2Value0:0
    MemAbstractMdlJobStatus_BsConst_TripComputer_ElementValue0: value-spec=MemAbstractMdlJobStatus_BsConst_TripComputer_ElementValue0:0
    MemAbstractMdlJobStatus_BsConst_Warning_ElementValue0: value-spec=MemAbstractMdlJobStatus_BsConst_Warning_ElementValue0:0
    MemAbstractMdlJobStatus_BsCys_Certicificate_ElementValue0: value-spec=MemAbstractMdlJobStatus_BsCys_Certicificate_ElementValue0:0
    MemAbstractMdlJobStatus_BsDiag_Dtc_ElementValue0: value-spec=MemAbstractMdlJobStatus_BsDiag_Dtc_ElementValue0:0
    MemAbstractMdlJobStatus_BsDiag_ErrorRecord_ElementValue0: value-spec=MemAbstractMdlJobStatus_BsDiag_ErrorRecord_ElementValue0:0
    MemAbstractMdlJobStatus_BsReten_Audio_ElementValue0: value-spec=MemAbstractMdlJobStatus_BsReten_Audio_ElementValue0:0
    MemAbstractMdlJobStatus_BsReten_Communication_ElementValue0: value-spec=MemAbstractMdlJobStatus_BsReten_Communication_ElementValue0:0
    MemAbstractMdlJobStatus_BsReten_Display_ElementValue0: value-spec=MemAbstractMdlJobStatus_BsReten_Display_ElementValue0:0
    MemAbstractMdlJobStatus_BsReten_Gauges_ElementValue0: value-spec=MemAbstractMdlJobStatus_BsReten_Gauges_ElementValue0:0
    MemAbstractMdlJobStatus_BsReten_Illumination_ElementValue0: value-spec=MemAbstractMdlJobStatus_BsReten_Illumination_ElementValue0:0
    MemAbstractMdlJobStatus_BsReten_Odometer_ElementValue0: value-spec=MemAbstractMdlJobStatus_BsReten_Odometer_ElementValue0:0
    MemAbstractMdlJobStatus_BsReten_Personalization_ElementValue0: value-spec=MemAbstractMdlJobStatus_BsReten_Personalization_ElementValue0:0
    MemAbstractMdlJobStatus_BsReten_Power_ElementValue0: value-spec=MemAbstractMdlJobStatus_BsReten_Power_ElementValue0:0
    MemAbstractMdlJobStatus_BsReten_RealTimeClock_ElementValue0: value-spec=MemAbstractMdlJobStatus_BsReten_RealTimeClock_ElementValue0:0
    MemAbstractMdlJobStatus_BsReten_Tripcomputer_ElementValue0: value-spec=MemAbstractMdlJobStatus_BsReten_Tripcomputer_ElementValue0:0
    MemAbstractMdlJobStatus_BsReten_Warning_ElementValue0: value-spec=MemAbstractMdlJobStatus_BsReten_Warning_ElementValue0:0
    MemAbstractMdlJobStatus_BsRt_CusDlt_ElementValue0: value-spec=MemAbstractMdlJobStatus_BsRt_CusDlt_ElementValue0:0
    MemAbstractMdlJobStatus_BsRt_FuelGauge_ElementValue0: value-spec=MemAbstractMdlJobStatus_BsRt_FuelGauge_ElementValue0:0
    MemAbstractMdlJobStatus_BsRt_Illumination_ElementValue0: value-spec=MemAbstractMdlJobStatus_BsRt_Illumination_ElementValue0:0
    MemAbstractMdlJobStatus_BsRt_Odometer_ElementValue0: value-spec=MemAbstractMdlJobStatus_BsRt_Odometer_ElementValue0:0
    MemAbstractMdlJobStatus_BsRt_OilGauge_ElementValue0: value-spec=MemAbstractMdlJobStatus_BsRt_OilGauge_ElementValue0:0
    MemAbstractMdlJobStatus_BsRt_Personalization_ElementValue0: value-spec=MemAbstractMdlJobStatus_BsRt_Personalization_ElementValue0:0
    MemAbstractMdlJobStatus_BsRt_PowerGauge_ElementValue0: value-spec=MemAbstractMdlJobStatus_BsRt_PowerGauge_ElementValue0:0
    MemAbstractMdlJobStatus_BsRt_RealTimeClock_ElementValue0: value-spec=MemAbstractMdlJobStatus_BsRt_RealTimeClock_ElementValue0:0
    MemAbstractMdlJobStatus_BsRt_SpeedoGauge_ElementValue0: value-spec=MemAbstractMdlJobStatus_BsRt_SpeedoGauge_ElementValue0:0
    MemAbstractMdlJobStatus_BsRt_TachoGauge_ElementValue0: value-spec=MemAbstractMdlJobStatus_BsRt_TachoGauge_ElementValue0:0
    MemAbstractMdlJobStatus_BsRt_TempGauge_ElementValue0: value-spec=MemAbstractMdlJobStatus_BsRt_TempGauge_ElementValue0:0
    MemAbstractMdlJobStatus_BsRt_TripComputer_ElementValue0: value-spec=MemAbstractMdlJobStatus_BsRt_TripComputer_ElementValue0:0
    MemAbstractMdlJobStatus_BsRt_Warning_ElementValue0: value-spec=MemAbstractMdlJobStatus_BsRt_Warning_ElementValue0:0
    MemAbstractMdlJobStatus_BsShare_AssemblyManufacturingDateValue0: value-spec=MemAbstractMdlJobStatus_BsShare_AssemblyManufacturingDateValue0:0
    MemAbstractMdlJobStatus_BsShare_AssemblyPlantNumberValue0: value-spec=MemAbstractMdlJobStatus_BsShare_AssemblyPlantNumberValue0:0
    MemAbstractMdlJobStatus_BsShare_EcuPartNumber_ElementValue0: value-spec=MemAbstractMdlJobStatus_BsShare_EcuPartNumber_ElementValue0:0
    MemAbstractMdlJobStatus_BsShare_HWModificationValue0: value-spec=MemAbstractMdlJobStatus_BsShare_HWModificationValue0:0
    MemAbstractMdlJobStatus_BsShare_PCBSerialNumberValue0: value-spec=MemAbstractMdlJobStatus_BsShare_PCBSerialNumberValue0:0
    MemAbstractMdlJobStatus_BsShare_ProductSerialNumberValue0: value-spec=MemAbstractMdlJobStatus_BsShare_ProductSerialNumberValue0:0
    MemAbstractMdlJobStatus_BsShare_SMTManufacturingDateValue0: value-spec=MemAbstractMdlJobStatus_BsShare_SMTManufacturingDateValue0:0
    MemAbstractMdlJobStatus_BsShare_SMTPlantNumberValue0: value-spec=MemAbstractMdlJobStatus_BsShare_SMTPlantNumberValue0:0
    MemAbstractMdlJobStatus_BsShare_SwUpdFotaFinPrint_ElementValue0: value-spec=MemAbstractMdlJobStatus_BsShare_SwUpdFotaFinPrint_ElementValue0:0
    MemAbstractMdlJobStatus_BsShare_SwUpdFotaMode_ElementValue0: value-spec=MemAbstractMdlJobStatus_BsShare_SwUpdFotaMode_ElementValue0:0
    MemAbstractMdlJobStatus_BsShare_SwUpdFotaStatus_ElementValue0: value-spec=MemAbstractMdlJobStatus_BsShare_SwUpdFotaStatus_ElementValue0:0
    MemAbstractMdlJobStatus_BsShare_SwUpdFotadecrypt_ElementValue0: value-spec=MemAbstractMdlJobStatus_BsShare_SwUpdFotadecrypt_ElementValue0:0
    MemAbstractMdlJobStatus_BsShare_SwUpdReflash_ElementValue0: value-spec=MemAbstractMdlJobStatus_BsShare_SwUpdReflash_ElementValue0:0
    MemAbstractMdlJobStatus_BsShare_VehicleConfig_ElementValue0: value-spec=MemAbstractMdlJobStatus_BsShare_VehicleConfig_ElementValue0:0
    MemAbstractMdlJobStatus_BsShare_VisMeet_EOLEntry_ElementValue0: value-spec=MemAbstractMdlJobStatus_BsShare_VisMeet_EOLEntry_ElementValue0:0
    MemAbstractMdlJobStatus_BsShare_VisMeet_ElementValue0: value-spec=MemAbstractMdlJobStatus_BsShare_VisMeet_ElementValue0:0
    MemAbstractMdlJobStatus_BsShare_VisteonPCBPartNumberValue0: value-spec=MemAbstractMdlJobStatus_BsShare_VisteonPCBPartNumberValue0:0
    MemAbstractMdlJobStatus_BsShare_VisteonPartNumberValue0: value-spec=MemAbstractMdlJobStatus_BsShare_VisteonPartNumberValue0:0
    MemAbstractMdlJobStatus_RefCys_Certicificate1_ElementValue0: value-spec=MemAbstractMdlJobStatus_RefCys_Certicificate1_ElementValue0:0
    MemAbstractMdlJobStatus_RefCys_Certicificate_ElementValue0: value-spec=MemAbstractMdlJobStatus_RefCys_Certicificate_ElementValue0:0
  swc implementation IMPL_MemAbstractMdl: programming-language=C, behavior=IB_MemAbstractMdl
    code-descriptors:
      code CodeDescriptor
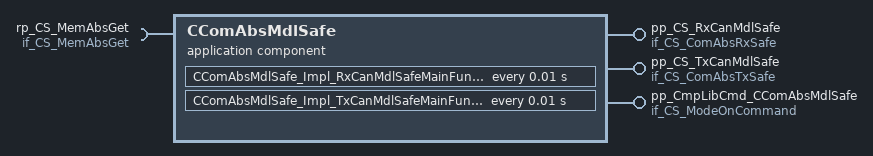
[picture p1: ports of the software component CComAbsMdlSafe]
  application sw component type CComAbsMdlSafe
    provide port pp_CS_RxCanMdlSafe: provided-interface=if_CS_ComAbsRxSafe
      provided-com-specs:
        operation=if_CS_ComAbsRxSafe/RxCan_GetSignalValue, queue-length=1
        operation=if_CS_ComAbsRxSafe/RxCan_GetSignalValueU8Arr, queue-length=1
        operation=if_CS_ComAbsRxSafe/RxCan_SetSignalInitValue, queue-length=1
        operation=if_CS_ComAbsRxSafe/RxCan_SetSignalInitValueU8Arr, queue-length=1
        operation=if_CS_ComAbsRxSafe/RxCan_SignalClearJustRcvdStatus, queue-length=1
        operation=if_CS_ComAbsRxSafe/RxCan_SignalGetJustRcvdStatus, queue-length=1
        operation=if_CS_ComAbsRxSafe/RxCan_SignalInvalidProcessingControl, queue-length=1
        operation=if_CS_ComAbsRxSafe/RxCan_SignalMissingProcessingControl, queue-length=1
        operation=if_CS_ComAbsRxSafe/RxCan_SignalNRProcessingControl, queue-length=1
    provide port pp_CS_TxCanMdlSafe: provided-interface=if_CS_ComAbsTxSafe
      provided-com-specs:
        operation=if_CS_ComAbsTxSafe/TxCan_ClearCanSignalTxConfirmation, queue-length=1
        operation=if_CS_ComAbsTxSafe/TxCan_GetCanSignalTxConfirmation, queue-length=1
        operation=if_CS_ComAbsTxSafe/TxCan_SetSignalFromRetentionBuffer, queue-length=1
        operation=if_CS_ComAbsTxSafe/TxCan_SetSignalValue, queue-length=1
        operation=if_CS_ComAbsTxSafe/TxCan_SetSignalValueU8Arr, queue-length=1
    provide port pp_CmpLibCmd_CComAbsMdlSafe: server-com-spec{operation=Impl_OnCommand, queue-length=1}, provided-interface=if_CS_ModeOnCommand
    require port rp_CS_MemAbsGet: required-interface=if_CS_MemAbsGet
    behavior IB_CComAbsMdlSafe
      operation invoked event OIE_pp_CmpLibCmd_CComAbsMdlSafe_CComAbsMdlSafe_Impl_OnCommandTrigByImpl_OnCommand: start-on-event=CComAbsMdlSafe_Impl_OnCommand, operation=pp_CmpLibCmd_CComAbsMdlSafe.Impl_OnCommand
      timing event TECComAbsMdlSafe_Impl_RxCanMdlSafeMainFunction: start-on-event=CComAbsMdlSafe_Impl_RxCanMdlSafeMainFunction, period=0.01
      timing event TECComAbsMdlSafe_Impl_TxCanMdlSafeMainFunction: start-on-event=CComAbsMdlSafe_Impl_TxCanMdlSafeMainFunction, period=0.01
      14 x operation invoked event:
        OIE_pp_CS_RxCanMdlSafe_CComAbsMdlSafe_RxCan_GetSignalValueTrigByRxCan_GetSignalValue: start-on-event=CComAbsMdlSafe_RxCan_GetSignalValue, operation=pp_CS_RxCanMdlSafe.RxCan_GetSignalValue
        OIE_pp_CS_RxCanMdlSafe_CComAbsMdlSafe_RxCan_GetSignalValueU8ArrTrigByRxCan_GetSignalValueU8Arr: start-on-event=CComAbsMdlSafe_RxCan_GetSignalValueU8Arr, operation=pp_CS_RxCanMdlSafe.RxCan_GetSignalValueU8Arr
        OIE_pp_CS_RxCanMdlSafe_CComAbsMdlSafe_RxCan_SetSignalInitValueTrigByRxCan_SetSignalInitValue: start-on-event=CComAbsMdlSafe_RxCan_SetSignalInitValue, operation=pp_CS_RxCanMdlSafe.RxCan_SetSignalInitValue
        OIE_pp_CS_RxCanMdlSafe_CComAbsMdlSafe_RxCan_SetSignalInitValueU8ArrTrigByRxCan_SetSignalInitValueU8Arr: start-on-event=CComAbsMdlSafe_RxCan_SetSignalInitValueU8Arr, operation=pp_CS_RxCanMdlSafe.RxCan_SetSignalInitValueU8Arr
        OIE_pp_CS_RxCanMdlSafe_CComAbsMdlSafe_RxCan_SignalClearJustRcvdStatusTrigByRxCan_SignalClearJustRcvdStatus: start-on-event=CComAbsMdlSafe_RxCan_SignalClearJustRcvdStatus, operation=pp_CS_RxCanMdlSafe.RxCan_SignalClearJustRcvdStatus
        OIE_pp_CS_RxCanMdlSafe_CComAbsMdlSafe_RxCan_SignalGetJustRcvdStatusTrigByRxCan_SignalGetJustRcvdStatus: start-on-event=CComAbsMdlSafe_RxCan_SignalGetJustRcvdStatus, operation=pp_CS_RxCanMdlSafe.RxCan_SignalGetJustRcvdStatus
        OIE_pp_CS_RxCanMdlSafe_CComAbsMdlSafe_RxCan_SignalInvalidProcessingControlTrigByRxCan_SignalInvalidProcessingControl: start-on-event=CComAbsMdlSafe_RxCan_SignalInvalidProcessingControl, operation=pp_CS_RxCanMdlSafe.RxCan_SignalInvalidProcessingControl
        OIE_pp_CS_RxCanMdlSafe_CComAbsMdlSafe_RxCan_SignalMissingProcessingControlTrigByRxCan_SignalMissingProcessingControl: start-on-event=CComAbsMdlSafe_RxCan_SignalMissingProcessingControl, operation=pp_CS_RxCanMdlSafe.RxCan_SignalMissingProcessingControl
        OIE_pp_CS_RxCanMdlSafe_CComAbsMdlSafe_RxCan_SignalNRProcessingControlTrigByRxCan_SignalNRProcessingControl: start-on-event=CComAbsMdlSafe_RxCan_SignalNRProcessingControl, operation=pp_CS_RxCanMdlSafe.RxCan_SignalNRProcessingControl
        OIE_pp_CS_TxCanMdlSafe_CComAbsMdlSafe_TxCan_ClearCanSignalTxConfirmationTrigByTxCan_ClearCanSignalTxConfirmation: start-on-event=CComAbsMdlSafe_TxCan_ClearCanSignalTxConfirmation, operation=pp_CS_TxCanMdlSafe.TxCan_ClearCanSignalTxConfirmation
        OIE_pp_CS_TxCanMdlSafe_CComAbsMdlSafe_TxCan_GetCanSignalTxConfirmationTrigByTxCan_GetCanSignalTxConfirmation: start-on-event=CComAbsMdlSafe_TxCan_GetCanSignalTxConfirmation, operation=pp_CS_TxCanMdlSafe.TxCan_GetCanSignalTxConfirmation
        OIE_pp_CS_TxCanMdlSafe_CComAbsMdlSafe_TxCan_SetSignalFromRetentionBufferTrigByTxCan_SetSignalFromRetentionBuffer: start-on-event=CComAbsMdlSafe_TxCan_SetSignalFromRetentionBuffer, operation=pp_CS_TxCanMdlSafe.TxCan_SetSignalFromRetentionBuffer
        OIE_pp_CS_TxCanMdlSafe_CComAbsMdlSafe_TxCan_SetSignalValueTrigByTxCan_SetSignalValue: start-on-event=CComAbsMdlSafe_TxCan_SetSignalValue, operation=pp_CS_TxCanMdlSafe.TxCan_SetSignalValue
        OIE_pp_CS_TxCanMdlSafe_CComAbsMdlSafe_TxCan_SetSignalValueU8ArrTrigByTxCan_SetSignalValueU8Arr: start-on-event=CComAbsMdlSafe_TxCan_SetSignalValueU8Arr, operation=pp_CS_TxCanMdlSafe.TxCan_SetSignalValueU8Arr
      port-api-options:
        enable-take-address=false, indirect-api=false, port=pp_CS_RxCanMdlSafe
        enable-take-address=false, indirect-api=false, port=pp_CS_TxCanMdlSafe
        enable-take-address=false, indirect-api=false, port=pp_CmpLibCmd_CComAbsMdlSafe
        enable-take-address=false, indirect-api=false, port=CComAbsMdlSafe/rp_CS_MemAbsGet
      17 x runnable, all with can-be-invoked-concurrently=true:
        CComAbsMdlSafe_Impl_OnCommand
          94 x sync call, all with timeout=0.0:
            OA_rp_CS_MemAbsGet_Get_BsShare_SwUpdReflash_Element: operation=rp_CS_MemAbsGet.Get_BsShare_SwUpdReflash_Element
            OA_rp_CS_MemAbsGet_Get_BsShare_SwUpdFotaMode_Element: operation=rp_CS_MemAbsGet.Get_BsShare_SwUpdFotaMode_Element
            OA_rp_CS_MemAbsGet_Get_BsShare_SwUpdFotaFinPrint_Element: operation=rp_CS_MemAbsGet.Get_BsShare_SwUpdFotaFinPrint_Element
            OA_rp_CS_MemAbsGet_Get_BsShare_SwUpdFotaStatus_Element: operation=rp_CS_MemAbsGet.Get_BsShare_SwUpdFotaStatus_Element
            OA_rp_CS_MemAbsGet_Get_BsShare_SwUpdFotadecrypt_Element: operation=rp_CS_MemAbsGet.Get_BsShare_SwUpdFotadecrypt_Element
            OA_rp_CS_MemAbsGet_Get_BsShare_EcuPartNumber_Element: operation=rp_CS_MemAbsGet.Get_BsShare_EcuPartNumber_Element
            OA_rp_CS_MemAbsGet_Get_BsShare_VisteonPartNumber: operation=rp_CS_MemAbsGet.Get_BsShare_VisteonPartNumber
            OA_rp_CS_MemAbsGet_Get_BsShare_VisteonPCBPartNumber: operation=rp_CS_MemAbsGet.Get_BsShare_VisteonPCBPartNumber
            OA_rp_CS_MemAbsGet_Get_BsShare_ProductSerialNumber: operation=rp_CS_MemAbsGet.Get_BsShare_ProductSerialNumber
            OA_rp_CS_MemAbsGet_Get_BsShare_PCBSerialNumber: operation=rp_CS_MemAbsGet.Get_BsShare_PCBSerialNumber
            OA_rp_CS_MemAbsGet_Get_BsShare_SMTManufacturingDate: operation=rp_CS_MemAbsGet.Get_BsShare_SMTManufacturingDate
            OA_rp_CS_MemAbsGet_Get_BsShare_AssemblyManufacturingDate: operation=rp_CS_MemAbsGet.Get_BsShare_AssemblyManufacturingDate
            OA_rp_CS_MemAbsGet_Get_BsShare_SMTPlantNumber: operation=rp_CS_MemAbsGet.Get_BsShare_SMTPlantNumber
            OA_rp_CS_MemAbsGet_Get_BsShare_AssemblyPlantNumber: operation=rp_CS_MemAbsGet.Get_BsShare_AssemblyPlantNumber
            OA_rp_CS_MemAbsGet_Get_BsShare_HWModification: operation=rp_CS_MemAbsGet.Get_BsShare_HWModification
            OA_rp_CS_MemAbsGet_Get_BsShare_VisMeet_Element: operation=rp_CS_MemAbsGet.Get_BsShare_VisMeet_Element
            OA_rp_CS_MemAbsGet_Get_BsShare_VisMeet_EOLEntry_Element: operation=rp_CS_MemAbsGet.Get_BsShare_VisMeet_EOLEntry_Element
            OA_rp_CS_MemAbsGet_Get_BsShare_VehicleConfig_Element: operation=rp_CS_MemAbsGet.Get_BsShare_VehicleConfig_Element
            OA_rp_CS_MemAbsGet_Get_BsConst_SpeedoGauge_Element: operation=rp_CS_MemAbsGet.Get_BsConst_SpeedoGauge_Element
            OA_rp_CS_MemAbsGet_Get_BsConst_TachoGauge_Element: operation=rp_CS_MemAbsGet.Get_BsConst_TachoGauge_Element
            OA_rp_CS_MemAbsGet_Get_BsConst_FuelGauge_Element: operation=rp_CS_MemAbsGet.Get_BsConst_FuelGauge_Element
            OA_rp_CS_MemAbsGet_Get_BsConst_TempGauge_Element: operation=rp_CS_MemAbsGet.Get_BsConst_TempGauge_Element
            OA_rp_CS_MemAbsGet_Get_BsConst_PowerGauge_Element: operation=rp_CS_MemAbsGet.Get_BsConst_PowerGauge_Element
            OA_rp_CS_MemAbsGet_Get_BsConst_OilGauge_Element: operation=rp_CS_MemAbsGet.Get_BsConst_OilGauge_Element
            OA_rp_CS_MemAbsGet_Get_BsConst_TripComputer_Element: operation=rp_CS_MemAbsGet.Get_BsConst_TripComputer_Element
            OA_rp_CS_MemAbsGet_Get_BsConst_Compensation_Line_Slope_m: operation=rp_CS_MemAbsGet.Get_BsConst_Compensation_Line_Slope_m
            OA_rp_CS_MemAbsGet_Get_BsConst_Compensation_Line_Shift_b: operation=rp_CS_MemAbsGet.Get_BsConst_Compensation_Line_Shift_b
            OA_rp_CS_MemAbsGet_Get_BsConst_Lookup_Curve_HotSpot_Coef_X: operation=rp_CS_MemAbsGet.Get_BsConst_Lookup_Curve_HotSpot_Coef_X
            OA_rp_CS_MemAbsGet_Get_BsConst_Lookup_Curve_HotSpot_Coef_Y: operation=rp_CS_MemAbsGet.Get_BsConst_Lookup_Curve_HotSpot_Coef_Y
            OA_rp_CS_MemAbsGet_Get_BsConst_Temp_Threshold_Hysteresis_Derating: operation=rp_CS_MemAbsGet.Get_BsConst_Temp_Threshold_Hysteresis_Derating
            OA_rp_CS_MemAbsGet_Get_BsConst_Derating_Backlight_Disable: operation=rp_CS_MemAbsGet.Get_BsConst_Derating_Backlight_Disable
            OA_rp_CS_MemAbsGet_Get_BsConst_Temperature_Sensor_Conv: operation=rp_CS_MemAbsGet.Get_BsConst_Temperature_Sensor_Conv
            OA_rp_CS_MemAbsGet_Get_BsConst_PCB_Temperature_Sensor_Conv: operation=rp_CS_MemAbsGet.Get_BsConst_PCB_Temperature_Sensor_Conv
            OA_rp_CS_MemAbsGet_Get_BsConst_Display_Illum_Max_Level: operation=rp_CS_MemAbsGet.Get_BsConst_Display_Illum_Max_Level
            OA_rp_CS_MemAbsGet_Get_BsConst_PWM_boost_bypass_duty: operation=rp_CS_MemAbsGet.Get_BsConst_PWM_boost_bypass_duty
            OA_rp_CS_MemAbsGet_Get_BsConst_BsConst_Illumination_ReservedByte: operation=rp_CS_MemAbsGet.Get_BsConst_BsConst_Illumination_ReservedByte
            OA_rp_CS_MemAbsGet_Get_BsConst_Compensation_Line_Slope_m_SafeCopy1: operation=rp_CS_MemAbsGet.Get_BsConst_Compensation_Line_Slope_m_SafeCopy1
            OA_rp_CS_MemAbsGet_Get_BsConst_Compensation_Line_Shift_b_SafeCopy1: operation=rp_CS_MemAbsGet.Get_BsConst_Compensation_Line_Shift_b_SafeCopy1
            OA_rp_CS_MemAbsGet_Get_BsConst_Lookup_Curve_HotSpot_Coef_X_SafeCopy1: operation=rp_CS_MemAbsGet.Get_BsConst_Lookup_Curve_HotSpot_Coef_X_SafeCopy1
            OA_rp_CS_MemAbsGet_Get_BsConst_Lookup_Curve_HotSpot_Coef_Y_SafeCopy1: operation=rp_CS_MemAbsGet.Get_BsConst_Lookup_Curve_HotSpot_Coef_Y_SafeCopy1
            OA_rp_CS_MemAbsGet_Get_BsConst_Temp_Threshold_Hysteresis_Derating_SafeCopy1: operation=rp_CS_MemAbsGet.Get_BsConst_Temp_Threshold_Hysteresis_Derating_SafeCopy1
            OA_rp_CS_MemAbsGet_Get_BsConst_Derating_Backlight_Disable_SafeCopy1: operation=rp_CS_MemAbsGet.Get_BsConst_Derating_Backlight_Disable_SafeCopy1
            OA_rp_CS_MemAbsGet_Get_BsConst_Temperature_Sensor_Conv_SafeCopy1: operation=rp_CS_MemAbsGet.Get_BsConst_Temperature_Sensor_Conv_SafeCopy1
            OA_rp_CS_MemAbsGet_Get_BsConst_PCB_Temperature_Sensor_Conv_SafeCopy1: operation=rp_CS_MemAbsGet.Get_BsConst_PCB_Temperature_Sensor_Conv_SafeCopy1
            OA_rp_CS_MemAbsGet_Get_BsConst_Display_Illum_Max_Level_SafeCopy1: operation=rp_CS_MemAbsGet.Get_BsConst_Display_Illum_Max_Level_SafeCopy1
            OA_rp_CS_MemAbsGet_Get_BsConst_PWM_boost_bypass_duty_SafeCopy1: operation=rp_CS_MemAbsGet.Get_BsConst_PWM_boost_bypass_duty_SafeCopy1
            OA_rp_CS_MemAbsGet_Get_BsConst_BsConst_Illumination_ReservedByte_SafeCopy1: operation=rp_CS_MemAbsGet.Get_BsConst_BsConst_Illumination_ReservedByte_SafeCopy1
            OA_rp_CS_MemAbsGet_Get_BsConst_Compensation_Line_Slope_m_SafeCopy2: operation=rp_CS_MemAbsGet.Get_BsConst_Compensation_Line_Slope_m_SafeCopy2
            OA_rp_CS_MemAbsGet_Get_BsConst_Compensation_Line_Shift_b_SafeCopy2: operation=rp_CS_MemAbsGet.Get_BsConst_Compensation_Line_Shift_b_SafeCopy2
            OA_rp_CS_MemAbsGet_Get_BsConst_Lookup_Curve_HotSpot_Coef_X_SafeCopy2: operation=rp_CS_MemAbsGet.Get_BsConst_Lookup_Curve_HotSpot_Coef_X_SafeCopy2
            OA_rp_CS_MemAbsGet_Get_BsConst_Lookup_Curve_HotSpot_Coef_Y_SafeCopy2: operation=rp_CS_MemAbsGet.Get_BsConst_Lookup_Curve_HotSpot_Coef_Y_SafeCopy2
            OA_rp_CS_MemAbsGet_Get_BsConst_Temp_Threshold_Hysteresis_Derating_SafeCopy2: operation=rp_CS_MemAbsGet.Get_BsConst_Temp_Threshold_Hysteresis_Derating_SafeCopy2
            OA_rp_CS_MemAbsGet_Get_BsConst_Derating_Backlight_Disable_SafeCopy2: operation=rp_CS_MemAbsGet.Get_BsConst_Derating_Backlight_Disable_SafeCopy2
            OA_rp_CS_MemAbsGet_Get_BsConst_Temperature_Sensor_Conv_SafeCopy2: operation=rp_CS_MemAbsGet.Get_BsConst_Temperature_Sensor_Conv_SafeCopy2
            OA_rp_CS_MemAbsGet_Get_BsConst_PCB_Temperature_Sensor_Conv_SafeCopy2: operation=rp_CS_MemAbsGet.Get_BsConst_PCB_Temperature_Sensor_Conv_SafeCopy2
            OA_rp_CS_MemAbsGet_Get_BsConst_Display_Illum_Max_Level_SafeCopy2: operation=rp_CS_MemAbsGet.Get_BsConst_Display_Illum_Max_Level_SafeCopy2
            OA_rp_CS_MemAbsGet_Get_BsConst_PWM_boost_bypass_duty_SafeCopy2: operation=rp_CS_MemAbsGet.Get_BsConst_PWM_boost_bypass_duty_SafeCopy2
            OA_rp_CS_MemAbsGet_Get_BsConst_BsConst_Illumination_ReservedByte_SafeCopy2: operation=rp_CS_MemAbsGet.Get_BsConst_BsConst_Illumination_ReservedByte_SafeCopy2
            OA_rp_CS_MemAbsGet_Get_BsConst_Audio_Element: operation=rp_CS_MemAbsGet.Get_BsConst_Audio_Element
            OA_rp_CS_MemAbsGet_Get_BsConst_Warning_Element: operation=rp_CS_MemAbsGet.Get_BsConst_Warning_Element
            OA_rp_CS_MemAbsGet_Get_BsConst_RealTimeClock_Element: operation=rp_CS_MemAbsGet.Get_BsConst_RealTimeClock_Element
            OA_rp_CS_MemAbsGet_Get_BsConst_Communication_Element: operation=rp_CS_MemAbsGet.Get_BsConst_Communication_Element
            OA_rp_CS_MemAbsGet_Get_BsConst_Power_Element: operation=rp_CS_MemAbsGet.Get_BsConst_Power_Element
            OA_rp_CS_MemAbsGet_Get_BsConst_ServiceReminder_Element: operation=rp_CS_MemAbsGet.Get_BsConst_ServiceReminder_Element
            OA_rp_CS_MemAbsGet_Get_BsConst_EngOffTimer_Element: operation=rp_CS_MemAbsGet.Get_BsConst_EngOffTimer_Element
            OA_rp_CS_MemAbsGet_Get_BsCys_Certicificate_Element: operation=rp_CS_MemAbsGet.Get_BsCys_Certicificate_Element
            OA_rp_CS_MemAbsGet_Get_RefCys_Certicificate_Element: operation=rp_CS_MemAbsGet.Get_RefCys_Certicificate_Element
            OA_rp_CS_MemAbsGet_Get_RefCys_Certicificate1_Element: operation=rp_CS_MemAbsGet.Get_RefCys_Certicificate1_Element
            OA_rp_CS_MemAbsGet_Get_BsRt_Odometer_Element: operation=rp_CS_MemAbsGet.Get_BsRt_Odometer_Element
            OA_rp_CS_MemAbsGet_Get_BsRt_SpeedoGauge_Element: operation=rp_CS_MemAbsGet.Get_BsRt_SpeedoGauge_Element
            OA_rp_CS_MemAbsGet_Get_BsRt_TachoGauge_Element: operation=rp_CS_MemAbsGet.Get_BsRt_TachoGauge_Element
            OA_rp_CS_MemAbsGet_Get_BsRt_FuelGauge_Element: operation=rp_CS_MemAbsGet.Get_BsRt_FuelGauge_Element
            OA_rp_CS_MemAbsGet_Get_BsRt_TempGauge_Element: operation=rp_CS_MemAbsGet.Get_BsRt_TempGauge_Element
            OA_rp_CS_MemAbsGet_Get_BsRt_PowerGauge_Element: operation=rp_CS_MemAbsGet.Get_BsRt_PowerGauge_Element
            OA_rp_CS_MemAbsGet_Get_BsRt_OilGauge_Element: operation=rp_CS_MemAbsGet.Get_BsRt_OilGauge_Element
            OA_rp_CS_MemAbsGet_Get_BsRt_TripComputer_Element: operation=rp_CS_MemAbsGet.Get_BsRt_TripComputer_Element
            OA_rp_CS_MemAbsGet_Get_BsRt_Warning_Element: operation=rp_CS_MemAbsGet.Get_BsRt_Warning_Element
            OA_rp_CS_MemAbsGet_Get_BsRt_RealTimeClock_Element: operation=rp_CS_MemAbsGet.Get_BsRt_RealTimeClock_Element
            OA_rp_CS_MemAbsGet_Get_BsRt_Personalization_Element: operation=rp_CS_MemAbsGet.Get_BsRt_Personalization_Element
            OA_rp_CS_MemAbsGet_Get_BsRt_Illumination_Element: operation=rp_CS_MemAbsGet.Get_BsRt_Illumination_Element
            OA_rp_CS_MemAbsGet_Get_BsRt_CusDlt_Element: operation=rp_CS_MemAbsGet.Get_BsRt_CusDlt_Element
            OA_rp_CS_MemAbsGet_Get_BsReten_Odometer_Element: operation=rp_CS_MemAbsGet.Get_BsReten_Odometer_Element
            OA_rp_CS_MemAbsGet_Get_BsReten_Gauges_Element: operation=rp_CS_MemAbsGet.Get_BsReten_Gauges_Element
            OA_rp_CS_MemAbsGet_Get_BsReten_Tripcomputer_Element: operation=rp_CS_MemAbsGet.Get_BsReten_Tripcomputer_Element
            OA_rp_CS_MemAbsGet_Get_BsReten_Illumination_Element: operation=rp_CS_MemAbsGet.Get_BsReten_Illumination_Element
            OA_rp_CS_MemAbsGet_Get_BsReten_Audio_Element: operation=rp_CS_MemAbsGet.Get_BsReten_Audio_Element
            OA_rp_CS_MemAbsGet_Get_BsReten_Warning_Element: operation=rp_CS_MemAbsGet.Get_BsReten_Warning_Element
            OA_rp_CS_MemAbsGet_Get_BsReten_RealTimeClock_Element: operation=rp_CS_MemAbsGet.Get_BsReten_RealTimeClock_Element
            OA_rp_CS_MemAbsGet_Get_BsReten_Communication_Element: operation=rp_CS_MemAbsGet.Get_BsReten_Communication_Element
            OA_rp_CS_MemAbsGet_Get_BsReten_Personalization_Element: operation=rp_CS_MemAbsGet.Get_BsReten_Personalization_Element
            OA_rp_CS_MemAbsGet_Get_BsReten_Power_Element: operation=rp_CS_MemAbsGet.Get_BsReten_Power_Element
            OA_rp_CS_MemAbsGet_Get_BsReten_Display_Element: operation=rp_CS_MemAbsGet.Get_BsReten_Display_Element
            OA_rp_CS_MemAbsGet_Get_BsDiag_ErrorRecord_Element: operation=rp_CS_MemAbsGet.Get_BsDiag_ErrorRecord_Element
            OA_rp_CS_MemAbsGet_Get_BsDiag_Dtc_Element: operation=rp_CS_MemAbsGet.Get_BsDiag_Dtc_Element
        CComAbsMdlSafe_Impl_RxCanMdlSafeMainFunction
          94 x sync call, all with timeout=0.0:
            OA_rp_CS_MemAbsGet_Get_BsShare_SwUpdReflash_Element: operation=rp_CS_MemAbsGet.Get_BsShare_SwUpdReflash_Element
            OA_rp_CS_MemAbsGet_Get_BsShare_SwUpdFotaMode_Element: operation=rp_CS_MemAbsGet.Get_BsShare_SwUpdFotaMode_Element
            OA_rp_CS_MemAbsGet_Get_BsShare_SwUpdFotaFinPrint_Element: operation=rp_CS_MemAbsGet.Get_BsShare_SwUpdFotaFinPrint_Element
            OA_rp_CS_MemAbsGet_Get_BsShare_SwUpdFotaStatus_Element: operation=rp_CS_MemAbsGet.Get_BsShare_SwUpdFotaStatus_Element
            OA_rp_CS_MemAbsGet_Get_BsShare_SwUpdFotadecrypt_Element: operation=rp_CS_MemAbsGet.Get_BsShare_SwUpdFotadecrypt_Element
            OA_rp_CS_MemAbsGet_Get_BsShare_EcuPartNumber_Element: operation=rp_CS_MemAbsGet.Get_BsShare_EcuPartNumber_Element
            OA_rp_CS_MemAbsGet_Get_BsShare_VisteonPartNumber: operation=rp_CS_MemAbsGet.Get_BsShare_VisteonPartNumber
            OA_rp_CS_MemAbsGet_Get_BsShare_VisteonPCBPartNumber: operation=rp_CS_MemAbsGet.Get_BsShare_VisteonPCBPartNumber
            OA_rp_CS_MemAbsGet_Get_BsShare_ProductSerialNumber: operation=rp_CS_MemAbsGet.Get_BsShare_ProductSerialNumber
            OA_rp_CS_MemAbsGet_Get_BsShare_PCBSerialNumber: operation=rp_CS_MemAbsGet.Get_BsShare_PCBSerialNumber
            OA_rp_CS_MemAbsGet_Get_BsShare_SMTManufacturingDate: operation=rp_CS_MemAbsGet.Get_BsShare_SMTManufacturingDate
            OA_rp_CS_MemAbsGet_Get_BsShare_AssemblyManufacturingDate: operation=rp_CS_MemAbsGet.Get_BsShare_AssemblyManufacturingDate
            OA_rp_CS_MemAbsGet_Get_BsShare_SMTPlantNumber: operation=rp_CS_MemAbsGet.Get_BsShare_SMTPlantNumber
            OA_rp_CS_MemAbsGet_Get_BsShare_AssemblyPlantNumber: operation=rp_CS_MemAbsGet.Get_BsShare_AssemblyPlantNumber
            OA_rp_CS_MemAbsGet_Get_BsShare_HWModification: operation=rp_CS_MemAbsGet.Get_BsShare_HWModification
            OA_rp_CS_MemAbsGet_Get_BsShare_VisMeet_Element: operation=rp_CS_MemAbsGet.Get_BsShare_VisMeet_Element
            OA_rp_CS_MemAbsGet_Get_BsShare_VisMeet_EOLEntry_Element: operation=rp_CS_MemAbsGet.Get_BsShare_VisMeet_EOLEntry_Element
            OA_rp_CS_MemAbsGet_Get_BsShare_VehicleConfig_Element: operation=rp_CS_MemAbsGet.Get_BsShare_VehicleConfig_Element
            OA_rp_CS_MemAbsGet_Get_BsConst_SpeedoGauge_Element: operation=rp_CS_MemAbsGet.Get_BsConst_SpeedoGauge_Element
            OA_rp_CS_MemAbsGet_Get_BsConst_TachoGauge_Element: operation=rp_CS_MemAbsGet.Get_BsConst_TachoGauge_Element
            OA_rp_CS_MemAbsGet_Get_BsConst_FuelGauge_Element: operation=rp_CS_MemAbsGet.Get_BsConst_FuelGauge_Element
            OA_rp_CS_MemAbsGet_Get_BsConst_TempGauge_Element: operation=rp_CS_MemAbsGet.Get_BsConst_TempGauge_Element
            OA_rp_CS_MemAbsGet_Get_BsConst_PowerGauge_Element: operation=rp_CS_MemAbsGet.Get_BsConst_PowerGauge_Element
            OA_rp_CS_MemAbsGet_Get_BsConst_OilGauge_Element: operation=rp_CS_MemAbsGet.Get_BsConst_OilGauge_Element
            OA_rp_CS_MemAbsGet_Get_BsConst_TripComputer_Element: operation=rp_CS_MemAbsGet.Get_BsConst_TripComputer_Element
            OA_rp_CS_MemAbsGet_Get_BsConst_Compensation_Line_Slope_m: operation=rp_CS_MemAbsGet.Get_BsConst_Compensation_Line_Slope_m
            OA_rp_CS_MemAbsGet_Get_BsConst_Compensation_Line_Shift_b: operation=rp_CS_MemAbsGet.Get_BsConst_Compensation_Line_Shift_b
            OA_rp_CS_MemAbsGet_Get_BsConst_Lookup_Curve_HotSpot_Coef_X: operation=rp_CS_MemAbsGet.Get_BsConst_Lookup_Curve_HotSpot_Coef_X
            OA_rp_CS_MemAbsGet_Get_BsConst_Lookup_Curve_HotSpot_Coef_Y: operation=rp_CS_MemAbsGet.Get_BsConst_Lookup_Curve_HotSpot_Coef_Y
            OA_rp_CS_MemAbsGet_Get_BsConst_Temp_Threshold_Hysteresis_Derating: operation=rp_CS_MemAbsGet.Get_BsConst_Temp_Threshold_Hysteresis_Derating
            OA_rp_CS_MemAbsGet_Get_BsConst_Derating_Backlight_Disable: operation=rp_CS_MemAbsGet.Get_BsConst_Derating_Backlight_Disable
            OA_rp_CS_MemAbsGet_Get_BsConst_Temperature_Sensor_Conv: operation=rp_CS_MemAbsGet.Get_BsConst_Temperature_Sensor_Conv
            OA_rp_CS_MemAbsGet_Get_BsConst_PCB_Temperature_Sensor_Conv: operation=rp_CS_MemAbsGet.Get_BsConst_PCB_Temperature_Sensor_Conv
            OA_rp_CS_MemAbsGet_Get_BsConst_Display_Illum_Max_Level: operation=rp_CS_MemAbsGet.Get_BsConst_Display_Illum_Max_Level
            OA_rp_CS_MemAbsGet_Get_BsConst_PWM_boost_bypass_duty: operation=rp_CS_MemAbsGet.Get_BsConst_PWM_boost_bypass_duty
            OA_rp_CS_MemAbsGet_Get_BsConst_BsConst_Illumination_ReservedByte: operation=rp_CS_MemAbsGet.Get_BsConst_BsConst_Illumination_ReservedByte
            OA_rp_CS_MemAbsGet_Get_BsConst_Compensation_Line_Slope_m_SafeCopy1: operation=rp_CS_MemAbsGet.Get_BsConst_Compensation_Line_Slope_m_SafeCopy1
            OA_rp_CS_MemAbsGet_Get_BsConst_Compensation_Line_Shift_b_SafeCopy1: operation=rp_CS_MemAbsGet.Get_BsConst_Compensation_Line_Shift_b_SafeCopy1
            OA_rp_CS_MemAbsGet_Get_BsConst_Lookup_Curve_HotSpot_Coef_X_SafeCopy1: operation=rp_CS_MemAbsGet.Get_BsConst_Lookup_Curve_HotSpot_Coef_X_SafeCopy1
            OA_rp_CS_MemAbsGet_Get_BsConst_Lookup_Curve_HotSpot_Coef_Y_SafeCopy1: operation=rp_CS_MemAbsGet.Get_BsConst_Lookup_Curve_HotSpot_Coef_Y_SafeCopy1
            OA_rp_CS_MemAbsGet_Get_BsConst_Temp_Threshold_Hysteresis_Derating_SafeCopy1: operation=rp_CS_MemAbsGet.Get_BsConst_Temp_Threshold_Hysteresis_Derating_SafeCopy1
            OA_rp_CS_MemAbsGet_Get_BsConst_Derating_Backlight_Disable_SafeCopy1: operation=rp_CS_MemAbsGet.Get_BsConst_Derating_Backlight_Disable_SafeCopy1
            OA_rp_CS_MemAbsGet_Get_BsConst_Temperature_Sensor_Conv_SafeCopy1: operation=rp_CS_MemAbsGet.Get_BsConst_Temperature_Sensor_Conv_SafeCopy1
            OA_rp_CS_MemAbsGet_Get_BsConst_PCB_Temperature_Sensor_Conv_SafeCopy1: operation=rp_CS_MemAbsGet.Get_BsConst_PCB_Temperature_Sensor_Conv_SafeCopy1
            OA_rp_CS_MemAbsGet_Get_BsConst_Display_Illum_Max_Level_SafeCopy1: operation=rp_CS_MemAbsGet.Get_BsConst_Display_Illum_Max_Level_SafeCopy1
            OA_rp_CS_MemAbsGet_Get_BsConst_PWM_boost_bypass_duty_SafeCopy1: operation=rp_CS_MemAbsGet.Get_BsConst_PWM_boost_bypass_duty_SafeCopy1
            OA_rp_CS_MemAbsGet_Get_BsConst_BsConst_Illumination_ReservedByte_SafeCopy1: operation=rp_CS_MemAbsGet.Get_BsConst_BsConst_Illumination_ReservedByte_SafeCopy1
            OA_rp_CS_MemAbsGet_Get_BsConst_Compensation_Line_Slope_m_SafeCopy2: operation=rp_CS_MemAbsGet.Get_BsConst_Compensation_Line_Slope_m_SafeCopy2
            OA_rp_CS_MemAbsGet_Get_BsConst_Compensation_Line_Shift_b_SafeCopy2: operation=rp_CS_MemAbsGet.Get_BsConst_Compensation_Line_Shift_b_SafeCopy2
            OA_rp_CS_MemAbsGet_Get_BsConst_Lookup_Curve_HotSpot_Coef_X_SafeCopy2: operation=rp_CS_MemAbsGet.Get_BsConst_Lookup_Curve_HotSpot_Coef_X_SafeCopy2
            OA_rp_CS_MemAbsGet_Get_BsConst_Lookup_Curve_HotSpot_Coef_Y_SafeCopy2: operation=rp_CS_MemAbsGet.Get_BsConst_Lookup_Curve_HotSpot_Coef_Y_SafeCopy2
            OA_rp_CS_MemAbsGet_Get_BsConst_Temp_Threshold_Hysteresis_Derating_SafeCopy2: operation=rp_CS_MemAbsGet.Get_BsConst_Temp_Threshold_Hysteresis_Derating_SafeCopy2
            OA_rp_CS_MemAbsGet_Get_BsConst_Derating_Backlight_Disable_SafeCopy2: operation=rp_CS_MemAbsGet.Get_BsConst_Derating_Backlight_Disable_SafeCopy2
            OA_rp_CS_MemAbsGet_Get_BsConst_Temperature_Sensor_Conv_SafeCopy2: operation=rp_CS_MemAbsGet.Get_BsConst_Temperature_Sensor_Conv_SafeCopy2
            OA_rp_CS_MemAbsGet_Get_BsConst_PCB_Temperature_Sensor_Conv_SafeCopy2: operation=rp_CS_MemAbsGet.Get_BsConst_PCB_Temperature_Sensor_Conv_SafeCopy2
            OA_rp_CS_MemAbsGet_Get_BsConst_Display_Illum_Max_Level_SafeCopy2: operation=rp_CS_MemAbsGet.Get_BsConst_Display_Illum_Max_Level_SafeCopy2
            OA_rp_CS_MemAbsGet_Get_BsConst_PWM_boost_bypass_duty_SafeCopy2: operation=rp_CS_MemAbsGet.Get_BsConst_PWM_boost_bypass_duty_SafeCopy2
            OA_rp_CS_MemAbsGet_Get_BsConst_BsConst_Illumination_ReservedByte_SafeCopy2: operation=rp_CS_MemAbsGet.Get_BsConst_BsConst_Illumination_ReservedByte_SafeCopy2
            OA_rp_CS_MemAbsGet_Get_BsConst_Audio_Element: operation=rp_CS_MemAbsGet.Get_BsConst_Audio_Element
            OA_rp_CS_MemAbsGet_Get_BsConst_Warning_Element: operation=rp_CS_MemAbsGet.Get_BsConst_Warning_Element
            OA_rp_CS_MemAbsGet_Get_BsConst_RealTimeClock_Element: operation=rp_CS_MemAbsGet.Get_BsConst_RealTimeClock_Element
            OA_rp_CS_MemAbsGet_Get_BsConst_Communication_Element: operation=rp_CS_MemAbsGet.Get_BsConst_Communication_Element
            OA_rp_CS_MemAbsGet_Get_BsConst_Power_Element: operation=rp_CS_MemAbsGet.Get_BsConst_Power_Element
            OA_rp_CS_MemAbsGet_Get_BsConst_ServiceReminder_Element: operation=rp_CS_MemAbsGet.Get_BsConst_ServiceReminder_Element
            OA_rp_CS_MemAbsGet_Get_BsConst_EngOffTimer_Element: operation=rp_CS_MemAbsGet.Get_BsConst_EngOffTimer_Element
            OA_rp_CS_MemAbsGet_Get_BsCys_Certicificate_Element: operation=rp_CS_MemAbsGet.Get_BsCys_Certicificate_Element
            OA_rp_CS_MemAbsGet_Get_RefCys_Certicificate_Element: operation=rp_CS_MemAbsGet.Get_RefCys_Certicificate_Element
            OA_rp_CS_MemAbsGet_Get_RefCys_Certicificate1_Element: operation=rp_CS_MemAbsGet.Get_RefCys_Certicificate1_Element
            OA_rp_CS_MemAbsGet_Get_BsRt_Odometer_Element: operation=rp_CS_MemAbsGet.Get_BsRt_Odometer_Element
            OA_rp_CS_MemAbsGet_Get_BsRt_SpeedoGauge_Element: operation=rp_CS_MemAbsGet.Get_BsRt_SpeedoGauge_Element
            OA_rp_CS_MemAbsGet_Get_BsRt_TachoGauge_Element: operation=rp_CS_MemAbsGet.Get_BsRt_TachoGauge_Element
            OA_rp_CS_MemAbsGet_Get_BsRt_FuelGauge_Element: operation=rp_CS_MemAbsGet.Get_BsRt_FuelGauge_Element
            OA_rp_CS_MemAbsGet_Get_BsRt_TempGauge_Element: operation=rp_CS_MemAbsGet.Get_BsRt_TempGauge_Element
            OA_rp_CS_MemAbsGet_Get_BsRt_PowerGauge_Element: operation=rp_CS_MemAbsGet.Get_BsRt_PowerGauge_Element
            OA_rp_CS_MemAbsGet_Get_BsRt_OilGauge_Element: operation=rp_CS_MemAbsGet.Get_BsRt_OilGauge_Element
            OA_rp_CS_MemAbsGet_Get_BsRt_TripComputer_Element: operation=rp_CS_MemAbsGet.Get_BsRt_TripComputer_Element
            OA_rp_CS_MemAbsGet_Get_BsRt_Warning_Element: operation=rp_CS_MemAbsGet.Get_BsRt_Warning_Element
            OA_rp_CS_MemAbsGet_Get_BsRt_RealTimeClock_Element: operation=rp_CS_MemAbsGet.Get_BsRt_RealTimeClock_Element
            OA_rp_CS_MemAbsGet_Get_BsRt_Personalization_Element: operation=rp_CS_MemAbsGet.Get_BsRt_Personalization_Element
            OA_rp_CS_MemAbsGet_Get_BsRt_Illumination_Element: operation=rp_CS_MemAbsGet.Get_BsRt_Illumination_Element
            OA_rp_CS_MemAbsGet_Get_BsRt_CusDlt_Element: operation=rp_CS_MemAbsGet.Get_BsRt_CusDlt_Element
            OA_rp_CS_MemAbsGet_Get_BsReten_Odometer_Element: operation=rp_CS_MemAbsGet.Get_BsReten_Odometer_Element
            OA_rp_CS_MemAbsGet_Get_BsReten_Gauges_Element: operation=rp_CS_MemAbsGet.Get_BsReten_Gauges_Element
            OA_rp_CS_MemAbsGet_Get_BsReten_Tripcomputer_Element: operation=rp_CS_MemAbsGet.Get_BsReten_Tripcomputer_Element
            OA_rp_CS_MemAbsGet_Get_BsReten_Illumination_Element: operation=rp_CS_MemAbsGet.Get_BsReten_Illumination_Element
            OA_rp_CS_MemAbsGet_Get_BsReten_Audio_Element: operation=rp_CS_MemAbsGet.Get_BsReten_Audio_Element
            OA_rp_CS_MemAbsGet_Get_BsReten_Warning_Element: operation=rp_CS_MemAbsGet.Get_BsReten_Warning_Element
            OA_rp_CS_MemAbsGet_Get_BsReten_RealTimeClock_Element: operation=rp_CS_MemAbsGet.Get_BsReten_RealTimeClock_Element
            OA_rp_CS_MemAbsGet_Get_BsReten_Communication_Element: operation=rp_CS_MemAbsGet.Get_BsReten_Communication_Element
            OA_rp_CS_MemAbsGet_Get_BsReten_Personalization_Element: operation=rp_CS_MemAbsGet.Get_BsReten_Personalization_Element
            OA_rp_CS_MemAbsGet_Get_BsReten_Power_Element: operation=rp_CS_MemAbsGet.Get_BsReten_Power_Element
            OA_rp_CS_MemAbsGet_Get_BsReten_Display_Element: operation=rp_CS_MemAbsGet.Get_BsReten_Display_Element
            OA_rp_CS_MemAbsGet_Get_BsDiag_ErrorRecord_Element: operation=rp_CS_MemAbsGet.Get_BsDiag_ErrorRecord_Element
            OA_rp_CS_MemAbsGet_Get_BsDiag_Dtc_Element: operation=rp_CS_MemAbsGet.Get_BsDiag_Dtc_Element
        CComAbsMdlSafe_Impl_TxCanMdlSafeMainFunction
        CComAbsMdlSafe_RxCan_GetSignalValue
        CComAbsMdlSafe_RxCan_GetSignalValueU8Arr
        CComAbsMdlSafe_RxCan_SetSignalInitValue
        CComAbsMdlSafe_RxCan_SetSignalInitValueU8Arr
        CComAbsMdlSafe_RxCan_SignalClearJustRcvdStatus
        CComAbsMdlSafe_RxCan_SignalGetJustRcvdStatus
        CComAbsMdlSafe_RxCan_SignalInvalidProcessingControl
        CComAbsMdlSafe_RxCan_SignalMissingProcessingControl
        CComAbsMdlSafe_RxCan_SignalNRProcessingControl
        CComAbsMdlSafe_TxCan_ClearCanSignalTxConfirmation
        CComAbsMdlSafe_TxCan_GetCanSignalTxConfirmation
        CComAbsMdlSafe_TxCan_SetSignalFromRetentionBuffer
        CComAbsMdlSafe_TxCan_SetSignalValue
        CComAbsMdlSafe_TxCan_SetSignalValueU8Arr
  swc implementation IMPL_CComAbsMdlSafe: programming-language=C, behavior=IB_CComAbsMdlSafe
    code-descriptors:
      code CodeDescriptor
